VERSION ""

NS_ :

BS_:

BU_: R_STR IAVAS ADAS ADAS_GW ENM THM CHR BAT BEV BEV_GW LCT STA ABG EPS IPMS BST VDC C_ECU C_ECU_GW

BO_ 2564481198 DMS18DAE0AE: 64 IPMS
 SG_ DMS18DAE0AE_DIAG_DATA_EXT7 : 455|64@0+ (1,0) [0|1.844674407371E+19] ""  C_ECU_GW
 SG_ DMS18DAE0AE_DIAG_DATA_EXT6 : 391|64@0+ (1,0) [0|1.844674407371E+19] ""  C_ECU_GW
 SG_ DMS18DAE0AE_DIAG_DATA_EXT5 : 327|64@0+ (1,0) [0|1.844674407371E+19] ""  C_ECU_GW
 SG_ DMS18DAE0AE_DIAG_DATA_EXT4 : 263|64@0+ (1,0) [0|1.844674407371E+19] ""  C_ECU_GW
 SG_ DMS18DAE0AE_DIAG_DATA_EXT3 : 199|64@0+ (1,0) [0|1.844674407371E+19] ""  C_ECU_GW
 SG_ DMS18DAE0AE_DIAG_DATA_EXT2 : 135|64@0+ (1,0) [0|1.844674407371E+19] ""  C_ECU_GW
 SG_ DMS18DAE0AE_DIAG_DATA_EXT1 : 71|64@0+ (1,0) [0|1.844674407371E+19] ""  C_ECU_GW
 SG_ DMS18DAE0AE_DIAG_DATA : 7|64@0+ (1,0) [0|1.844674407371E+19] ""  C_ECU_GW

BO_ 2564468448 DNT18DAAEE0: 64 C_ECU_GW
 SG_ DNT18DAAEE0_DIAG_DATA_EXT7 : 455|64@0+ (1,0) [0|1.844674407371E+19] ""  IPMS
 SG_ DNT18DAAEE0_DIAG_DATA_EXT6 : 391|64@0+ (1,0) [0|1.844674407371E+19] ""  IPMS
 SG_ DNT18DAAEE0_DIAG_DATA_EXT5 : 327|64@0+ (1,0) [0|1.844674407371E+19] ""  IPMS
 SG_ DNT18DAAEE0_DIAG_DATA_EXT4 : 263|64@0+ (1,0) [0|1.844674407371E+19] ""  IPMS
 SG_ DNT18DAAEE0_DIAG_DATA_EXT3 : 199|64@0+ (1,0) [0|1.844674407371E+19] ""  IPMS
 SG_ DNT18DAAEE0_DIAG_DATA_EXT2 : 135|64@0+ (1,0) [0|1.844674407371E+19] ""  IPMS
 SG_ DNT18DAAEE0_DIAG_DATA_EXT1 : 71|64@0+ (1,0) [0|1.844674407371E+19] ""  IPMS
 SG_ DNT18DAAEE0_DIAG_DATA : 7|64@0+ (1,0) [0|1.844674407371E+19] ""  IPMS

BO_ 2564481036 BST18DAE00C: 64 BST
 SG_ BST18DAE00C_DIAG_DATA_EXT7 : 455|64@0+ (1,0) [0|1.844674407371E+19] ""  C_ECU_GW
 SG_ BST18DAE00C_DIAG_DATA_EXT6 : 391|64@0+ (1,0) [0|1.844674407371E+19] ""  C_ECU_GW
 SG_ BST18DAE00C_DIAG_DATA_EXT5 : 327|64@0+ (1,0) [0|1.844674407371E+19] ""  C_ECU_GW
 SG_ BST18DAE00C_DIAG_DATA_EXT4 : 263|64@0+ (1,0) [0|1.844674407371E+19] ""  C_ECU_GW
 SG_ BST18DAE00C_DIAG_DATA_EXT3 : 199|64@0+ (1,0) [0|1.844674407371E+19] ""  C_ECU_GW
 SG_ BST18DAE00C_DIAG_DATA_EXT2 : 135|64@0+ (1,0) [0|1.844674407371E+19] ""  C_ECU_GW
 SG_ BST18DAE00C_DIAG_DATA_EXT1 : 71|64@0+ (1,0) [0|1.844674407371E+19] ""  C_ECU_GW
 SG_ BST18DAE00C_DIAG_DATA : 7|64@0+ (1,0) [0|1.844674407371E+19] ""  C_ECU_GW

BO_ 2564426976 DNT18DA0CE0: 64 C_ECU_GW
 SG_ DNT18DA0CE0_DIAG_DATA_EXT7 : 455|64@0+ (1,0) [0|1.844674407371E+19] ""  BST
 SG_ DNT18DA0CE0_DIAG_DATA_EXT6 : 391|64@0+ (1,0) [0|1.844674407371E+19] ""  BST
 SG_ DNT18DA0CE0_DIAG_DATA_EXT5 : 327|64@0+ (1,0) [0|1.844674407371E+19] ""  BST
 SG_ DNT18DA0CE0_DIAG_DATA_EXT4 : 263|64@0+ (1,0) [0|1.844674407371E+19] ""  BST
 SG_ DNT18DA0CE0_DIAG_DATA_EXT3 : 199|64@0+ (1,0) [0|1.844674407371E+19] ""  BST
 SG_ DNT18DA0CE0_DIAG_DATA_EXT2 : 135|64@0+ (1,0) [0|1.844674407371E+19] ""  BST
 SG_ DNT18DA0CE0_DIAG_DATA_EXT1 : 71|64@0+ (1,0) [0|1.844674407371E+19] ""  BST
 SG_ DNT18DA0CE0_DIAG_DATA : 7|64@0+ (1,0) [0|1.844674407371E+19] ""  BST

BO_ 2564481153 MCA18DAE081: 64 ADAS_GW
 SG_ MCA18DAE081_DIAG_DATA_EXT7 : 455|64@0+ (1,0) [0|1.844674407371E+19] ""  C_ECU_GW
 SG_ MCA18DAE081_DIAG_DATA_EXT6 : 391|64@0+ (1,0) [0|1.844674407371E+19] ""  C_ECU_GW
 SG_ MCA18DAE081_DIAG_DATA_EXT5 : 327|64@0+ (1,0) [0|1.844674407371E+19] ""  C_ECU_GW
 SG_ MCA18DAE081_DIAG_DATA_EXT4 : 263|64@0+ (1,0) [0|1.844674407371E+19] ""  C_ECU_GW
 SG_ MCA18DAE081_DIAG_DATA_EXT3 : 199|64@0+ (1,0) [0|1.844674407371E+19] ""  C_ECU_GW
 SG_ MCA18DAE081_DIAG_DATA_EXT2 : 135|64@0+ (1,0) [0|1.844674407371E+19] ""  C_ECU_GW
 SG_ MCA18DAE081_DIAG_DATA_EXT1 : 71|64@0+ (1,0) [0|1.844674407371E+19] ""  C_ECU_GW
 SG_ MCA18DAE081_DIAG_DATA : 7|64@0+ (1,0) [0|1.844674407371E+19] ""  C_ECU_GW

BO_ 2564456928 DNT18DA81E0: 64 C_ECU_GW
 SG_ DNT18DA81E0_DIAG_DATA_EXT7 : 455|64@0+ (1,0) [0|1.844674407371E+19] ""  ADAS_GW
 SG_ DNT18DA81E0_DIAG_DATA_EXT6 : 391|64@0+ (1,0) [0|1.844674407371E+19] ""  ADAS_GW
 SG_ DNT18DA81E0_DIAG_DATA_EXT5 : 327|64@0+ (1,0) [0|1.844674407371E+19] ""  ADAS_GW
 SG_ DNT18DA81E0_DIAG_DATA_EXT4 : 263|64@0+ (1,0) [0|1.844674407371E+19] ""  ADAS_GW
 SG_ DNT18DA81E0_DIAG_DATA_EXT3 : 199|64@0+ (1,0) [0|1.844674407371E+19] ""  ADAS_GW
 SG_ DNT18DA81E0_DIAG_DATA_EXT2 : 135|64@0+ (1,0) [0|1.844674407371E+19] ""  ADAS_GW
 SG_ DNT18DA81E0_DIAG_DATA_EXT1 : 71|64@0+ (1,0) [0|1.844674407371E+19] ""  ADAS_GW
 SG_ DNT18DA81E0_DIAG_DATA : 7|64@0+ (1,0) [0|1.844674407371E+19] ""  ADAS_GW

BO_ 2564481154 FCRL18DAE082: 64 ADAS_GW
 SG_ FCRL18DAE082_DIAG_DATA_EXT7 : 455|64@0+ (1,0) [0|1.844674407371E+19] ""  C_ECU_GW
 SG_ FCRL18DAE082_DIAG_DATA_EXT6 : 391|64@0+ (1,0) [0|1.844674407371E+19] ""  C_ECU_GW
 SG_ FCRL18DAE082_DIAG_DATA_EXT5 : 327|64@0+ (1,0) [0|1.844674407371E+19] ""  C_ECU_GW
 SG_ FCRL18DAE082_DIAG_DATA_EXT4 : 263|64@0+ (1,0) [0|1.844674407371E+19] ""  C_ECU_GW
 SG_ FCRL18DAE082_DIAG_DATA_EXT3 : 199|64@0+ (1,0) [0|1.844674407371E+19] ""  C_ECU_GW
 SG_ FCRL18DAE082_DIAG_DATA_EXT2 : 135|64@0+ (1,0) [0|1.844674407371E+19] ""  C_ECU_GW
 SG_ FCRL18DAE082_DIAG_DATA_EXT1 : 71|64@0+ (1,0) [0|1.844674407371E+19] ""  C_ECU_GW
 SG_ FCRL18DAE082_DIAG_DATA : 7|64@0+ (1,0) [0|1.844674407371E+19] ""  C_ECU_GW

BO_ 2564457184 DNT18DA82E0: 64 C_ECU_GW
 SG_ DNT18DA82E0_DIAG_DATA_EXT7 : 455|64@0+ (1,0) [0|1.844674407371E+19] ""  ADAS_GW
 SG_ DNT18DA82E0_DIAG_DATA_EXT6 : 391|64@0+ (1,0) [0|1.844674407371E+19] ""  ADAS_GW
 SG_ DNT18DA82E0_DIAG_DATA_EXT5 : 327|64@0+ (1,0) [0|1.844674407371E+19] ""  ADAS_GW
 SG_ DNT18DA82E0_DIAG_DATA_EXT4 : 263|64@0+ (1,0) [0|1.844674407371E+19] ""  ADAS_GW
 SG_ DNT18DA82E0_DIAG_DATA_EXT3 : 199|64@0+ (1,0) [0|1.844674407371E+19] ""  ADAS_GW
 SG_ DNT18DA82E0_DIAG_DATA_EXT2 : 135|64@0+ (1,0) [0|1.844674407371E+19] ""  ADAS_GW
 SG_ DNT18DA82E0_DIAG_DATA_EXT1 : 71|64@0+ (1,0) [0|1.844674407371E+19] ""  ADAS_GW
 SG_ DNT18DA82E0_DIAG_DATA : 7|64@0+ (1,0) [0|1.844674407371E+19] ""  ADAS_GW

BO_ 2564481155 FCRR18DAE083: 64 ADAS_GW
 SG_ FCRR18DAE083_DIAG_DATA_EXT7 : 455|64@0+ (1,0) [0|1.844674407371E+19] ""  C_ECU_GW
 SG_ FCRR18DAE083_DIAG_DATA_EXT6 : 391|64@0+ (1,0) [0|1.844674407371E+19] ""  C_ECU_GW
 SG_ FCRR18DAE083_DIAG_DATA_EXT5 : 327|64@0+ (1,0) [0|1.844674407371E+19] ""  C_ECU_GW
 SG_ FCRR18DAE083_DIAG_DATA_EXT4 : 263|64@0+ (1,0) [0|1.844674407371E+19] ""  C_ECU_GW
 SG_ FCRR18DAE083_DIAG_DATA_EXT3 : 199|64@0+ (1,0) [0|1.844674407371E+19] ""  C_ECU_GW
 SG_ FCRR18DAE083_DIAG_DATA_EXT2 : 135|64@0+ (1,0) [0|1.844674407371E+19] ""  C_ECU_GW
 SG_ FCRR18DAE083_DIAG_DATA_EXT1 : 71|64@0+ (1,0) [0|1.844674407371E+19] ""  C_ECU_GW
 SG_ FCRR18DAE083_DIAG_DATA : 7|64@0+ (1,0) [0|1.844674407371E+19] ""  C_ECU_GW

BO_ 2564457440 DNT18DA83E0: 64 C_ECU_GW
 SG_ DNT18DA83E0_DIAG_DATA_EXT7 : 455|64@0+ (1,0) [0|1.844674407371E+19] ""  ADAS_GW
 SG_ DNT18DA83E0_DIAG_DATA_EXT6 : 391|64@0+ (1,0) [0|1.844674407371E+19] ""  ADAS_GW
 SG_ DNT18DA83E0_DIAG_DATA_EXT5 : 327|64@0+ (1,0) [0|1.844674407371E+19] ""  ADAS_GW
 SG_ DNT18DA83E0_DIAG_DATA_EXT4 : 263|64@0+ (1,0) [0|1.844674407371E+19] ""  ADAS_GW
 SG_ DNT18DA83E0_DIAG_DATA_EXT3 : 199|64@0+ (1,0) [0|1.844674407371E+19] ""  ADAS_GW
 SG_ DNT18DA83E0_DIAG_DATA_EXT2 : 135|64@0+ (1,0) [0|1.844674407371E+19] ""  ADAS_GW
 SG_ DNT18DA83E0_DIAG_DATA_EXT1 : 71|64@0+ (1,0) [0|1.844674407371E+19] ""  ADAS_GW
 SG_ DNT18DA83E0_DIAG_DATA : 7|64@0+ (1,0) [0|1.844674407371E+19] ""  ADAS_GW

BO_ 2564481107 ABG18DAE053: 8 ABG
 SG_ ABG18DAE053_DIAG_DATA : 7|64@0+ (1,0) [0|1.844674407371E+19] ""  C_ECU_GW

BO_ 2564445152 DNT18DA53E0: 8 C_ECU_GW
 SG_ DNT18DA53E0_DIAG_DATA : 7|64@0+ (1,0) [0|1.844674407371E+19] ""  ABG

BO_ 2564481101 STA18DAE04D: 64 STA
 SG_ STA18DAE04D_DIAG_DATA_EXT7 : 455|64@0+ (1,0) [0|1.844674407371E+19] ""  C_ECU_GW
 SG_ STA18DAE04D_DIAG_DATA_EXT6 : 391|64@0+ (1,0) [0|1.844674407371E+19] ""  C_ECU_GW
 SG_ STA18DAE04D_DIAG_DATA_EXT5 : 327|64@0+ (1,0) [0|1.844674407371E+19] ""  C_ECU_GW
 SG_ STA18DAE04D_DIAG_DATA_EXT4 : 263|64@0+ (1,0) [0|1.844674407371E+19] ""  C_ECU_GW
 SG_ STA18DAE04D_DIAG_DATA_EXT3 : 199|64@0+ (1,0) [0|1.844674407371E+19] ""  C_ECU_GW
 SG_ STA18DAE04D_DIAG_DATA_EXT2 : 135|64@0+ (1,0) [0|1.844674407371E+19] ""  C_ECU_GW
 SG_ STA18DAE04D_DIAG_DATA_EXT1 : 71|64@0+ (1,0) [0|1.844674407371E+19] ""  C_ECU_GW
 SG_ STA18DAE04D_DIAG_DATA : 7|64@0+ (1,0) [0|1.844674407371E+19] ""  C_ECU_GW

BO_ 2564443616 DNT18DA4DE0: 64 C_ECU_GW
 SG_ DNT18DA4DE0_DIAG_DATA_EXT7 : 455|64@0+ (1,0) [0|1.844674407371E+19] ""  STA
 SG_ DNT18DA4DE0_DIAG_DATA_EXT6 : 391|64@0+ (1,0) [0|1.844674407371E+19] ""  STA
 SG_ DNT18DA4DE0_DIAG_DATA_EXT5 : 327|64@0+ (1,0) [0|1.844674407371E+19] ""  STA
 SG_ DNT18DA4DE0_DIAG_DATA_EXT4 : 263|64@0+ (1,0) [0|1.844674407371E+19] ""  STA
 SG_ DNT18DA4DE0_DIAG_DATA_EXT3 : 199|64@0+ (1,0) [0|1.844674407371E+19] ""  STA
 SG_ DNT18DA4DE0_DIAG_DATA_EXT2 : 135|64@0+ (1,0) [0|1.844674407371E+19] ""  STA
 SG_ DNT18DA4DE0_DIAG_DATA_EXT1 : 71|64@0+ (1,0) [0|1.844674407371E+19] ""  STA
 SG_ DNT18DA4DE0_DIAG_DATA : 7|64@0+ (1,0) [0|1.844674407371E+19] ""  STA

BO_ 2564481043 EPS18DAE013: 8 EPS
 SG_ EPS18DAE013_DIAG_DATA_EXT7 : 455|64@0+ (1,0) [0|1.844674407371E+19] ""  C_ECU_GW
 SG_ EPS18DAE013_DIAG_DATA_EXT6 : 391|64@0+ (1,0) [0|1.844674407371E+19] ""  C_ECU_GW
 SG_ EPS18DAE013_DIAG_DATA_EXT5 : 327|64@0+ (1,0) [0|1.844674407371E+19] ""  C_ECU_GW
 SG_ EPS18DAE013_DIAG_DATA_EXT4 : 263|64@0+ (1,0) [0|1.844674407371E+19] ""  C_ECU_GW
 SG_ EPS18DAE013_DIAG_DATA_EXT3 : 199|64@0+ (1,0) [0|1.844674407371E+19] ""  C_ECU_GW
 SG_ EPS18DAE013_DIAG_DATA_EXT2 : 135|64@0+ (1,0) [0|1.844674407371E+19] ""  C_ECU_GW
 SG_ EPS18DAE013_DIAG_DATA_EXT1 : 71|64@0+ (1,0) [0|1.844674407371E+19] ""  C_ECU_GW
 SG_ EPS18DAE013_DIAG_DATA : 7|64@0+ (1,0) [0|1.844674407371E+19] ""  C_ECU_GW

BO_ 2564428768 DNT18DA13E0: 8 C_ECU_GW
 SG_ DNT18DA13E0_DIAG_DATA_EXT7 : 455|64@0+ (1,0) [0|1.844674407371E+19] "" Vector__XXX
 SG_ DNT18DA13E0_DIAG_DATA_EXT6 : 391|64@0+ (1,0) [0|1.844674407371E+19] "" Vector__XXX
 SG_ DNT18DA13E0_DIAG_DATA_EXT5 : 327|64@0+ (1,0) [0|1.844674407371E+19] "" Vector__XXX
 SG_ DNT18DA13E0_DIAG_DATA_EXT4 : 263|64@0+ (1,0) [0|1.844674407371E+19] "" Vector__XXX
 SG_ DNT18DA13E0_DIAG_DATA_EXT3 : 199|64@0+ (1,0) [0|1.844674407371E+19] "" Vector__XXX
 SG_ DNT18DA13E0_DIAG_DATA_EXT2 : 135|64@0+ (1,0) [0|1.844674407371E+19] "" Vector__XXX
 SG_ DNT18DA13E0_DIAG_DATA_EXT1 : 71|64@0+ (1,0) [0|1.844674407371E+19] "" Vector__XXX
 SG_ DNT18DA13E0_DIAG_DATA : 7|64@0+ (1,0) [0|1.844674407371E+19] ""  EPS

BO_ 2564481035 VDC18DAE00B: 64 VDC
 SG_ VDC18DAE00B_DIAG_DATA_EXT7 : 455|64@0+ (1,0) [0|1.844674407371E+19] ""  C_ECU_GW
 SG_ VDC18DAE00B_DIAG_DATA_EXT6 : 391|64@0+ (1,0) [0|1.844674407371E+19] ""  C_ECU_GW
 SG_ VDC18DAE00B_DIAG_DATA_EXT5 : 327|64@0+ (1,0) [0|1.844674407371E+19] ""  C_ECU_GW
 SG_ VDC18DAE00B_DIAG_DATA_EXT4 : 263|64@0+ (1,0) [0|1.844674407371E+19] ""  C_ECU_GW
 SG_ VDC18DAE00B_DIAG_DATA_EXT3 : 199|64@0+ (1,0) [0|1.844674407371E+19] ""  C_ECU_GW
 SG_ VDC18DAE00B_DIAG_DATA_EXT2 : 135|64@0+ (1,0) [0|1.844674407371E+19] ""  C_ECU_GW
 SG_ VDC18DAE00B_DIAG_DATA_EXT1 : 71|64@0+ (1,0) [0|1.844674407371E+19] ""  C_ECU_GW
 SG_ VDC18DAE00B_DIAG_DATA : 7|64@0+ (1,0) [0|1.844674407371E+19] ""  C_ECU_GW

BO_ 2564426720 DNT18DA0BE0: 64 C_ECU_GW
 SG_ DNT18DA0BE0_DIAG_DATA_EXT7 : 455|64@0+ (1,0) [0|1.844674407371E+19] ""  VDC
 SG_ DNT18DA0BE0_DIAG_DATA_EXT6 : 391|64@0+ (1,0) [0|1.844674407371E+19] ""  VDC
 SG_ DNT18DA0BE0_DIAG_DATA_EXT5 : 327|64@0+ (1,0) [0|1.844674407371E+19] ""  VDC
 SG_ DNT18DA0BE0_DIAG_DATA_EXT4 : 263|64@0+ (1,0) [0|1.844674407371E+19] ""  VDC
 SG_ DNT18DA0BE0_DIAG_DATA_EXT3 : 199|64@0+ (1,0) [0|1.844674407371E+19] ""  VDC
 SG_ DNT18DA0BE0_DIAG_DATA_EXT2 : 135|64@0+ (1,0) [0|1.844674407371E+19] ""  VDC
 SG_ DNT18DA0BE0_DIAG_DATA_EXT1 : 71|64@0+ (1,0) [0|1.844674407371E+19] ""  VDC
 SG_ DNT18DA0BE0_DIAG_DATA : 7|64@0+ (1,0) [0|1.844674407371E+19] ""  VDC

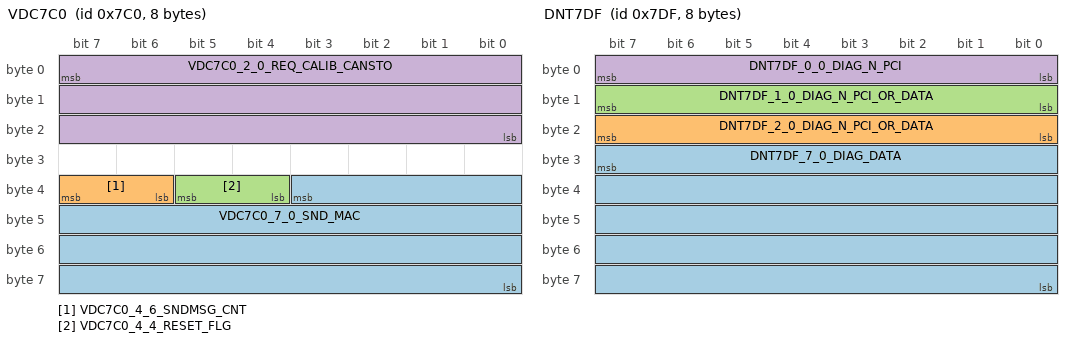
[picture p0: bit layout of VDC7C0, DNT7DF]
BO_ 1984 VDC7C0: 8 VDC
 SG_ VDC7C0_7_0_SND_MAC : 35|28@0+ (1,0) [0|268435455] ""  STA
 SG_ VDC7C0_4_6_SNDMSG_CNT : 39|2@0+ (1,0) [0|3] ""  STA
 SG_ VDC7C0_4_4_RESET_FLG : 37|2@0+ (1,0) [0|3] ""  STA
 SG_ VDC7C0_2_0_REQ_CALIB_CANSTO : 7|24@0+ (1,0) [0|16777215] ""  STA

BO_ 1955 DNT7A3: 8 C_ECU_GW
 SG_ DNT7A3_DIAG_DATA_EXT7 : 455|64@0+ (1,0) [0|1.844674407371E+19] "" Vector__XXX
 SG_ DNT7A3_DIAG_DATA_EXT6 : 391|64@0+ (1,0) [0|1.844674407371E+19] "" Vector__XXX
 SG_ DNT7A3_DIAG_DATA_EXT5 : 327|64@0+ (1,0) [0|1.844674407371E+19] "" Vector__XXX
 SG_ DNT7A3_DIAG_DATA_EXT4 : 263|64@0+ (1,0) [0|1.844674407371E+19] "" Vector__XXX
 SG_ DNT7A3_DIAG_DATA_EXT3 : 199|64@0+ (1,0) [0|1.844674407371E+19] "" Vector__XXX
 SG_ DNT7A3_DIAG_DATA_EXT2 : 135|64@0+ (1,0) [0|1.844674407371E+19] "" Vector__XXX
 SG_ DNT7A3_DIAG_DATA_EXT1 : 71|64@0+ (1,0) [0|1.844674407371E+19] "" Vector__XXX
 SG_ DNT7A3_DIAG_DATA : 7|64@0+ (1,0) [0|1.844674407371E+19] "" Vector__XXX

BO_ 2017 DNT7E1: 8 C_ECU_GW
 SG_ DNT7E1_DIAG_DATA_EXT7 : 455|64@0+ (1,0) [0|1.844674407371E+19] "" Vector__XXX
 SG_ DNT7E1_DIAG_DATA_EXT6 : 391|64@0+ (1,0) [0|1.844674407371E+19] "" Vector__XXX
 SG_ DNT7E1_DIAG_DATA_EXT5 : 327|64@0+ (1,0) [0|1.844674407371E+19] "" Vector__XXX
 SG_ DNT7E1_DIAG_DATA_EXT4 : 263|64@0+ (1,0) [0|1.844674407371E+19] "" Vector__XXX
 SG_ DNT7E1_DIAG_DATA_EXT3 : 199|64@0+ (1,0) [0|1.844674407371E+19] "" Vector__XXX
 SG_ DNT7E1_DIAG_DATA_EXT2 : 135|64@0+ (1,0) [0|1.844674407371E+19] "" Vector__XXX
 SG_ DNT7E1_DIAG_DATA_EXT1 : 71|64@0+ (1,0) [0|1.844674407371E+19] "" Vector__XXX
 SG_ DNT7E1_DIAG_DATA : 7|64@0+ (1,0) [0|1.844674407371E+19] "" Vector__XXX

BO_ 1954 DNT7A2: 8 C_ECU_GW
 SG_ DNT7A2_DIAG_DATA_EXT7 : 455|64@0+ (1,0) [0|1.844674407371E+19] "" Vector__XXX
 SG_ DNT7A2_DIAG_DATA_EXT6 : 391|64@0+ (1,0) [0|1.844674407371E+19] "" Vector__XXX
 SG_ DNT7A2_DIAG_DATA_EXT5 : 327|64@0+ (1,0) [0|1.844674407371E+19] "" Vector__XXX
 SG_ DNT7A2_DIAG_DATA_EXT4 : 263|64@0+ (1,0) [0|1.844674407371E+19] "" Vector__XXX
 SG_ DNT7A2_DIAG_DATA_EXT3 : 199|64@0+ (1,0) [0|1.844674407371E+19] "" Vector__XXX
 SG_ DNT7A2_DIAG_DATA_EXT2 : 135|64@0+ (1,0) [0|1.844674407371E+19] "" Vector__XXX
 SG_ DNT7A2_DIAG_DATA_EXT1 : 71|64@0+ (1,0) [0|1.844674407371E+19] "" Vector__XXX
 SG_ DNT7A2_DIAG_DATA : 7|64@0+ (1,0) [0|1.844674407371E+19] "" Vector__XXX

BO_ 2016 DNT7E0: 8 C_ECU_GW
 SG_ DNT7E0_DIAG_DATA_EXT7 : 455|64@0+ (1,0) [0|1.844674407371E+19] "" Vector__XXX
 SG_ DNT7E0_DIAG_DATA_EXT6 : 391|64@0+ (1,0) [0|1.844674407371E+19] "" Vector__XXX
 SG_ DNT7E0_DIAG_DATA_EXT5 : 327|64@0+ (1,0) [0|1.844674407371E+19] "" Vector__XXX
 SG_ DNT7E0_DIAG_DATA_EXT4 : 263|64@0+ (1,0) [0|1.844674407371E+19] "" Vector__XXX
 SG_ DNT7E0_DIAG_DATA_EXT3 : 199|64@0+ (1,0) [0|1.844674407371E+19] "" Vector__XXX
 SG_ DNT7E0_DIAG_DATA_EXT2 : 135|64@0+ (1,0) [0|1.844674407371E+19] "" Vector__XXX
 SG_ DNT7E0_DIAG_DATA_EXT1 : 71|64@0+ (1,0) [0|1.844674407371E+19] "" Vector__XXX
 SG_ DNT7E0_DIAG_DATA : 7|64@0+ (1,0) [0|1.844674407371E+19] "" Vector__XXX

BO_ 2564550625 CECU18DBEFE1: 8 C_ECU
 SG_ CECU18DBEFE1_DIAG_DATA : 7|64@0+ (1,0) [0|1.844674407371E+19] ""  IAVAS,ADAS,ADAS_GW,BEV,BEV_GW,LCT,STA,IPMS,BST,VDC

BO_ 2564550624 DNT18DBEFE0: 8 C_ECU_GW
 SG_ DNT18DBEFE0_DIAG_DATA : 7|64@0+ (1,0) [0|1.844674407371E+19] ""  ADAS,ADAS_GW,LCT,STA,ABG,EPS,IPMS,BST,VDC

BO_ 2015 DNT7DF: 8 C_ECU_GW
 SG_ DNT7DF_7_0_DIAG_DATA : 31|40@0+ (1,0) [0|1099511627775] "" Vector__XXX
 SG_ DNT7DF_2_0_DIAG_N_PCI_OR_DATA : 23|8@0+ (1,0) [0|255] "" Vector__XXX
 SG_ DNT7DF_1_0_DIAG_N_PCI_OR_DATA : 15|8@0+ (1,0) [0|255] "" Vector__XXX
 SG_ DNT7DF_0_0_DIAG_N_PCI : 7|8@0+ (1,0) [0|255] "" Vector__XXX

BO_ 2564481454 DMS18DAE1AE: 64 IPMS
 SG_ DMS18DAE1AE_DIAG_DATA_EXT7 : 455|64@0+ (1,0) [0|1.844674407371E+19] ""  C_ECU
 SG_ DMS18DAE1AE_DIAG_DATA_EXT6 : 391|64@0+ (1,0) [0|1.844674407371E+19] ""  C_ECU
 SG_ DMS18DAE1AE_DIAG_DATA_EXT5 : 327|64@0+ (1,0) [0|1.844674407371E+19] ""  C_ECU
 SG_ DMS18DAE1AE_DIAG_DATA_EXT4 : 263|64@0+ (1,0) [0|1.844674407371E+19] ""  C_ECU
 SG_ DMS18DAE1AE_DIAG_DATA_EXT3 : 199|64@0+ (1,0) [0|1.844674407371E+19] ""  C_ECU
 SG_ DMS18DAE1AE_DIAG_DATA_EXT2 : 135|64@0+ (1,0) [0|1.844674407371E+19] ""  C_ECU
 SG_ DMS18DAE1AE_DIAG_DATA_EXT1 : 71|64@0+ (1,0) [0|1.844674407371E+19] ""  C_ECU
 SG_ DMS18DAE1AE_DIAG_DATA : 7|64@0+ (1,0) [0|1.844674407371E+19] ""  C_ECU

BO_ 2564468449 CECU18DAAEE1: 64 C_ECU
 SG_ CECU18DAAEE1_DIAG_DATA_EXT7 : 455|64@0+ (1,0) [0|1.844674407371E+19] ""  IPMS
 SG_ CECU18DAAEE1_DIAG_DATA_EXT6 : 391|64@0+ (1,0) [0|1.844674407371E+19] ""  IPMS
 SG_ CECU18DAAEE1_DIAG_DATA_EXT5 : 327|64@0+ (1,0) [0|1.844674407371E+19] ""  IPMS
 SG_ CECU18DAAEE1_DIAG_DATA_EXT4 : 263|64@0+ (1,0) [0|1.844674407371E+19] ""  IPMS
 SG_ CECU18DAAEE1_DIAG_DATA_EXT3 : 199|64@0+ (1,0) [0|1.844674407371E+19] ""  IPMS
 SG_ CECU18DAAEE1_DIAG_DATA_EXT2 : 135|64@0+ (1,0) [0|1.844674407371E+19] ""  IPMS
 SG_ CECU18DAAEE1_DIAG_DATA_EXT1 : 71|64@0+ (1,0) [0|1.844674407371E+19] ""  IPMS
 SG_ CECU18DAAEE1_DIAG_DATA : 7|64@0+ (1,0) [0|1.844674407371E+19] ""  IPMS

BO_ 2564481409 MCA18DAE181: 64 ADAS_GW
 SG_ MCA18DAE181_DIAG_DATA_EXT7 : 455|64@0+ (1,0) [0|1.844674407371E+19] ""  C_ECU
 SG_ MCA18DAE181_DIAG_DATA_EXT6 : 391|64@0+ (1,0) [0|1.844674407371E+19] ""  C_ECU
 SG_ MCA18DAE181_DIAG_DATA_EXT5 : 327|64@0+ (1,0) [0|1.844674407371E+19] ""  C_ECU
 SG_ MCA18DAE181_DIAG_DATA_EXT4 : 263|64@0+ (1,0) [0|1.844674407371E+19] ""  C_ECU
 SG_ MCA18DAE181_DIAG_DATA_EXT3 : 199|64@0+ (1,0) [0|1.844674407371E+19] ""  C_ECU
 SG_ MCA18DAE181_DIAG_DATA_EXT2 : 135|64@0+ (1,0) [0|1.844674407371E+19] ""  C_ECU
 SG_ MCA18DAE181_DIAG_DATA_EXT1 : 71|64@0+ (1,0) [0|1.844674407371E+19] ""  C_ECU
 SG_ MCA18DAE181_DIAG_DATA : 7|64@0+ (1,0) [0|1.844674407371E+19] ""  C_ECU

BO_ 2564456929 CECU18DA81E1: 64 C_ECU
 SG_ CECU18DA81E1_DIAG_DATA_EXT7 : 455|64@0+ (1,0) [0|1.844674407371E+19] ""  ADAS_GW
 SG_ CECU18DA81E1_DIAG_DATA_EXT6 : 391|64@0+ (1,0) [0|1.844674407371E+19] ""  ADAS_GW
 SG_ CECU18DA81E1_DIAG_DATA_EXT5 : 327|64@0+ (1,0) [0|1.844674407371E+19] ""  ADAS_GW
 SG_ CECU18DA81E1_DIAG_DATA_EXT4 : 263|64@0+ (1,0) [0|1.844674407371E+19] ""  ADAS_GW
 SG_ CECU18DA81E1_DIAG_DATA_EXT3 : 199|64@0+ (1,0) [0|1.844674407371E+19] ""  ADAS_GW
 SG_ CECU18DA81E1_DIAG_DATA_EXT2 : 135|64@0+ (1,0) [0|1.844674407371E+19] ""  ADAS_GW
 SG_ CECU18DA81E1_DIAG_DATA_EXT1 : 71|64@0+ (1,0) [0|1.844674407371E+19] ""  ADAS_GW
 SG_ CECU18DA81E1_DIAG_DATA : 7|64@0+ (1,0) [0|1.844674407371E+19] ""  ADAS_GW

BO_ 2564481477 BEV18DAE1C5: 64 BEV
 SG_ BEV18DAE1C5_DIAG_DATA_EXT7 : 455|64@0+ (1,0) [0|1.844674407371E+19] ""  C_ECU
 SG_ BEV18DAE1C5_DIAG_DATA_EXT6 : 391|64@0+ (1,0) [0|1.844674407371E+19] ""  C_ECU
 SG_ BEV18DAE1C5_DIAG_DATA_EXT5 : 327|64@0+ (1,0) [0|1.844674407371E+19] ""  C_ECU
 SG_ BEV18DAE1C5_DIAG_DATA_EXT4 : 263|64@0+ (1,0) [0|1.844674407371E+19] ""  C_ECU
 SG_ BEV18DAE1C5_DIAG_DATA_EXT3 : 199|64@0+ (1,0) [0|1.844674407371E+19] ""  C_ECU
 SG_ BEV18DAE1C5_DIAG_DATA_EXT2 : 135|64@0+ (1,0) [0|1.844674407371E+19] ""  C_ECU
 SG_ BEV18DAE1C5_DIAG_DATA_EXT1 : 71|64@0+ (1,0) [0|1.844674407371E+19] ""  C_ECU
 SG_ BEV18DAE1C5_DIAG_DATA : 7|64@0+ (1,0) [0|1.844674407371E+19] ""  C_ECU

BO_ 2564474337 CECU18DAC5E1: 64 C_ECU
 SG_ CECU18DAC5E1_DIAG_DATA_EXT7 : 455|64@0+ (1,0) [0|1.844674407371E+19] ""  BEV
 SG_ CECU18DAC5E1_DIAG_DATA_EXT6 : 391|64@0+ (1,0) [0|1.844674407371E+19] ""  BEV
 SG_ CECU18DAC5E1_DIAG_DATA_EXT5 : 327|64@0+ (1,0) [0|1.844674407371E+19] ""  BEV
 SG_ CECU18DAC5E1_DIAG_DATA_EXT4 : 263|64@0+ (1,0) [0|1.844674407371E+19] ""  BEV
 SG_ CECU18DAC5E1_DIAG_DATA_EXT3 : 199|64@0+ (1,0) [0|1.844674407371E+19] ""  BEV
 SG_ CECU18DAC5E1_DIAG_DATA_EXT2 : 135|64@0+ (1,0) [0|1.844674407371E+19] ""  BEV
 SG_ CECU18DAC5E1_DIAG_DATA_EXT1 : 71|64@0+ (1,0) [0|1.844674407371E+19] ""  BEV
 SG_ CECU18DAC5E1_DIAG_DATA : 7|64@0+ (1,0) [0|1.844674407371E+19] ""  BEV

BO_ 2564481299 EPS18DAE113: 8 EPS
 SG_ EPS18DAE113_DIAG_DATA : 7|64@0+ (1,0) [0|1.844674407371E+19] ""  C_ECU

BO_ 2564428769 CECU18DA13E1: 8 C_ECU
 SG_ CECU18DA13E1_DIAG_DATA : 7|64@0+ (1,0) [0|1.844674407371E+19] ""  EPS

BO_ 2564481292 BST18DAE10C: 64 BST
 SG_ BST18DAE10C_DIAG_DATA_EXT7 : 455|64@0+ (1,0) [0|1.844674407371E+19] ""  C_ECU
 SG_ BST18DAE10C_DIAG_DATA_EXT6 : 391|64@0+ (1,0) [0|1.844674407371E+19] ""  C_ECU
 SG_ BST18DAE10C_DIAG_DATA_EXT5 : 327|64@0+ (1,0) [0|1.844674407371E+19] ""  C_ECU
 SG_ BST18DAE10C_DIAG_DATA_EXT4 : 263|64@0+ (1,0) [0|1.844674407371E+19] ""  C_ECU
 SG_ BST18DAE10C_DIAG_DATA_EXT3 : 199|64@0+ (1,0) [0|1.844674407371E+19] ""  C_ECU
 SG_ BST18DAE10C_DIAG_DATA_EXT2 : 135|64@0+ (1,0) [0|1.844674407371E+19] ""  C_ECU
 SG_ BST18DAE10C_DIAG_DATA_EXT1 : 71|64@0+ (1,0) [0|1.844674407371E+19] ""  C_ECU
 SG_ BST18DAE10C_DIAG_DATA : 7|64@0+ (1,0) [0|1.844674407371E+19] ""  C_ECU

BO_ 2564426977 CECU18DA0CE1: 64 C_ECU
 SG_ CECU18DA0CE1_DIAG_DATA : 7|64@0+ (1,0) [0|1.844674407371E+19] ""  BST

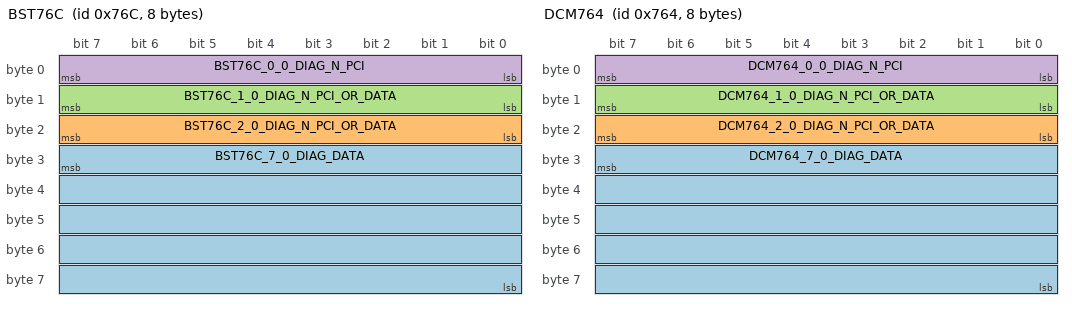
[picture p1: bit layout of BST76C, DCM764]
BO_ 1900 BST76C: 8 BST
 SG_ BST76C_7_0_DIAG_DATA : 31|40@0+ (1,0) [0|1099511627775] "" Vector__XXX
 SG_ BST76C_2_0_DIAG_N_PCI_OR_DATA : 23|8@0+ (1,0) [0|255] "" Vector__XXX
 SG_ BST76C_1_0_DIAG_N_PCI_OR_DATA : 15|8@0+ (1,0) [0|255] "" Vector__XXX
 SG_ BST76C_0_0_DIAG_N_PCI : 7|8@0+ (1,0) [0|255] "" Vector__XXX

BO_ 1892 DCM764: 8 C_ECU_GW
 SG_ DCM764_7_0_DIAG_DATA : 31|40@0+ (1,0) [0|1099511627775] ""  BST
 SG_ DCM764_2_0_DIAG_N_PCI_OR_DATA : 23|8@0+ (1,0) [0|255] ""  BST
 SG_ DCM764_1_0_DIAG_N_PCI_OR_DATA : 15|8@0+ (1,0) [0|255] ""  BST
 SG_ DCM764_0_0_DIAG_N_PCI : 7|8@0+ (1,0) [0|255] ""  BST

BO_ 2564481291 VDC18DAE10B: 64 VDC
 SG_ VDC18DAE10B_DIAG_DATA_EXT7 : 455|64@0+ (1,0) [0|1.844674407371E+19] ""  C_ECU
 SG_ VDC18DAE10B_DIAG_DATA_EXT6 : 391|64@0+ (1,0) [0|1.844674407371E+19] ""  C_ECU
 SG_ VDC18DAE10B_DIAG_DATA_EXT5 : 327|64@0+ (1,0) [0|1.844674407371E+19] ""  C_ECU
 SG_ VDC18DAE10B_DIAG_DATA_EXT4 : 263|64@0+ (1,0) [0|1.844674407371E+19] ""  C_ECU
 SG_ VDC18DAE10B_DIAG_DATA_EXT3 : 199|64@0+ (1,0) [0|1.844674407371E+19] ""  C_ECU
 SG_ VDC18DAE10B_DIAG_DATA_EXT2 : 135|64@0+ (1,0) [0|1.844674407371E+19] ""  C_ECU
 SG_ VDC18DAE10B_DIAG_DATA_EXT1 : 71|64@0+ (1,0) [0|1.844674407371E+19] ""  C_ECU
 SG_ VDC18DAE10B_DIAG_DATA : 7|64@0+ (1,0) [0|1.844674407371E+19] ""  C_ECU

BO_ 2564426721 CECU18DA0BE1: 64 C_ECU
 SG_ CECU18DA0BE1_DIAG_DATA : 7|64@0+ (1,0) [0|1.844674407371E+19] ""  VDC

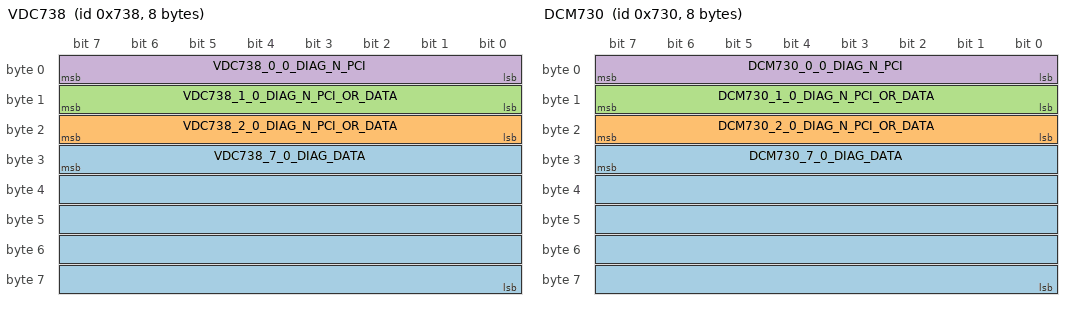
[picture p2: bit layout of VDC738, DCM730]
BO_ 1848 VDC738: 8 VDC
 SG_ VDC738_7_0_DIAG_DATA : 31|40@0+ (1,0) [0|1099511627775] ""  C_ECU_GW
 SG_ VDC738_2_0_DIAG_N_PCI_OR_DATA : 23|8@0+ (1,0) [0|255] ""  C_ECU_GW
 SG_ VDC738_1_0_DIAG_N_PCI_OR_DATA : 15|8@0+ (1,0) [0|255] ""  C_ECU_GW
 SG_ VDC738_0_0_DIAG_N_PCI : 7|8@0+ (1,0) [0|255] ""  C_ECU_GW

BO_ 1840 DCM730: 8 C_ECU_GW
 SG_ DCM730_7_0_DIAG_DATA : 31|40@0+ (1,0) [0|1099511627775] ""  VDC
 SG_ DCM730_2_0_DIAG_N_PCI_OR_DATA : 23|8@0+ (1,0) [0|255] ""  VDC
 SG_ DCM730_1_0_DIAG_N_PCI_OR_DATA : 15|8@0+ (1,0) [0|255] ""  VDC
 SG_ DCM730_0_0_DIAG_N_PCI : 7|8@0+ (1,0) [0|255] ""  VDC

BO_ 2564481363 ABG18DAE153: 8 ABG
 SG_ ABG18DAE153_DIAG_DATA : 7|64@0+ (1,0) [0|1.844674407371E+19] ""  C_ECU

BO_ 2564445153 CECU18DA53E1: 8 C_ECU
 SG_ CECU18DA53E1_DIAG_DATA : 7|64@0+ (1,0) [0|1.844674407371E+19] ""  ABG

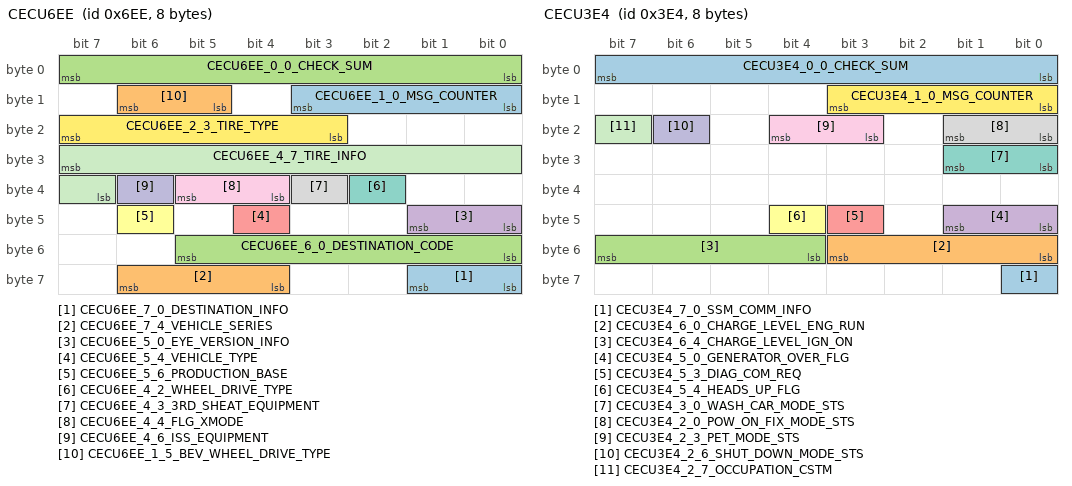
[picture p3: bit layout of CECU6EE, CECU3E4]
BO_ 1774 CECU6EE: 8 C_ECU
 SG_ CECU6EE_7_0_DESTINATION_INFO : 57|2@0+ (1,0) [0|3] "" Vector__XXX
 SG_ CECU6EE_7_4_VEHICLE_SERIES : 62|3@0+ (1,0) [0|7] "" Vector__XXX
 SG_ CECU6EE_6_0_DESTINATION_CODE : 53|6@0+ (1,0) [0|37] ""  IAVAS
 SG_ CECU6EE_5_0_EYE_VERSION_INFO : 41|2@0+ (1,0) [0|3] "" Vector__XXX
 SG_ CECU6EE_5_4_VEHICLE_TYPE : 44|1@0+ (1,0) [0|1] "" Vector__XXX
 SG_ CECU6EE_5_6_PRODUCTION_BASE : 46|1@0+ (1,0) [0|1] "" Vector__XXX
 SG_ CECU6EE_4_2_WHEEL_DRIVE_TYPE : 34|1@0+ (1,0) [0|1] "" Vector__XXX
 SG_ CECU6EE_4_3_3RD_SHEAT_EQUIPMENT : 35|1@0+ (1,0) [0|1] "" Vector__XXX
 SG_ CECU6EE_4_4_FLG_XMODE : 37|2@0+ (1,0) [0|3] "" Vector__XXX
 SG_ CECU6EE_4_6_ISS_EQUIPMENT : 38|1@0+ (1,0) [0|1] "" Vector__XXX
 SG_ CECU6EE_4_7_TIRE_INFO : 31|9@0+ (1,0) [0|381] "" Vector__XXX
 SG_ CECU6EE_2_3_TIRE_TYPE : 23|5@0+ (1,0) [0|511] "" Vector__XXX
 SG_ CECU6EE_1_0_MSG_COUNTER : 11|4@0+ (1,0) [0|15] ""  IAVAS
 SG_ CECU6EE_1_5_BEV_WHEEL_DRIVE_TYPE : 14|2@0+ (1,0) [0|3] "" Vector__XXX
 SG_ CECU6EE_0_0_CHECK_SUM : 7|8@0+ (1,0) [0|255] ""  IAVAS

BO_ 1773 CECU6ED: 8 C_ECU
 SG_ CECU6ED_7_0_VEHICLE_TYPE_DETAIL : 59|4@0+ (1,0) [0|15] ""  IAVAS
 SG_ CECU6ED_7_7_STEERHEAT_EQUIPMENT : 63|1@0+ (1,0) [0|1] "" Vector__XXX
 SG_ CECU6ED_6_0_SRH_EQUIPMENT : 48|1@0+ (1,0) [0|1] "" Vector__XXX
 SG_ CECU6ED_6_1_EMBENAVI_EQUIPMENT : 49|1@0+ (1,0) [0|1] "" Vector__XXX
 SG_ CECU6ED_6_2_RAB_EQUIPMENT_INFO : 50|1@0+ (1,0) [0|1] "" Vector__XXX
 SG_ CECU6ED_6_3_RRHEACON_EQUIPMENT : 51|1@0+ (1,0) [0|1] "" Vector__XXX
 SG_ CECU6ED_6_4_AUTOMIRROR_EQUIPMENT : 52|1@0+ (1,0) [0|1] "" Vector__XXX
 SG_ CECU6ED_6_5_SXMANTENNA_EQUIPMENT : 53|1@0+ (1,0) [0|1] "" Vector__XXX
 SG_ CECU6ED_6_7_SPORTSCONT_EQUIPMENT : 55|1@0+ (1,0) [0|1] "" Vector__XXX
 SG_ CECU6ED_5_0_TRANSMISSION_TYPE : 40|1@0+ (1,0) [0|1] "" Vector__XXX
 SG_ CECU6ED_5_2_KICKSENSOR_EQUIPMENT : 42|1@0+ (1,0) [0|1] "" Vector__XXX
 SG_ CECU6ED_5_3_RRSEAT_OCCUPANT : 43|1@0+ (1,0) [0|1] "" Vector__XXX
 SG_ CECU6ED_5_4_HANDLE : 44|1@0+ (1,0) [0|1] "" Vector__XXX
 SG_ CECU6ED_5_5_RRWIPER_EQUIPMENT : 45|1@0+ (1,0) [0|1] "" Vector__XXX
 SG_ CECU6ED_5_7_SRM_EQUIPMENT : 47|1@0+ (1,0) [0|1] "" Vector__XXX
 SG_ CECU6ED_4_0_VEHICLE_HEIGHT : 34|3@0+ (1,0) [0|7] "" Vector__XXX
 SG_ CECU6ED_4_4_SEATHEATER_EQUIPMENT : 37|2@0+ (1,0) [0|3] "" Vector__XXX
 SG_ CECU6ED_3_0_YEAR_CHANGE : 27|4@0+ (1,0) [0|15] "" Vector__XXX
 SG_ CECU6ED_3_4_HEV_INFO : 30|3@0+ (1,0) [0|7] "" Vector__XXX
 SG_ CECU6ED_2_0_RRDIFF_TEMPLAMP_INFO : 17|2@0+ (1,0) [0|3] "" Vector__XXX
 SG_ CECU6ED_2_2_AHL_EQUIPMENT : 19|2@0+ (1,0) [0|3] "" Vector__XXX
 SG_ CECU6ED_2_4_LSD_TYPE : 23|4@0+ (1,0) [0|15] "" Vector__XXX
 SG_ CECU6ED_1_0_MSG_COUNTER : 11|4@0+ (1,0) [0|15] ""  IAVAS
 SG_ CECU6ED_1_5_WARNINGBOX_EQUIPMENT : 13|1@0+ (1,0) [0|1] "" Vector__XXX
 SG_ CECU6ED_0_0_CHECK_SUM : 7|8@0+ (1,0) [0|255] ""  IAVAS

BO_ 996 CECU3E4: 8 C_ECU
 SG_ CECU3E4_7_0_SSM_COMM_INFO : 56|1@0+ (1,0) [0|1] "" Vector__XXX
 SG_ CECU3E4_6_0_CHARGE_LEVEL_ENG_RUN : 51|4@0+ (1,0) [0|9] "" Vector__XXX
 SG_ CECU3E4_6_4_CHARGE_LEVEL_IGN_ON : 55|4@0+ (1,0) [0|9] "" Vector__XXX
 SG_ CECU3E4_5_0_GENERATOR_OVER_FLG : 41|2@0+ (1,0) [0|3] "" Vector__XXX
 SG_ CECU3E4_5_3_DIAG_COM_REQ : 43|1@0+ (1,0) [0|1] "" Vector__XXX
 SG_ CECU3E4_5_4_HEADS_UP_FLG : 44|1@0+ (1,0) [0|1] "" Vector__XXX
 SG_ CECU3E4_3_0_WASH_CAR_MODE_STS : 25|2@0+ (1,0) [0|3] ""  CHR
 SG_ CECU3E4_2_0_POW_ON_FIX_MODE_STS : 17|2@0+ (1,0) [0|3] "" Vector__XXX
 SG_ CECU3E4_2_3_PET_MODE_STS : 20|2@0+ (1,0) [0|3] "" Vector__XXX
 SG_ CECU3E4_2_6_SHUT_DOWN_MODE_STS : 22|1@0+ (1,0) [0|1] "" Vector__XXX
 SG_ CECU3E4_2_7_OCCUPATION_CSTM : 23|1@0+ (1,0) [0|1] "" Vector__XXX
 SG_ CECU3E4_1_0_MSG_COUNTER : 11|4@0+ (1,0) [0|15] "" Vector__XXX
 SG_ CECU3E4_0_0_CHECK_SUM : 7|8@0+ (1,0) [0|255] "" Vector__XXX

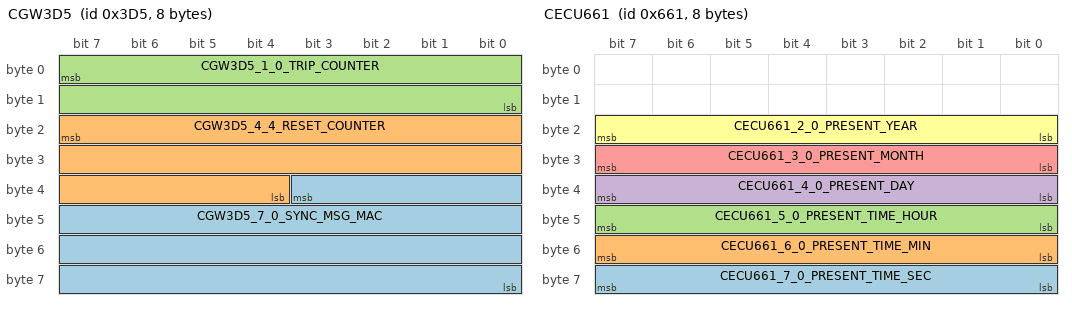
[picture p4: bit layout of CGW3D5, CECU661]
BO_ 981 CGW3D5: 8 C_ECU
 SG_ CGW3D5_7_0_SYNC_MSG_MAC : 35|28@0+ (1,0) [0|268435455] ""  ADAS,ADAS_GW,STA,EPS,VDC
 SG_ CGW3D5_4_4_RESET_COUNTER : 23|20@0+ (1,0) [0|1048575] ""  ADAS,ADAS_GW,STA,EPS,VDC
 SG_ CGW3D5_1_0_TRIP_COUNTER : 7|16@0+ (1,0) [0|65535] ""  ADAS,ADAS_GW,STA,EPS,VDC

BO_ 1280 CGW500: 8 C_ECU
 SG_ CGW500_1_4_ActiveWakeUpBit : 12|1@1+ (1,0) [0|1] ""  IAVAS,IPMS,BST
 SG_ CGW500_0_0_SourceNodeID : 0|8@1+ (1,0) [0|255] ""  IAVAS,IPMS,BST

BO_ 1633 CECU661: 8 C_ECU
 SG_ CECU661_7_0_PRESENT_TIME_SEC : 63|8@0+ (1,0) [0|89] "s"  ADAS,ADAS_GW,STA,ABG,EPS,IPMS,BST,VDC
 SG_ CECU661_6_0_PRESENT_TIME_MIN : 55|8@0+ (1,0) [0|89] "m"  ADAS,ADAS_GW,STA,ABG,EPS,IPMS,BST,VDC
 SG_ CECU661_5_0_PRESENT_TIME_HOUR : 47|8@0+ (1,0) [0|35] "h"  ADAS,ADAS_GW,STA,ABG,EPS,IPMS,BST,VDC
 SG_ CECU661_4_0_PRESENT_DAY : 39|8@0+ (1,0) [1|49] "Day"  ADAS,ADAS_GW,STA,ABG,EPS,IPMS,BST,VDC
 SG_ CECU661_3_0_PRESENT_MONTH : 31|8@0+ (1,0) [1|18] "Month"  ADAS,ADAS_GW,STA,ABG,EPS,IPMS,BST,VDC
 SG_ CECU661_2_0_PRESENT_YEAR : 23|8@0+ (1,0) [0|153] "Year"  ADAS,ADAS_GW,STA,ABG,EPS,IPMS,BST,VDC

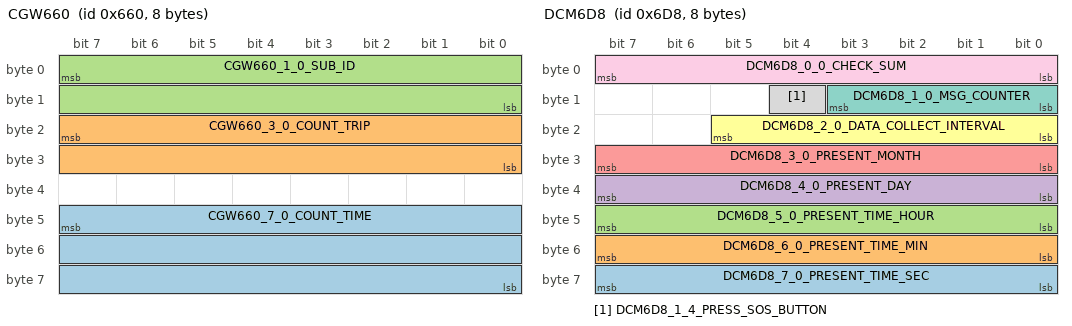
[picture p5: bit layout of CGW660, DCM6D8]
BO_ 1632 CGW660: 8 C_ECU
 SG_ CGW660_7_0_COUNT_TIME : 47|24@0+ (100,0) [0|1677721400] "ms"  IAVAS,ADAS,ADAS_GW,BEV,BEV_GW,LCT,STA,ABG,EPS,IPMS,BST,VDC
 SG_ CGW660_3_0_COUNT_TRIP : 23|16@0+ (1,0) [0|65534] "trip"  IAVAS,ADAS,ADAS_GW,BEV,BEV_GW,LCT,STA,ABG,EPS,IPMS,BST,VDC
 SG_ CGW660_1_0_SUB_ID : 7|16@0+ (1,0) [0|65535] ""  ADAS_GW,BEV,BEV_GW,LCT

BO_ 1752 DCM6D8: 8 C_ECU_GW
 SG_ DCM6D8_7_0_PRESENT_TIME_SEC : 56|8@1+ (1,0) [0|255] "s" Vector__XXX
 SG_ DCM6D8_6_0_PRESENT_TIME_MIN : 48|8@1+ (1,0) [0|255] "m" Vector__XXX
 SG_ DCM6D8_5_0_PRESENT_TIME_HOUR : 40|8@1+ (1,0) [0|255] "h" Vector__XXX
 SG_ DCM6D8_4_0_PRESENT_DAY : 32|8@1+ (1,0) [0|255] "Day" Vector__XXX
 SG_ DCM6D8_3_0_PRESENT_MONTH : 24|8@1+ (1,0) [0|255] "Month" Vector__XXX
 SG_ DCM6D8_2_0_DATA_COLLECT_INTERVAL : 16|6@1+ (1,0) [0|63] "min" Vector__XXX
 SG_ DCM6D8_1_0_MSG_COUNTER : 8|4@1+ (1,0) [0|15] ""  ADAS,BEV
 SG_ DCM6D8_1_4_PRESS_SOS_BUTTON : 12|1@1+ (1,0) [0|1] ""  ADAS
 SG_ DCM6D8_0_0_CHECK_SUM : 0|8@1+ (1,0) [0|255] ""  ADAS,BEV

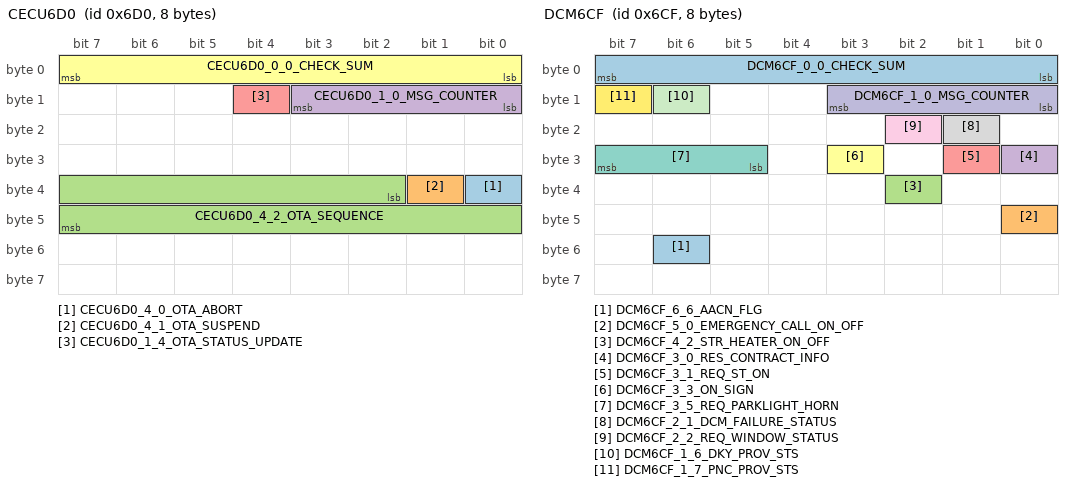
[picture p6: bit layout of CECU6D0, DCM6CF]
BO_ 1744 CECU6D0: 8 C_ECU
 SG_ CECU6D0_4_0_OTA_ABORT : 32|1@1+ (1,0) [0|1] "" Vector__XXX
 SG_ CECU6D0_4_1_OTA_SUSPEND : 33|1@1+ (1,0) [0|1] "" Vector__XXX
 SG_ CECU6D0_4_2_OTA_SEQUENCE : 34|14@1+ (1,0) [0|33170] "" Vector__XXX
 SG_ CECU6D0_1_0_MSG_COUNTER : 8|4@1+ (1,0) [0|15] ""  LCT
 SG_ CECU6D0_1_4_OTA_STATUS_UPDATE : 12|1@1+ (1,0) [0|0] ""  LCT
 SG_ CECU6D0_0_0_CHECK_SUM : 0|8@1+ (1,0) [0|255] ""  LCT

BO_ 1743 DCM6CF: 8 C_ECU_GW
 SG_ DCM6CF_6_6_AACN_FLG : 54|1@1+ (1,0) [0|1] ""  ABG
 SG_ DCM6CF_5_0_EMERGENCY_CALL_ON_OFF : 40|1@1+ (1,0) [0|1] ""  ADAS
 SG_ DCM6CF_4_2_STR_HEATER_ON_OFF : 34|1@1+ (1,0) [0|1] "" Vector__XXX
 SG_ DCM6CF_3_0_RES_CONTRACT_INFO : 24|1@1+ (1,0) [0|1] "" Vector__XXX
 SG_ DCM6CF_3_1_REQ_ST_ON : 25|1@1+ (1,0) [0|1] "" Vector__XXX
 SG_ DCM6CF_3_3_ON_SIGN : 27|1@1+ (1,0) [0|1] "" Vector__XXX
 SG_ DCM6CF_3_5_REQ_PARKLIGHT_HORN : 29|3@1+ (1,0) [0|7] "" Vector__XXX
 SG_ DCM6CF_2_1_DCM_FAILURE_STATUS : 17|1@1+ (1,0) [0|1] ""  ADAS
 SG_ DCM6CF_2_2_REQ_WINDOW_STATUS : 18|1@1+ (1,0) [0|1] "" Vector__XXX
 SG_ DCM6CF_1_0_MSG_COUNTER : 8|4@1+ (1,0) [0|15] ""  ADAS,ABG
 SG_ DCM6CF_1_6_DKY_PROV_STS : 14|1@1+ (1,0) [0|1] "" Vector__XXX
 SG_ DCM6CF_1_7_PNC_PROV_STS : 15|1@1+ (1,0) [0|1] "" Vector__XXX
 SG_ DCM6CF_0_0_CHECK_SUM : 0|8@1+ (1,0) [0|255] ""  ADAS,ABG

BO_ 1749 CECU6D5: 8 C_ECU
 SG_ CECU6D5_6_0_CSTM_FMHD : 48|3@1+ (1,0) [0|7] "" Vector__XXX
 SG_ CECU6D5_5_0_CSTM_WRH : 40|1@1+ (1,0) [0|1] "" Vector__XXX
 SG_ CECU6D5_5_1_CSTM_LMHD : 41|2@1+ (1,0) [0|3] "" Vector__XXX
 SG_ CECU6D5_5_3 : 43|2@1+ (1,0) [0|3] "" Vector__XXX
 SG_ CECU6D5_5_5_CSTM_HBA : 45|2@1+ (1,0) [0|3] "" Vector__XXX
 SG_ CECU6D5_5_7_ADB_ACTIVE : 47|1@1+ (1,0) [0|1] "" Vector__XXX
 SG_ CECU6D5_4_0_JUDGE_ILL : 32|1@1+ (1,0) [0|1] "" Vector__XXX
 SG_ CECU6D5_4_1_HEADLAMP_AUTO_SW : 33|1@1+ (1,0) [0|1] "" Vector__XXX
 SG_ CECU6D5_4_2_IND_ACTIVE_HBA : 34|2@1+ (1,0) [0|3] "" Vector__XXX
 SG_ CECU6D5_4_4_FGT_LGTOFF_WARNING : 36|1@1+ (1,0) [0|1] "" Vector__XXX
 SG_ CECU6D5_3_0_CRN_R_REQ : 24|2@1+ (1,0) [0|3] "" Vector__XXX
 SG_ CECU6D5_3_2_CRN_L_REQ : 26|2@1+ (1,0) [0|3] "" Vector__XXX
 SG_ CECU6D5_3_4_FMH : 28|1@1+ (1,0) [0|1] "" Vector__XXX
 SG_ CECU6D5_3_5_LMH : 29|1@1+ (1,0) [0|1] "" Vector__XXX
 SG_ CECU6D5_2_0_LGT_1 : 16|1@1+ (1,0) [0|1] "" Vector__XXX
 SG_ CECU6D5_2_1_LGT_LO : 17|1@1+ (1,0) [0|1] "" Vector__XXX
 SG_ CECU6D5_2_2_LGT_HI : 18|2@1+ (1,0) [0|1] "" Vector__XXX
 SG_ CECU6D5_2_4_FFOG_RELAY_REQ : 20|1@1+ (1,0) [0|1] "" Vector__XXX
 SG_ CECU6D5_2_5_RFOG_RELAY_REQ : 21|1@1+ (1,0) [0|1] "" Vector__XXX
 SG_ CECU6D5_2_6_LGT_DRL : 22|1@1+ (1,0) [0|1] "" Vector__XXX
 SG_ CECU6D5_1_0_MSG_COUNTER : 8|4@1+ (1,0) [0|15] "" Vector__XXX
 SG_ CECU6D5_0_0_CHECK_SUM : 0|8@1+ (1,0) [0|255] "" Vector__XXX

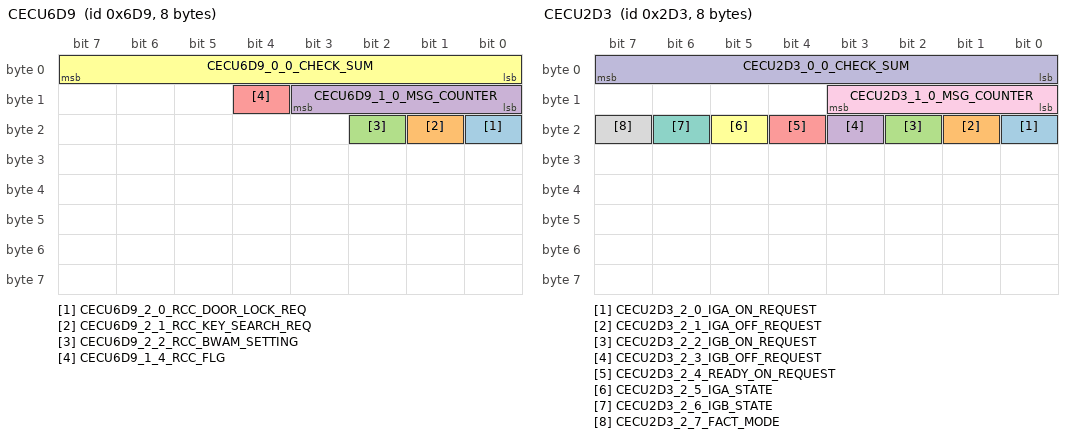
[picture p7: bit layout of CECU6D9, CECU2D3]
BO_ 1753 CECU6D9: 8 C_ECU
 SG_ CECU6D9_2_0_RCC_DOOR_LOCK_REQ : 16|1@1+ (1,0) [0|1] "" Vector__XXX
 SG_ CECU6D9_2_1_RCC_KEY_SEARCH_REQ : 17|1@1+ (1,0) [0|1] "" Vector__XXX
 SG_ CECU6D9_2_2_RCC_BWAM_SETTING : 18|1@1+ (1,0) [0|1] ""  ENM
 SG_ CECU6D9_1_0_MSG_COUNTER : 8|4@1+ (1,0) [0|15] ""  BEV
 SG_ CECU6D9_1_4_RCC_FLG : 12|1@1+ (1,0) [0|1] ""  ENM,BEV
 SG_ CECU6D9_0_0_CHECK_SUM : 0|8@1+ (1,0) [0|255] ""  BEV

BO_ 723 CECU2D3: 8 C_ECU
 SG_ CECU2D3_2_0_IGA_ON_REQUEST : 16|1@1+ (1,0) [0|1] "" Vector__XXX
 SG_ CECU2D3_2_1_IGA_OFF_REQUEST : 17|1@1+ (1,0) [0|1] "" Vector__XXX
 SG_ CECU2D3_2_2_IGB_ON_REQUEST : 18|1@1+ (1,0) [0|1] "" Vector__XXX
 SG_ CECU2D3_2_3_IGB_OFF_REQUEST : 19|1@1+ (1,0) [0|1] "" Vector__XXX
 SG_ CECU2D3_2_4_READY_ON_REQUEST : 20|1@1+ (1,0) [0|1] "" Vector__XXX
 SG_ CECU2D3_2_5_IGA_STATE : 21|1@1+ (1,0) [0|1] ""  IAVAS,ENM
 SG_ CECU2D3_2_6_IGB_STATE : 22|1@1+ (1,0) [0|1] ""  IAVAS,ENM
 SG_ CECU2D3_2_7_FACT_MODE : 23|1@1+ (1,0) [0|1] ""  ADAS
 SG_ CECU2D3_1_0_MSG_COUNTER : 8|4@1+ (1,0) [0|15] ""  IAVAS,ENM
 SG_ CECU2D3_0_0_CHECK_SUM : 0|8@1+ (1,0) [0|255] ""  IAVAS,ENM

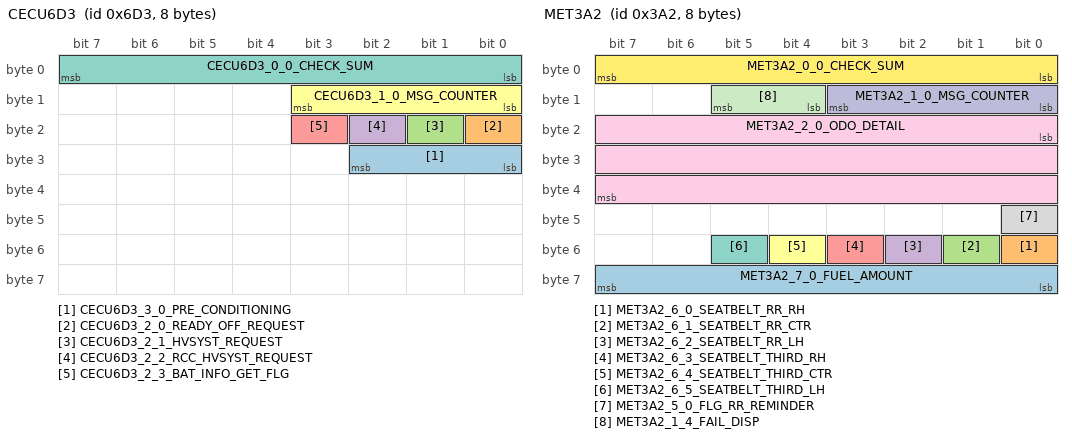
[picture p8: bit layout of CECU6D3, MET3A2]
BO_ 1747 CECU6D3: 8 C_ECU
 SG_ CECU6D3_3_0_PRE_CONDITIONING : 24|3@1+ (1,0) [0|7] ""  ENM,BEV
 SG_ CECU6D3_2_0_READY_OFF_REQUEST : 16|1@1+ (1,0) [0|1] ""  BEV
 SG_ CECU6D3_2_1_HVSYST_REQUEST : 17|1@1+ (1,0) [0|1] ""  BEV
 SG_ CECU6D3_2_2_RCC_HVSYST_REQUEST : 18|1@1+ (1,0) [0|1] ""  BEV
 SG_ CECU6D3_2_3_BAT_INFO_GET_FLG : 19|1@1+ (1,0) [0|1] ""  BEV
 SG_ CECU6D3_1_0_MSG_COUNTER : 8|4@1+ (1,0) [0|15] ""  BEV
 SG_ CECU6D3_0_0_CHECK_SUM : 0|8@1+ (1,0) [0|255] ""  BEV

BO_ 930 MET3A2: 8 C_ECU_GW
 SG_ MET3A2_7_0_FUEL_AMOUNT : 56|8@1+ (1,0) [0|100] "%" Vector__XXX
 SG_ MET3A2_6_0_SEATBELT_RR_RH : 48|1@1+ (1,0) [0|1] ""  ABG
 SG_ MET3A2_6_1_SEATBELT_RR_CTR : 49|1@1+ (1,0) [0|1] ""  ABG
 SG_ MET3A2_6_2_SEATBELT_RR_LH : 50|1@1+ (1,0) [0|1] ""  ABG
 SG_ MET3A2_6_3_SEATBELT_THIRD_RH : 51|1@1+ (1,0) [0|1] "" Vector__XXX
 SG_ MET3A2_6_4_SEATBELT_THIRD_CTR : 52|1@1+ (1,0) [0|1] "" Vector__XXX
 SG_ MET3A2_6_5_SEATBELT_THIRD_LH : 53|1@1+ (1,0) [0|1] "" Vector__XXX
 SG_ MET3A2_5_0_FLG_RR_REMINDER : 40|1@1+ (1,0) [0|1] "" Vector__XXX
 SG_ MET3A2_2_0_ODO_DETAIL : 16|24@1+ (0.1,0) [0|1609103.5] "km" Vector__XXX
 SG_ MET3A2_1_0_MSG_COUNTER : 8|4@1+ (1,0) [0|15] ""  ADAS,ABG
 SG_ MET3A2_1_4_FAIL_DISP : 12|2@1+ (1,0) [0|3] ""  ADAS
 SG_ MET3A2_0_0_CHECK_SUM : 0|8@1+ (1,0) [0|255] ""  ADAS,ABG

BO_ 1677 MET68D: 8 C_ECU_GW
 SG_ MET68D_7_0_STATUS_WASHER_LAMP : 56|1@1+ (1,0) [0|1] "" Vector__XXX
 SG_ MET68D_7_1_OILPRESSURE_SW : 57|1@1+ (1,0) [0|1] "" Vector__XXX
 SG_ MET68D_7_2_FLG_EAM : 58|1@1+ (1,0) [0|1] "" Vector__XXX
 SG_ MET68D_7_3_CSTM_IND_RED : 59|1@1+ (1,0) [0|1] ""  ADAS
 SG_ MET68D_7_4_CSTM_IND_YELLOW : 60|1@1+ (1,0) [0|1] ""  ADAS
 SG_ MET68D_7_5_CSTM_IND_GREEN : 61|1@1+ (1,0) [0|1] ""  ADAS
 SG_ MET68D_7_6_REQ_CSTM_SRH : 62|1@1+ (1,0) [0|1] "" Vector__XXX
 SG_ MET68D_7_7_CSTM_SRH : 63|1@1+ (1,0) [0|1] "" Vector__XXX
 SG_ MET68D_6_5_REQ_CHG_CSTM_RAB : 53|1@1+ (1,0) [0|1] "" Vector__XXX
 SG_ MET68D_6_6_CSTM_RAB : 54|1@1+ (1,0) [0|1] "" Vector__XXX
 SG_ MET68D_6_7_CSTM_SONNER : 55|1@1+ (1,0) [0|1] "" Vector__XXX
 SG_ MET68D_5_0_TEMP_FOR_PPA : 40|13@1- (0.1,-400) [-400|419.1] "℃" Vector__XXX
 SG_ MET68D_2_0_ODO : 16|24@1+ (0.1,0) [0|999999.9] "km"  ADAS,VDC
 SG_ MET68D_1_0_MSG_COUNTER : 8|4@1+ (1,0) [0|15] ""  VDC
 SG_ MET68D_1_4_RESET_CSTM_TPMS_RAEB : 12|1@1+ (1,0) [0|1] "" Vector__XXX
 SG_ MET68D_1_5_REQ_CHG_CSTM_TPMS : 13|1@1+ (1,0) [0|1] "" Vector__XXX
 SG_ MET68D_1_6_CSTM_TIRE_UNIT : 14|2@1+ (1,0) [0|3] "" Vector__XXX
 SG_ MET68D_0_0_CHECK_SUM : 0|8@1+ (1,0) [0|255] ""  VDC

BO_ 915 MET393: 8 C_ECU_GW
 SG_ MET393_7_0_REQ_CHG_CSTM_EYE : 56|1@1+ (1,0) [0|1] "" Vector__XXX
 SG_ MET393_7_1_REQ_RESET_CSTM_EYE : 57|1@1+ (1,0) [0|1] "" Vector__XXX
 SG_ MET393_7_2_CSTM_ALK : 58|1@1+ (1,0) [0|1] "" Vector__XXX
 SG_ MET393_7_3_CSTM_HBA : 59|1@1+ (1,0) [0|1] "" Vector__XXX
 SG_ MET393_7_4_CSTM_MIS_AT_BACK : 60|2@1+ (1,0) [0|3] "" Vector__XXX
 SG_ MET393_7_6_CSTM_ACC_CONT : 62|2@1+ (1,0) [0|3] "" Vector__XXX
 SG_ MET393_6_0_R_DIFF_TEMP : 48|8@1+ (1,-50) [-50|200] "℃" Vector__XXX
 SG_ MET393_5_2_WARN_R_DIFF_TEMP : 42|2@1+ (1,0) [0|3] "" Vector__XXX
 SG_ MET393_5_4_ADAPTIVECC_NOALIVE : 44|1@1+ (1,0) [0|1] ""  ADAS
 SG_ MET393_5_5_DUAL_RANGE_LO : 45|1@1+ (1,0) [0|1] "" Vector__XXX
 SG_ MET393_5_6_CSTM_SPD_LIMITER : 46|1@1+ (1,0) [0|1] "" Vector__XXX
 SG_ MET393_5_7_CSTM_LANE_CONT : 47|1@1+ (1,0) [0|1] "" Vector__XXX
 SG_ MET393_4_0_FUEL_LEVEL_RESIST : 32|10@1+ (0.5,0) [0|480] "ohm" Vector__XXX
 SG_ MET393_3_5_SI_DRIVE_SW : 29|3@1+ (1,0) [0|7] "" Vector__XXX
 SG_ MET393_2_0_OUTTEMP_FOR_DIAG : 16|13@1+ (0.1,-400) [-400|419.1] "℃"  ADAS,VDC
 SG_ MET393_1_0_MSG_COUNTER : 8|4@1+ (1,0) [0|15] ""  ADAS,VDC
 SG_ MET393_1_4_CSTM_IND_BLUE : 12|1@1+ (1,0) [0|1] ""  ADAS
 SG_ MET393_1_5_CSTM_AES_CONT : 13|1@1+ (1,0) [0|1] "" Vector__XXX
 SG_ MET393_1_6_FLG_PEDESTRIAN_AIRBAG : 14|1@1+ (1,0) [0|1] "" Vector__XXX
 SG_ MET393_0_0_CHECK_SUM : 0|8@1+ (1,0) [0|255] ""  ADAS,VDC

BO_ 912 MET390: 8 C_ECU_GW
 SG_ MET390_7_0_VDC_ON_OFF : 56|2@1+ (1,0) [0|3] ""  ADAS_GW,VDC
 SG_ MET390_7_2_RR_DOOR_RECORD_L : 58|1@1+ (1,0) [0|1] ""  ADAS_GW
 SG_ MET390_7_3_RR_DOOR_RECORD_R : 59|1@1+ (1,0) [0|1] ""  ADAS_GW
 SG_ MET390_7_4_REQ_CHG_CSTM_PSM : 60|1@1+ (1,0) [0|1] ""  ADAS_GW
 SG_ MET390_7_5_REQ_RESET_CSTM_PSM : 61|1@1+ (1,0) [0|1] ""  ADAS_GW
 SG_ MET390_7_6_CSTM_MIR_AFOLD_CONT : 62|1@1+ (1,0) [0|1] ""  ADAS_GW
 SG_ MET390_7_7_CSTM_MIR_RTILT_CONT : 63|1@1+ (1,0) [0|1] ""  ADAS_GW
 SG_ MET390_6_0_SEATBELT_DRVR : 48|1@1+ (1,0) [0|1] ""  ADAS,ADAS_GW,ABG,VDC
 SG_ MET390_6_1_SEATBELT_PASS : 49|1@1+ (1,0) [0|1] ""  ADAS_GW,ABG
 SG_ MET390_6_2_TURN_SIG_LEFT : 50|1@1+ (1,0) [0|1] ""  ADAS,ADAS_GW,LCT,IPMS
 SG_ MET390_6_3_TURN_SIG_RIGHT : 51|1@1+ (1,0) [0|1] ""  ADAS,ADAS_GW,LCT,IPMS
 SG_ MET390_6_4_BRIGHT_SW : 52|1@1+ (1,0) [0|1] ""  ADAS_GW
 SG_ MET390_6_5_FAIL_UART_WA_BOX : 53|1@1+ (1,0) [0|1] ""  ADAS_GW,ABG
 SG_ MET390_6_6_ISS_OFF_SW : 54|1@1+ (1,0) [0|1] ""  ADAS_GW
 SG_ MET390_6_7_FLG_DMS : 55|1@1+ (1,0) [0|1] ""  ADAS,ADAS_GW
 SG_ MET390_5_0_ILL_BRIGHTNESS : 40|8@1+ (0.4,0) [0|100] "%"  ADAS_GW
 SG_ MET390_4_0_OUTTEMP_FOR_IND : 32|8@1+ (0.5,-40) [-40|80] "℃"  ADAS,ADAS_GW,ABG,VDC
 SG_ MET390_3_0_UNIT_SPEED_TRIP : 24|1@1+ (1,0) [0|1] ""  ADAS,ADAS_GW,VDC
 SG_ MET390_3_1_FLG_EYESIGHT : 25|1@1+ (1,0) [0|1] ""  ADAS,ADAS_GW,ABG,EPS,IPMS
 SG_ MET390_3_2_FLG_ISS : 26|1@1+ (1,0) [0|1] ""  ADAS,ADAS_GW
 SG_ MET390_3_3_FLG_HEV : 27|1@1+ (1,0) [0|1] ""  ADAS,ADAS_GW,EPS
 SG_ MET390_3_4_FLG_IMB : 28|1@1+ (1,0) [0|1] ""  ADAS_GW
 SG_ MET390_3_5_TIRE_SIZE : 29|1@1+ (1,0) [0|1] ""  ADAS,ADAS_GW
 SG_ MET390_3_6_FLG_XMODE : 30|2@1+ (1,0) [0|3] ""  ADAS_GW,VDC
 SG_ MET390_2_0_VEHICLE_SERIES : 16|3@1+ (1,0) [0|7] ""  ADAS,ADAS_GW,EPS
 SG_ MET390_2_3_DESTINATION : 19|4@1+ (1,0) [0|12] ""  ADAS,ADAS_GW,EPS
 SG_ MET390_2_7_PASS_DOOR_RECORD : 23|1@1+ (1,0) [0|1] ""  ADAS_GW
 SG_ MET390_1_0_MSG_COUNTER : 8|4@1+ (1,0) [0|15] ""  ADAS,ADAS_GW,LCT,ABG,EPS,IPMS,VDC
 SG_ MET390_1_4_WAKE_UP_FRAME : 12|1@1+ (1,0) [0|1] ""  ADAS_GW
 SG_ MET390_1_5_REQ_COMM_CONT : 13|1@1+ (1,0) [0|1] ""  ADAS_GW
 SG_ MET390_1_6_DMS_ID_SET : 14|1@1+ (1,0) [0|1] ""  ADAS_GW
 SG_ MET390_1_7_FAIL_EEPROM : 15|1@1+ (1,0) [0|1] ""  ADAS,ADAS_GW,EPS
 SG_ MET390_0_0_CHECK_SUM : 0|8@1+ (1,0) [0|255] ""  ADAS,ADAS_GW,LCT,ABG,EPS,IPMS,VDC

BO_ 1291 MET50B: 8 C_ECU_GW
 SG_ MET50B_1_4_ActiveWakeUpBit : 12|1@0+ (1,0) [0|1] ""  IPMS
 SG_ MET50B_0_0_SourceNodeID : 7|8@0+ (1,0) [0|255] ""  IPMS

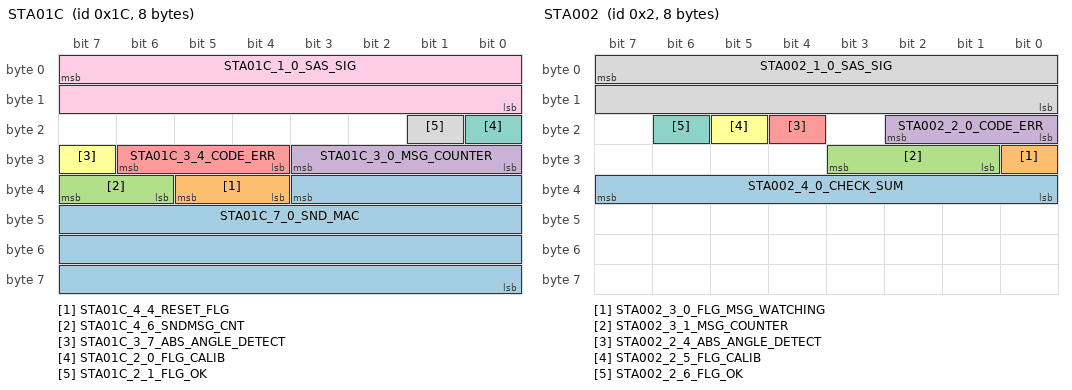
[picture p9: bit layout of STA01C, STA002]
BO_ 28 STA01C: 8 STA
 SG_ STA01C_7_0_SND_MAC : 35|28@0+ (1,0) [0|268435455] ""  VDC
 SG_ STA01C_4_4_RESET_FLG : 37|2@0+ (1,0) [0|3] ""  VDC
 SG_ STA01C_4_6_SNDMSG_CNT : 39|2@0+ (1,0) [0|3] ""  VDC
 SG_ STA01C_3_0_MSG_COUNTER : 27|4@0+ (1,0) [0|15] ""  VDC
 SG_ STA01C_3_4_CODE_ERR : 30|3@0+ (1,0) [0|7] ""  VDC
 SG_ STA01C_3_7_ABS_ANGLE_DETECT : 31|1@0+ (1,0) [0|1] ""  VDC
 SG_ STA01C_2_0_FLG_CALIB : 16|1@0+ (1,0) [0|1] ""  VDC
 SG_ STA01C_2_1_FLG_OK : 17|1@0+ (1,0) [0|1] ""  VDC
 SG_ STA01C_1_0_SAS_SIG : 7|16@0- (0.1,0) [-1039.9|1039.9] "°"  VDC

BO_ 2 STA002: 8 STA
 SG_ STA002_4_0_CHECK_SUM : 39|8@0+ (1,0) [0|255] ""  ADAS,BEV,EPS,VDC
 SG_ STA002_3_0_FLG_MSG_WATCHING : 24|1@0+ (1,0) [0|1] "" Vector__XXX
 SG_ STA002_3_1_MSG_COUNTER : 27|3@0+ (1,0) [0|7] ""  ADAS,BEV,VDC
 SG_ STA002_2_0_CODE_ERR : 18|3@0+ (1,0) [0|7] ""  ADAS,VDC
 SG_ STA002_2_4_ABS_ANGLE_DETECT : 20|1@0+ (1,0) [0|1] ""  VDC
 SG_ STA002_2_5_FLG_CALIB : 21|1@0+ (1,0) [0|1] ""  VDC
 SG_ STA002_2_6_FLG_OK : 22|1@0+ (1,0) [0|1] ""  VDC
 SG_ STA002_1_0_SAS_SIG : 7|16@0- (0.1,0) [-719.9|719.9] "deg"  ADAS,BEV,EPS,VDC,C_ECU

BO_ 1349 STA545: 8 STA
 SG_ STA545_7_0_NETWORK_STATUS : 7|64@0+ (1,0) [0|0] ""  C_ECU

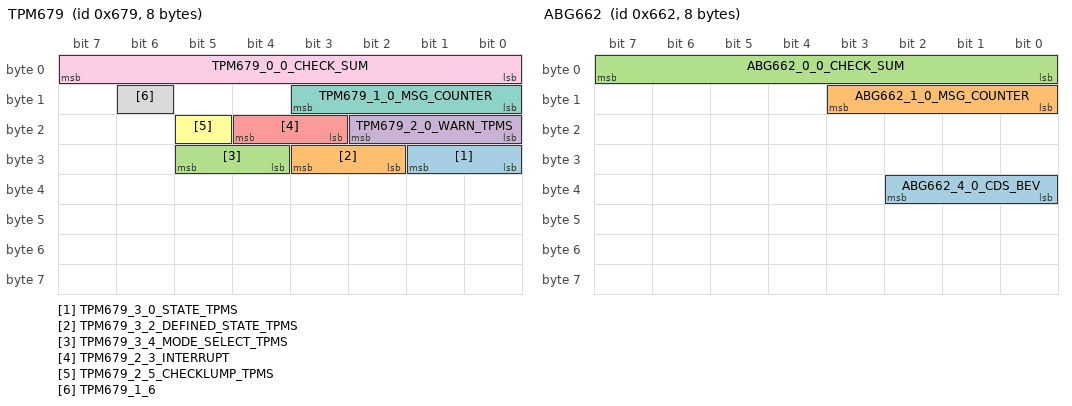
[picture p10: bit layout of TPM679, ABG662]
BO_ 1657 TPM679: 8 C_ECU_GW
 SG_ TPM679_3_0_STATE_TPMS : 24|2@1+ (1,0) [0|3] "" Vector__XXX
 SG_ TPM679_3_2_DEFINED_STATE_TPMS : 26|2@1+ (1,0) [0|3] "" Vector__XXX
 SG_ TPM679_3_4_MODE_SELECT_TPMS : 28|2@1+ (1,0) [0|3] "" Vector__XXX
 SG_ TPM679_2_0_WARN_TPMS : 16|3@1+ (1,0) [0|7] ""  ABG
 SG_ TPM679_2_3_INTERRUPT : 19|2@1+ (1,0) [0|2] "" Vector__XXX
 SG_ TPM679_2_5_CHECKLUMP_TPMS : 21|1@1+ (1,0) [0|1] "" Vector__XXX
 SG_ TPM679_1_0_MSG_COUNTER : 8|4@1+ (1,0) [0|15] ""  ABG
 SG_ TPM679_1_6 : 14|1@1+ (1,0) [0|1] "" Vector__XXX
 SG_ TPM679_0_0_CHECK_SUM : 0|8@1+ (1,0) [0|255] ""  ABG

BO_ 1634 ABG662: 8 ABG
 SG_ ABG662_4_0_CDS_BEV : 32|3@1+ (1,0) [0|7] ""  BEV
 SG_ ABG662_1_0_MSG_COUNTER : 8|4@1+ (1,0) [0|15] ""  BEV
 SG_ ABG662_0_0_CHECK_SUM : 0|8@1+ (1,0) [0|255] ""  BEV

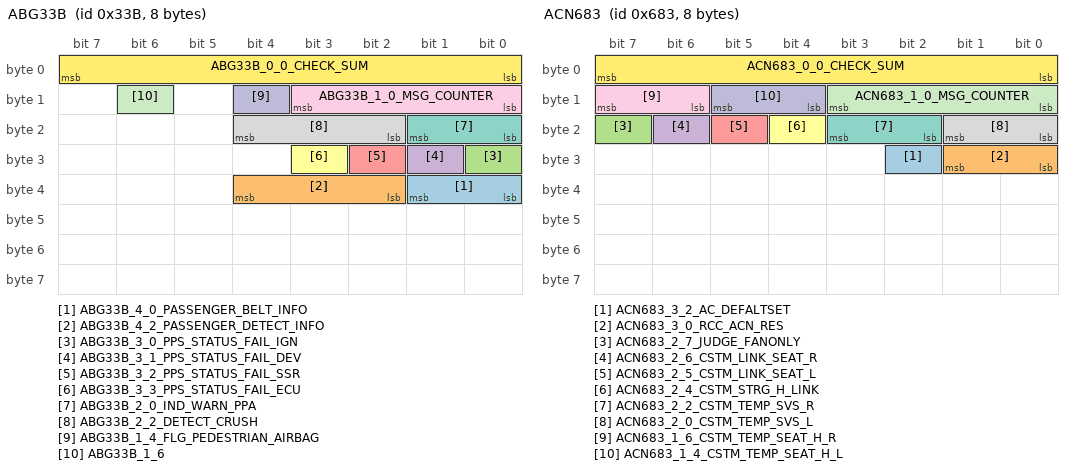
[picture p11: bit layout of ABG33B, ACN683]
BO_ 827 ABG33B: 8 ABG
 SG_ ABG33B_4_0_PASSENGER_BELT_INFO : 32|2@1+ (1,0) [0|3] ""  ADAS_GW,C_ECU_GW
 SG_ ABG33B_4_2_PASSENGER_DETECT_INFO : 34|3@1+ (1,0) [0|7] ""  ADAS_GW,C_ECU,C_ECU_GW
 SG_ ABG33B_3_0_PPS_STATUS_FAIL_IGN : 24|1@1+ (1,0) [0|1] ""  ADAS_GW,C_ECU_GW
 SG_ ABG33B_3_1_PPS_STATUS_FAIL_DEV : 25|1@1+ (1,0) [0|1] ""  ADAS_GW,C_ECU_GW
 SG_ ABG33B_3_2_PPS_STATUS_FAIL_SSR : 26|1@1+ (1,0) [0|1] ""  ADAS_GW,C_ECU_GW
 SG_ ABG33B_3_3_PPS_STATUS_FAIL_ECU : 27|1@1+ (1,0) [0|1] ""  ADAS_GW,C_ECU_GW
 SG_ ABG33B_2_0_IND_WARN_PPA : 16|2@1+ (1,0) [0|3] ""  ADAS_GW,VDC,C_ECU_GW
 SG_ ABG33B_2_2_DETECT_CRUSH : 18|3@1+ (1,0) [0|7] ""  ADAS,ADAS_GW,VDC,C_ECU_GW
 SG_ ABG33B_1_0_MSG_COUNTER : 8|4@1+ (1,0) [0|15] ""  ADAS,ADAS_GW,VDC,C_ECU,C_ECU_GW
 SG_ ABG33B_1_4_FLG_PEDESTRIAN_AIRBAG : 12|1@1+ (1,0) [0|1] ""  ADAS_GW,C_ECU_GW
 SG_ ABG33B_1_6 : 14|1@1+ (1,0) [0|1] ""  ADAS_GW,C_ECU_GW
 SG_ ABG33B_0_0_CHECK_SUM : 0|8@1+ (1,0) [0|255] ""  ADAS,ADAS_GW,VDC,C_ECU,C_ECU_GW

BO_ 826 ABG33A: 8 ABG
 SG_ ABG33A_7_0_VELOCITYCHANGE_VX_MAX : 56|8@1+ (1,0) [-101|101] "km/h"  ADAS_GW,C_ECU_GW
 SG_ ABG33A_6_0_VELOCITYCHANGE_VX_MAX : 48|8@1+ (1,0) [-101|101] "km/h"  ADAS_GW,C_ECU_GW
 SG_ ABG33A_5_0_P_SIDE_ABG_DEPLOY : 40|1@1+ (1,0) [0|1] ""  ADAS_GW,C_ECU_GW
 SG_ ABG33A_5_1_D_SIDE_ABG_DEPLOY : 41|1@1+ (1,0) [0|1] ""  ADAS_GW,C_ECU_GW
 SG_ ABG33A_5_2_FRONT_FAR_ABG_DEPLOY : 42|1@1+ (1,0) [0|1] ""  ADAS_GW,C_ECU_GW
 SG_ ABG33A_5_3_REAR_FAR_ABG_DEPLOY : 43|1@1+ (1,0) [0|1] ""  ADAS_GW,C_ECU_GW
 SG_ ABG33A_5_4_REAR_RH_ABG_DEPLOY : 44|1@1+ (1,0) [0|1] ""  ADAS_GW,C_ECU_GW
 SG_ ABG33A_5_5_REAR_LH_ABG_DEPLOY : 45|1@1+ (1,0) [0|1] ""  ADAS_GW,C_ECU_GW
 SG_ ABG33A_5_6_P_CURTAIN_ABG_DEPLOY : 46|1@1+ (1,0) [0|1] ""  ADAS_GW,C_ECU_GW
 SG_ ABG33A_5_7_D_CURTAIN_ABG_DEPLOY : 47|1@1+ (1,0) [0|1] ""  ADAS_GW,C_ECU_GW
 SG_ ABG33A_4_0_D_FRONT_ABG_DEPLOY : 32|1@1+ (1,0) [0|1] ""  ADAS_GW,C_ECU_GW
 SG_ ABG33A_4_1_P_FRONT_ABG_DEPLOY : 33|1@1+ (1,0) [0|1] ""  ADAS_GW,C_ECU_GW
 SG_ ABG33A_4_2_P_ABG_DEPLOY : 34|1@1+ (1,0) [0|1] ""  ADAS_GW,C_ECU_GW
 SG_ ABG33A_4_3_D_ABG_DEPLOY : 35|1@1+ (1,0) [0|1] ""  ADAS_GW,C_ECU_GW
 SG_ ABG33A_4_4_P_BELT_PRETENTION : 36|1@1+ (1,0) [0|1] ""  ADAS_GW,C_ECU_GW
 SG_ ABG33A_4_5_D_BELT_PRETENTION : 37|1@1+ (1,0) [0|1] ""  ADAS_GW,C_ECU_GW
 SG_ ABG33A_4_6_D_KNEE_ABG_DEPLOY : 38|1@1+ (1,0) [0|1] ""  ADAS_GW,C_ECU_GW
 SG_ ABG33A_4_7_P_KNEE_ABG_DEPLOY : 39|1@1+ (1,0) [0|1] ""  ADAS_GW,C_ECU_GW
 SG_ ABG33A_3_0_BELT_WRNING_PASS : 24|2@1+ (1,0) [0|3] ""  ADAS_GW,C_ECU_GW
 SG_ ABG33A_3_2_BUCKLESW_DRVR : 26|2@1+ (1,0) [0|3] ""  ADAS_GW,C_ECU_GW
 SG_ ABG33A_3_4_OCCUPATION_PASS : 28|2@1+ (1,0) [0|3] ""  ADAS_GW,C_ECU_GW
 SG_ ABG33A_3_6_IND_ACT_ABG_PASS : 30|2@1+ (1,0) [0|3] ""  ADAS_GW,C_ECU_GW
 SG_ ABG33A_2_0_IND_WARN_ABG : 16|2@1+ (1,0) [0|3] ""  ADAS_GW,VDC,C_ECU_GW
 SG_ ABG33A_2_2_DETECT_CRUSH : 18|3@1+ (1,0) [0|7] ""  ADAS,ADAS_GW,BEV,VDC,C_ECU,C_ECU_GW
 SG_ ABG33A_2_5_STATUS_CRUSH_ECALL : 21|3@1+ (1,0) [0|7] ""  ADAS_GW,VDC,C_ECU_GW
 SG_ ABG33A_1_0_MSG_COUNTER : 8|4@1+ (1,0) [0|15] ""  ADAS,ADAS_GW,BEV,VDC,C_ECU_GW
 SG_ ABG33A_1_4_FLG_ABGIND_CTRL : 12|1@1+ (1,0) [0|1] ""  ADAS_GW,C_ECU_GW
 SG_ ABG33A_1_5_REQ_COMM_CONT : 13|1@1+ (1,0) [0|1] ""  ADAS_GW,C_ECU_GW
 SG_ ABG33A_1_6_COLLISION_COUNTER : 14|2@1+ (1,0) [0|3] ""  ADAS_GW,C_ECU_GW
 SG_ ABG33A_0_0_CHECK_SUM : 0|8@1+ (1,0) [0|255] ""  ADAS,ADAS_GW,BEV,VDC,C_ECU_GW

BO_ 1351 ABG547: 8 ABG
 SG_ ABG547_7_0_NETWORK_STATUS : 7|64@0+ (1,0) [0|0] ""  C_ECU

BO_ 1315 ABG523: 8 ABG
 SG_ ABG523_1_4_ActiveWakeUpBit : 12|1@1+ (1,0) [0|1] ""  BST,VDC,C_ECU
 SG_ ABG523_0_0_SourceNodeID : 0|8@1+ (1,0) [0|255] ""  BST,VDC,C_ECU

BO_ 962 DMS3C2: 32 IPMS
 SG_ DMS3C2_27_2_EYE_CLOSE_TIME : 218|6@1+ (0.1,0) [0|6] "s" Vector__XXX
 SG_ DMS3C2_26_0_FACIAL_EXPRESSION : 208|2@1+ (1,0) [0|3] "" Vector__XXX
 SG_ DMS3C2_26_3_DIST_TIME : 211|7@1+ (0.1,0) [0|12] "s" Vector__XXX
 SG_ DMS3C2_24_4_GAZE_CONF_RIGHT : 196|7@1+ (1,0) [0|100] "" Vector__XXX
 SG_ DMS3C2_23_3_GAZE_PITCH_RIGHT : 187|9@1- (1,0) [-180|180] "deg" Vector__XXX
 SG_ DMS3C2_22_2_GAZE_YAW_RIGHT : 178|9@1- (1,0) [-180|180] "deg" Vector__XXX
 SG_ DMS3C2_21_3_GAZE_CONF_LEFT : 171|7@1+ (1,0) [0|100] "" Vector__XXX
 SG_ DMS3C2_20_2_GAZE_PITCH_LEFT : 162|9@1- (1,0) [-180|180] "deg" Vector__XXX
 SG_ DMS3C2_19_1_GAZE_YAW_LEFT : 153|9@1- (1,0) [-180|180] "deg" Vector__XXX
 SG_ DMS3C2_17_6_DRIVER_HEAD_POS_Z : 142|11@1- (1,0) [-1023|1022] "mm" Vector__XXX
 SG_ DMS3C2_16_3_DRIVER_HEAD_POS_Y : 131|11@1- (1,0) [-1023|1022] "mm" Vector__XXX
 SG_ DMS3C2_15_0_DRIVER_HEAD_POS_X : 120|11@1+ (1,0) [0|2046] "mm" Vector__XXX
 SG_ DMS3C2_13_4_VTX_RIGHT_BTM_Y : 108|12@1+ (1,0) [0|4094] "pix" Vector__XXX
 SG_ DMS3C2_12_0_VTX_RIGHT_BTM_X : 96|12@1+ (1,0) [0|4094] "pix" Vector__XXX
 SG_ DMS3C2_10_4_VTX_LEFT_UP_Y : 84|12@1+ (1,0) [0|4094] "pix" Vector__XXX
 SG_ DMS3C2_9_0_VTX_LEFT_UP_X : 72|12@1+ (1,0) [0|4094] "pix" Vector__XXX
 SG_ DMS3C2_8_3_FACE_CONF_FLAG : 67|1@1+ (1,0) [0|1] "" Vector__XXX
 SG_ DMS3C2_8_4_FRAME_NUM : 68|4@1+ (1,0) [0|15] "" Vector__XXX
 SG_ DMS3C2_7_3_EYE_CLS_CONF_FLAG : 59|1@1+ (1,0) [0|1] "" Vector__XXX
 SG_ DMS3C2_7_4_SLEEPNESS_LEVEL : 60|7@1+ (1,0) [0|100] "" Vector__XXX
 SG_ DMS3C2_6_3_FACE_AGL_CONF_FLAG : 51|1@1+ (1,0) [0|1] "" Vector__XXX
 SG_ DMS3C2_6_4_EYE_CLOSE_LEVEL : 52|7@1+ (1,0) [0|100] "%" Vector__XXX
 SG_ DMS3C2_5_2_FACE_ANGLE_ROLL : 42|9@1- (1,0) [-180|180] "deg" Vector__XXX
 SG_ DMS3C2_4_1_FACE_ANGLE_PITCH : 33|9@1- (1,0) [-180|180] "deg" Vector__XXX
 SG_ DMS3C2_3_0_FACE_ANGLE_YAW : 24|9@1- (1,0) [-180|180] "deg" Vector__XXX
 SG_ DMS3C2_2_0_E2E_COUNTER : 16|8@1+ (1,0) [0|255] "" Vector__XXX
 SG_ DMS3C2_0_0_E2E_CRC : 0|16@1+ (1,0) [0|65535] "" Vector__XXX

BO_ 961 DMS3C1: 8 IPMS
 SG_ DMS3C1_7_4_SHORT_DIST_DETECT : 60|1@1+ (1,0) [0|1] ""  ADAS,C_ECU_GW
 SG_ DMS3C1_7_5_PRESENCE_DETECT : 61|1@1+ (1,0) [0|1] ""  C_ECU_GW
 SG_ DMS3C1_7_6_RADER_EQUIP : 62|1@1+ (1,0) [0|1] ""  C_ECU_GW
 SG_ DMS3C1_7_7_LOSING_POSTURE_DETECT : 63|1@1+ (1,0) [0|1] ""  C_ECU_GW
 SG_ DMS3C1_6_0_ID_RECOG_CANCEL : 48|1@1+ (1,0) [0|1] ""  C_ECU_GW
 SG_ DMS3C1_6_1_ID_ENABLE_FLAG : 49|1@1+ (1,0) [0|1] ""  C_ECU_GW
 SG_ DMS3C1_6_2_PERMIT_AVN_FLAG : 50|1@1+ (1,0) [0|1] ""  C_ECU_GW
 SG_ DMS3C1_6_4_DISTRACTION_STATUS : 52|1@1+ (1,0) [0|1] ""  ADAS,C_ECU_GW
 SG_ DMS3C1_6_5_DROWSINESS_STATUS : 53|1@1+ (1,0) [0|1] ""  ADAS,C_ECU_GW
 SG_ DMS3C1_6_6_DROWSINESS_LV2_STATUS : 54|1@1+ (1,0) [0|1] ""  ADAS,C_ECU_GW
 SG_ DMS3C1_6_7_NOT_DETECTED_STATUS : 55|1@1+ (1,0) [0|1] ""  ADAS,C_ECU_GW
 SG_ DMS3C1_5_0_ID_LIST : 40|5@1+ (1,0) [0|31] ""  C_ECU_GW
 SG_ DMS3C1_5_5_ID_EDIT_FLAG : 45|3@1+ (1,0) [0|6] ""  C_ECU_GW
 SG_ DMS3C1_4_0_DMS_IND_REQ_FLAG : 32|3@1+ (1,0) [0|7] ""  ADAS,C_ECU_GW
 SG_ DMS3C1_4_3_DMS_RECOG_STATUS : 35|1@1+ (1,0) [0|1] ""  C_ECU_GW
 SG_ DMS3C1_4_4_DRIVER_STATUS : 36|4@1+ (1,0) [0|3] ""  C_ECU_GW
 SG_ DMS3C1_3_0_DRIVER_REGIST_ID : 24|4@1+ (1,0) [0|15] ""  C_ECU_GW
 SG_ DMS3C1_3_4_CUST_EDIT_FLAG : 28|2@1+ (1,0) [0|3] ""  C_ECU_GW
 SG_ DMS3C1_3_6_ID_RECOG_FLAG : 30|1@1+ (1,0) [0|1] ""  C_ECU_GW
 SG_ DMS3C1_2_0_LEVEL_DROWS : 16|3@1+ (1,0) [0|2] ""  ADAS,C_ECU_GW
 SG_ DMS3C1_2_3_DROWS_DETECT_FLAG : 19|1@1+ (1,0) [0|1] ""  ADAS,C_ECU_GW
 SG_ DMS3C1_2_7_DIST_DETECT_FLAG : 23|1@1+ (1,0) [0|1] ""  ADAS,C_ECU_GW
 SG_ DMS3C1_1_0_MSG_COUNTER : 8|4@1+ (1,0) [0|15] ""  ADAS,C_ECU_GW
 SG_ DMS3C1_1_4_WAKE_UP_FRAME : 12|1@1+ (1,0) [0|1] ""  C_ECU_GW
 SG_ DMS3C1_1_5_REQ_COMM_CONT : 13|1@1+ (1,0) [0|1] ""  C_ECU_GW
 SG_ DMS3C1_1_7_EYE_DIST_FLAG : 15|1@1+ (1,0) [0|1] ""  C_ECU_GW
 SG_ DMS3C1_0_0_CHKSUM : 0|8@1+ (1,0) [0|255] ""  ADAS,C_ECU_GW

BO_ 1290 DMS50A: 8 IPMS
 SG_ DMS50A_1_4_ActiveWakeUpBit : 12|1@1+ (1,0) [0|1] ""  IAVAS,BST,VDC,C_ECU,C_ECU_GW
 SG_ DMS50A_0_0_SourceNodeID : 0|8@1+ (1,0) [0|255] ""  IAVAS,BST,VDC,C_ECU,C_ECU_GW

BO_ 1651 ACN673: 8 C_ECU_GW
 SG_ ACN673_7_2_REQ_STRG_H : 58|2@1+ (1,0) [0|3] ""  ADAS
 SG_ ACN673_7_1_SEAT_H_L_AUTOIND : 57|1@1+ (1,0) [0|1] "" Vector__XXX
 SG_ ACN673_7_0_SEAT_H_R_AUTOIND : 56|1@1+ (1,0) [0|1] "" Vector__XXX
 SG_ ACN673_6_0_RR_FAN_SYMBOL : 48|1@1+ (1,0) [0|1] "" Vector__XXX
 SG_ ACN673_6_2_SEAT_H_R : 50|3@1+ (1,0) [0|7] ""  ENM
 SG_ ACN673_6_5_SEAT_H_L : 53|3@1+ (1,0) [0|7] ""  ENM
 SG_ ACN673_5_0_DR_ONLY : 40|2@1+ (1,0) [0|3] "" Vector__XXX
 SG_ ACN673_5_2_STRG_H : 42|2@1+ (1,0) [0|3] ""  ENM
 SG_ ACN673_5_4_AC_SI_DS_SET : 44|2@1+ (1,0) [0|3] "" Vector__XXX
 SG_ ACN673_5_6_STRG_H_AUTOIND : 46|1@1+ (1,0) [0|1] "" Vector__XXX
 SG_ ACN673_5_7_AC_SI_DS_FLG : 47|1@1+ (1,0) [0|1] "" Vector__XXX
 SG_ ACN673_4_0_SEAT_HEATER_DR : 32|2@1+ (1,0) [0|3] "" Vector__XXX
 SG_ ACN673_4_2_SEAT_HEATER_PA : 34|2@1+ (1,0) [0|3] "" Vector__XXX
 SG_ ACN673_4_4_SEAT_HEATER : 36|1@1+ (1,0) [0|1] "" Vector__XXX
 SG_ ACN673_4_5_TEMP_SET_TYPE : 37|2@1+ (1,0) [0|3] "" Vector__XXX
 SG_ ACN673_4_7_VENTI_SEAT_EX_HI : 39|1@1+ (1,0) [0|1] "" Vector__XXX
 SG_ ACN673_1_0_MSG_COUNTER : 8|4@1+ (1,0) [0|15] ""  ADAS,ENM
 SG_ ACN673_1_6_SYNC_RR : 14|1@1+ (1,0) [0|1] "" Vector__XXX
 SG_ ACN673_1_7_RR_LOCK : 15|1@1+ (1,0) [0|1] "" Vector__XXX
 SG_ ACN673_0_0_CHECK_SUM : 0|8@1+ (1,0) [0|255] ""  ADAS,ENM

BO_ 1650 ACN672: 8 C_ECU_GW
 SG_ ACN672_7_0_INFO_AUTO3MODE : 56|2@1+ (1,0) [0|3] ""  ENM
 SG_ ACN672_7_2_INFO_REAR_TEMP : 58|6@1+ (1,0) [0|44] "" Vector__XXX
 SG_ ACN672_6_0_DEF : 48|1@1+ (1,0) [0|1] "" Vector__XXX
 SG_ ACN672_6_1_FAN_SYMBOL : 49|1@1+ (1,0) [0|1] "" Vector__XXX
 SG_ ACN672_6_2_REAR_MODE : 50|2@1+ (1,0) [0|3] "" Vector__XXX
 SG_ ACN672_6_4_UNIT_TEMP : 52|1@1+ (1,0) [0|1] ""  ENM
 SG_ ACN672_6_5_SPEC_AC_UNIT : 53|2@1+ (1,0) [0|3] "" Vector__XXX
 SG_ ACN672_6_7_REAR_AC : 55|1@1+ (1,0) [0|1] "" Vector__XXX
 SG_ ACN672_5_0_AC_VR_MODE : 40|2@1+ (1,0) [0|3] "" Vector__XXX
 SG_ ACN672_5_2_INFO_TEMP_PASS : 42|6@1+ (1,0) [0|63] "" Vector__XXX
 SG_ ACN672_4_0_AC_INTERRUPT_DISPLAY : 32|1@1+ (1,0) [0|1] "" Vector__XXX
 SG_ ACN672_4_1_AC_VR_ACTION : 33|1@1+ (1,0) [0|1] "" Vector__XXX
 SG_ ACN672_4_2_INFO_TEMP_DRVR : 34|6@1+ (1,0) [0|63] ""  ENM
 SG_ ACN672_3_0_MAX_AC : 24|1@1+ (1,0) [0|1] "" Vector__XXX
 SG_ ACN672_3_1_INFO_SYNC_OR_SING : 25|1@1+ (1,0) [0|1] "" Vector__XXX
 SG_ ACN672_3_2_INFO_FULL_OR_AUTO : 26|2@1+ (1,0) [0|3] "" Vector__XXX
 SG_ ACN672_3_4_INFO_AC_ON : 28|1@1+ (1,0) [0|1] "" Vector__XXX
 SG_ ACN672_3_5_INFO_RDEF : 29|1@1+ (1,0) [0|1] "" Vector__XXX
 SG_ ACN672_3_6_INFO_CIRCULATION : 30|2@1+ (1,0) [0|3] ""  ADAS
 SG_ ACN672_2_0_INFO_MODE_VENT : 16|4@1+ (1,0) [0|15] "" Vector__XXX
 SG_ ACN672_2_4_INFO_FANONLY : 20|1@1+ (1,0) [0|1] ""  ENM
 SG_ ACN672_2_5_INFO_LEV_BLOWERFAN : 21|3@1+ (1,0) [0|7] ""  ENM,THM
 SG_ ACN672_1_0_MSG_COUNTER : 8|4@1+ (1,0) [0|15] ""  ADAS,ENM,THM
 SG_ ACN672_1_4_LVL_BLOWERFAN_RR : 12|3@1+ (1,0) [0|7] "" Vector__XXX
 SG_ ACN672_1_7_REAR_AUTO : 15|1@1+ (1,0) [0|1] "" Vector__XXX
 SG_ ACN672_0_0_CHECK_SUM : 0|8@1+ (1,0) [0|255] ""  ADAS,ENM,THM

BO_ 722 ACN2D2: 8 C_ECU_GW
 SG_ ACN2D2_7_0_PD_PRESSURE : 56|8@1+ (0.0146866,0) [0|3.74509] "Mpa"  THM
 SG_ ACN2D2_6_0_TRQ_COMP_ESTM : 48|8@1+ (0.3921568627451,0) [0|100] "Nm" Vector__XXX
 SG_ ACN2D2_5_0_REQ_ENG_RPM : 40|3@1+ (1,0) [0|6] "" Vector__XXX
 SG_ ACN2D2_5_3_REQ_IDLE_COMP_RPM : 43|5@1+ (25,650) [650|1425] "rpm" Vector__XXX
 SG_ ACN2D2_4_0_LVL_PTC : 32|2@1+ (1,0) [0|3] "" Vector__XXX
 SG_ ACN2D2_4_2_MARGIN_OF_AC : 34|3@1+ (1,0) [0|7] "" Vector__XXX
 SG_ ACN2D2_4_5_LVL_BLOWER_FAN : 37|3@1+ (1,0) [0|7] "" Vector__XXX
 SG_ ACN2D2_3_0_PERMIT_ISS : 24|2@1+ (1,0) [0|3] "" Vector__XXX
 SG_ ACN2D2_3_2_TRQ_PAT_COMP_ESTM : 26|3@1+ (1,0) [0|6] "" Vector__XXX
 SG_ ACN2D2_3_5_IND_ROOM_TEMP : 29|3@1+ (1,0) [0|4] ""  ENM
 SG_ ACN2D2_2_0_FAIL_TRQ_COMP_ESTM : 16|1@1+ (1,0) [0|1] "" Vector__XXX
 SG_ ACN2D2_2_1_FAIL_AC : 17|1@1+ (1,0) [0|1] "" Vector__XXX
 SG_ ACN2D2_2_2_REQ_INHIBIT_LOCKUP : 18|1@1+ (1,0) [0|1] "" Vector__XXX
 SG_ ACN2D2_2_3_AC_ON : 19|1@1+ (1,0) [0|1] "" Vector__XXX
 SG_ ACN2D2_2_4_RDEFOGSW : 20|1@1+ (1,0) [0|1] "" Vector__XXX
 SG_ ACN2D2_2_5_WARM_UP : 21|1@1+ (1,0) [0|1] "" Vector__XXX
 SG_ ACN2D2_2_6_AC_AUTO_MANUAL : 22|1@1+ (1,0) [0|1] "" Vector__XXX
 SG_ ACN2D2_2_7_COMP_TYPE : 23|1@1+ (1,0) [0|1] "" Vector__XXX
 SG_ ACN2D2_1_0_MSG_COUNTER : 8|4@1+ (1,0) [0|15] ""  ENM,THM
 SG_ ACN2D2_1_4 : 12|1@1+ (1,0) [0|1] "" Vector__XXX
 SG_ ACN2D2_1_5 : 13|1@1+ (1,0) [0|1] "" Vector__XXX
 SG_ ACN2D2_1_6 : 14|1@1+ (1,0) [0|1] "" Vector__XXX
 SG_ ACN2D2_1_7_WARM_POWER_CONT : 15|1@1+ (1,0) [0|1] "" Vector__XXX
 SG_ ACN2D2_0_0_CHECK_SUM : 0|8@1+ (1,0) [0|255] ""  ENM,THM

BO_ 1667 ACN683: 8 C_ECU_GW
 SG_ ACN683_3_2_AC_DEFALTSET : 26|1@1+ (1,0) [0|1] ""  ENM
 SG_ ACN683_3_0_RCC_ACN_RES : 24|2@1+ (1,0) [0|3] "" Vector__XXX
 SG_ ACN683_2_7_JUDGE_FANONLY : 23|1@1+ (1,0) [0|1] "" Vector__XXX
 SG_ ACN683_2_6_CSTM_LINK_SEAT_R : 22|1@1+ (1,0) [0|1] "" Vector__XXX
 SG_ ACN683_2_5_CSTM_LINK_SEAT_L : 21|1@1+ (1,0) [0|1] "" Vector__XXX
 SG_ ACN683_2_4_CSTM_STRG_H_LINK : 20|1@1+ (1,0) [0|1] "" Vector__XXX
 SG_ ACN683_2_2_CSTM_TEMP_SVS_R : 18|2@1+ (1,0) [0|3] "" Vector__XXX
 SG_ ACN683_2_0_CSTM_TEMP_SVS_L : 16|2@1+ (1,0) [0|3] "" Vector__XXX
 SG_ ACN683_1_6_CSTM_TEMP_SEAT_H_R : 14|2@1+ (1,0) [0|3] "" Vector__XXX
 SG_ ACN683_1_4_CSTM_TEMP_SEAT_H_L : 12|2@1+ (1,0) [0|3] "" Vector__XXX
 SG_ ACN683_1_0_MSG_COUNTER : 8|4@1+ (1,0) [0|15] ""  ENM
 SG_ ACN683_0_0_CHECK_SUM : 0|8@1+ (1,0) [0|255] ""  ENM

BO_ 957 ACN3BD: 8 C_ECU_GW
 SG_ ACN3BD_4_0_STATE_HT_ACT : 32|2@1+ (1,0) [0|3] ""  THM
 SG_ ACN3BD_3_3_STATE_HT_CIR : 27|4@1+ (1,0) [0|4] ""  THM
 SG_ ACN3BD_3_0_STATE_HT_CIR_SW : 24|3@1+ (1,0) [0|4] ""  THM
 SG_ ACN3BD_2_0_POS_4WV : 16|9@1+ (1,0) [0|360] "deg"  ENM,THM
 SG_ ACN3BD_1_4_ERR_HTDEV : 12|3@1+ (1,0) [0|7] ""  THM
 SG_ ACN3BD_1_0_MSG_COUNTER : 8|4@1+ (1,0) [0|15] ""  THM
 SG_ ACN3BD_0_0_CHECK_SUM : 0|8@1+ (1,0) [0|255] ""  THM

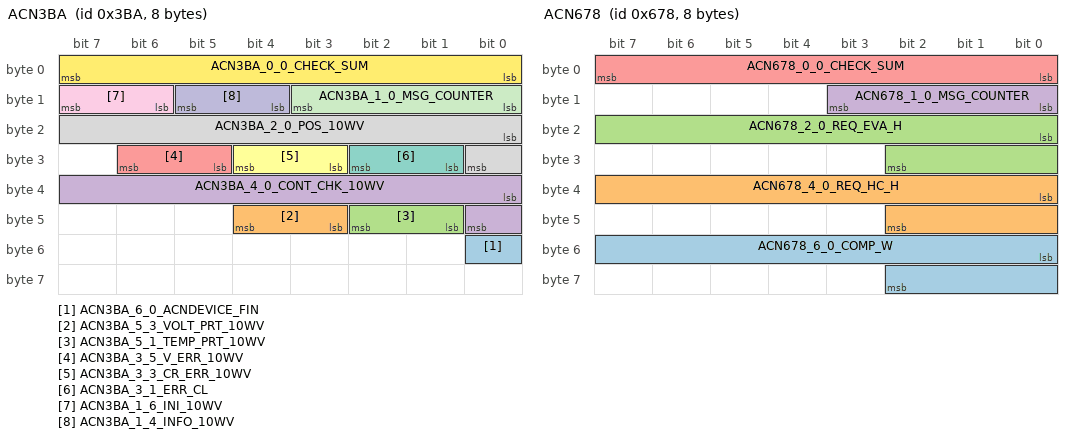
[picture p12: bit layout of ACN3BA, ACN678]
BO_ 954 ACN3BA: 8 C_ECU_GW
 SG_ ACN3BA_6_0_ACNDEVICE_FIN : 48|1@1+ (1,0) [0|1] ""  THM
 SG_ ACN3BA_5_3_VOLT_PRT_10WV : 43|2@1+ (1,0) [0|3] ""  THM
 SG_ ACN3BA_5_1_TEMP_PRT_10WV : 41|2@1+ (1,0) [0|3] ""  THM
 SG_ ACN3BA_4_0_CONT_CHK_10WV : 32|9@1+ (1,0) [0|360] "deg"  THM
 SG_ ACN3BA_3_5_V_ERR_10WV : 29|2@1+ (1,0) [0|3] ""  THM
 SG_ ACN3BA_3_3_CR_ERR_10WV : 27|2@1+ (1,0) [0|3] ""  THM
 SG_ ACN3BA_3_1_ERR_CL : 25|2@1+ (1,0) [0|3] ""  THM
 SG_ ACN3BA_2_0_POS_10WV : 16|9@1+ (1,0) [0|360] "deg"  THM
 SG_ ACN3BA_1_6_INI_10WV : 14|2@1+ (1,0) [0|3] ""  THM
 SG_ ACN3BA_1_4_INFO_10WV : 12|2@1+ (1,0) [0|3] ""  THM
 SG_ ACN3BA_1_0_MSG_COUNTER : 8|4@1+ (1,0) [0|15] ""  THM
 SG_ ACN3BA_0_0_CHECK_SUM : 0|8@1+ (1,0) [0|255] ""  THM

BO_ 1659 ACN67B: 8 C_ECU_GW
 SG_ ACN67B_6_0_STATE_INW : 48|1@1+ (1,0) [0|1] ""  THM
 SG_ ACN67B_5_2_JUDGE_OIL_SALVAGE : 42|2@1+ (1,0) [0|3] ""  THM
 SG_ ACN67B_5_0_OIL_SALVAGE_READY : 40|1@1+ (1,0) [0|1] ""  THM
 SG_ ACN67B_4_3_STATE_ACLOAD : 35|3@1+ (1,0) [0|7] ""  THM
 SG_ ACN67B_4_2_REQ_LT_DEF : 34|1@1+ (1,0) [0|1] ""  THM
 SG_ ACN67B_4_1_REQ_HT_RAD : 33|1@1+ (1,0) [0|1] ""  THM
 SG_ ACN67B_4_0_STATE_BATHP : 32|1@1+ (1,0) [0|1] ""  THM
 SG_ ACN67B_3_4_REQ_ACCYC : 28|3@1+ (1,0) [0|4] ""  THM
 SG_ ACN67B_3_3_JUDGE_AMBHP : 27|1@1+ (1,0) [0|1] ""  THM
 SG_ ACN67B_3_1_RL_LTO : 25|2@1+ (1,0) [0|3] ""  THM
 SG_ ACN67B_2_0_TW_LTO : 16|9@1+ (0.5,-40) [-40|215.5] "℃"  THM
 SG_ ACN67B_1_7_JUDGE_LTHP : 15|1@1+ (1,0) [0|1] ""  THM
 SG_ ACN67B_1_6_HTS_BAT_COMB : 14|1@1+ (1,0) [0|1] ""  THM
 SG_ ACN67B_1_5_HTS_AC_ALONE : 13|1@1+ (1,0) [0|1] ""  THM
 SG_ ACN67B_1_4_PERMIT_TL : 12|1@1+ (1,0) [0|1] ""  THM
 SG_ ACN67B_1_0_MSG_COUNTER : 8|4@1+ (1,0) [0|15] ""  THM
 SG_ ACN67B_0_0_CHECK_SUM : 0|8@1+ (1,0) [0|255] ""  THM

BO_ 1656 ACN678: 8 C_ECU_GW
 SG_ ACN678_6_0_COMP_W : 48|11@1+ (10,0) [0|20470] "W"  THM
 SG_ ACN678_4_0_REQ_HC_H : 32|11@1+ (10,0) [0|20470] "W"  THM
 SG_ ACN678_2_0_REQ_EVA_H : 16|11@1+ (10,0) [0|20470] "W"  THM
 SG_ ACN678_1_0_MSG_COUNTER : 8|4@1+ (1,0) [0|15] ""  THM
 SG_ ACN678_0_0_CHECK_SUM : 0|8@1+ (1,0) [0|255] ""  THM

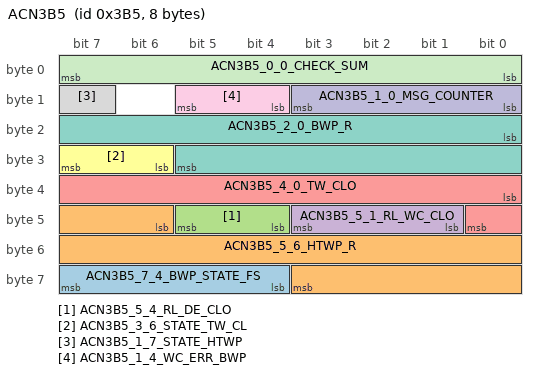
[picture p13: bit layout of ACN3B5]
BO_ 949 ACN3B5: 8 C_ECU_GW
 SG_ ACN3B5_7_4_BWP_STATE_FS : 60|4@1+ (1,0) [0|12] ""  THM
 SG_ ACN3B5_5_6_HTWP_R : 46|14@1+ (1,0) [0|16383] "RPM"  THM
 SG_ ACN3B5_5_4_RL_DE_CLO : 44|2@1+ (1,0) [0|3] ""  THM
 SG_ ACN3B5_5_1_RL_WC_CLO : 41|3@1+ (1,0) [0|7] ""  THM
 SG_ ACN3B5_4_0_TW_CLO : 32|9@1+ (0.5,-40) [-40|215.5] "℃"  THM
 SG_ ACN3B5_3_6_STATE_TW_CL : 30|2@1+ (1,0) [0|3] ""  THM
 SG_ ACN3B5_2_0_BWP_R : 16|14@1+ (1,0) [0|65535] "rpm"  THM
 SG_ ACN3B5_1_7_STATE_HTWP : 15|1@1+ (1,0) [0|1] ""  THM
 SG_ ACN3B5_1_4_WC_ERR_BWP : 12|2@1+ (1,0) [0|3] ""  THM
 SG_ ACN3B5_1_0_MSG_COUNTER : 8|4@1+ (1,0) [0|15] ""  THM
 SG_ ACN3B5_0_0_CHECK_SUM : 0|8@1+ (1,0) [0|255] ""  THM

CM_ SG_ 2564481198 DMS18DAE0AE_DIAG_DATA_EXT7 "ﾃﾞｰﾀ
";
CM_ SG_ 2564481198 DMS18DAE0AE_DIAG_DATA_EXT6 "ﾃﾞｰﾀ
";
CM_ SG_ 2564481198 DMS18DAE0AE_DIAG_DATA_EXT5 "ﾃﾞｰﾀ
";
CM_ SG_ 2564481198 DMS18DAE0AE_DIAG_DATA_EXT4 "ﾃﾞｰﾀ
";
CM_ SG_ 2564481198 DMS18DAE0AE_DIAG_DATA_EXT3 "ﾃﾞｰﾀ
";
CM_ SG_ 2564481198 DMS18DAE0AE_DIAG_DATA_EXT2 "ﾃﾞｰﾀ
";
CM_ SG_ 2564481198 DMS18DAE0AE_DIAG_DATA_EXT1 "ﾃﾞｰﾀ
";
CM_ SG_ 2564481198 DMS18DAE0AE_DIAG_DATA "ﾃﾞｰﾀ
";
CM_ SG_ 2564468448 DNT18DAAEE0_DIAG_DATA_EXT7 "ﾃﾞｰﾀ
";
CM_ SG_ 2564468448 DNT18DAAEE0_DIAG_DATA_EXT6 "ﾃﾞｰﾀ
";
CM_ SG_ 2564468448 DNT18DAAEE0_DIAG_DATA_EXT5 "ﾃﾞｰﾀ
";
CM_ SG_ 2564468448 DNT18DAAEE0_DIAG_DATA_EXT4 "ﾃﾞｰﾀ
";
CM_ SG_ 2564468448 DNT18DAAEE0_DIAG_DATA_EXT3 "ﾃﾞｰﾀ
";
CM_ SG_ 2564468448 DNT18DAAEE0_DIAG_DATA_EXT2 "ﾃﾞｰﾀ
";
CM_ SG_ 2564468448 DNT18DAAEE0_DIAG_DATA_EXT1 "ﾃﾞｰﾀ
";
CM_ SG_ 2564468448 DNT18DAAEE0_DIAG_DATA "ﾃﾞｰﾀ
";
CM_ SG_ 2564481036 BST18DAE00C_DIAG_DATA_EXT7 "ﾃﾞｰﾀ
";
CM_ SG_ 2564481036 BST18DAE00C_DIAG_DATA_EXT6 "ﾃﾞｰﾀ
";
CM_ SG_ 2564481036 BST18DAE00C_DIAG_DATA_EXT5 "ﾃﾞｰﾀ
";
CM_ SG_ 2564481036 BST18DAE00C_DIAG_DATA_EXT4 "ﾃﾞｰﾀ
";
CM_ SG_ 2564481036 BST18DAE00C_DIAG_DATA_EXT3 "ﾃﾞｰﾀ
";
CM_ SG_ 2564481036 BST18DAE00C_DIAG_DATA_EXT2 "ﾃﾞｰﾀ
";
CM_ SG_ 2564481036 BST18DAE00C_DIAG_DATA_EXT1 "ﾃﾞｰﾀ
";
CM_ SG_ 2564481036 BST18DAE00C_DIAG_DATA "ﾃﾞｰﾀ
";
CM_ SG_ 2564426976 DNT18DA0CE0_DIAG_DATA_EXT7 "ﾃﾞｰﾀ
";
CM_ SG_ 2564426976 DNT18DA0CE0_DIAG_DATA_EXT6 "ﾃﾞｰﾀ
";
CM_ SG_ 2564426976 DNT18DA0CE0_DIAG_DATA_EXT5 "ﾃﾞｰﾀ
";
CM_ SG_ 2564426976 DNT18DA0CE0_DIAG_DATA_EXT4 "ﾃﾞｰﾀ
";
CM_ SG_ 2564426976 DNT18DA0CE0_DIAG_DATA_EXT3 "ﾃﾞｰﾀ
";
CM_ SG_ 2564426976 DNT18DA0CE0_DIAG_DATA_EXT2 "ﾃﾞｰﾀ
";
CM_ SG_ 2564426976 DNT18DA0CE0_DIAG_DATA_EXT1 "ﾃﾞｰﾀ
";
CM_ SG_ 2564426976 DNT18DA0CE0_DIAG_DATA "ﾃﾞｰﾀ
";
CM_ SG_ 2564481153 MCA18DAE081_DIAG_DATA_EXT7 "ﾃﾞｰﾀ
";
CM_ SG_ 2564481153 MCA18DAE081_DIAG_DATA_EXT6 "ﾃﾞｰﾀ
";
CM_ SG_ 2564481153 MCA18DAE081_DIAG_DATA_EXT5 "ﾃﾞｰﾀ
";
CM_ SG_ 2564481153 MCA18DAE081_DIAG_DATA_EXT4 "ﾃﾞｰﾀ
";
CM_ SG_ 2564481153 MCA18DAE081_DIAG_DATA_EXT3 "ﾃﾞｰﾀ
";
CM_ SG_ 2564481153 MCA18DAE081_DIAG_DATA_EXT2 "ﾃﾞｰﾀ
";
CM_ SG_ 2564481153 MCA18DAE081_DIAG_DATA_EXT1 "ﾃﾞｰﾀ
";
CM_ SG_ 2564481153 MCA18DAE081_DIAG_DATA "ﾃﾞｰﾀ
";
CM_ SG_ 2564456928 DNT18DA81E0_DIAG_DATA_EXT7 "ﾃﾞｰﾀ
";
CM_ SG_ 2564456928 DNT18DA81E0_DIAG_DATA_EXT6 "ﾃﾞｰﾀ
";
CM_ SG_ 2564456928 DNT18DA81E0_DIAG_DATA_EXT5 "ﾃﾞｰﾀ
";
CM_ SG_ 2564456928 DNT18DA81E0_DIAG_DATA_EXT4 "ﾃﾞｰﾀ
";
CM_ SG_ 2564456928 DNT18DA81E0_DIAG_DATA_EXT3 "ﾃﾞｰﾀ
";
CM_ SG_ 2564456928 DNT18DA81E0_DIAG_DATA_EXT2 "ﾃﾞｰﾀ
";
CM_ SG_ 2564456928 DNT18DA81E0_DIAG_DATA_EXT1 "ﾃﾞｰﾀ
";
CM_ SG_ 2564456928 DNT18DA81E0_DIAG_DATA "ﾃﾞｰﾀ
";
CM_ SG_ 2564481154 FCRL18DAE082_DIAG_DATA_EXT7 "ﾃﾞｰﾀ
";
CM_ SG_ 2564481154 FCRL18DAE082_DIAG_DATA_EXT6 "ﾃﾞｰﾀ
";
CM_ SG_ 2564481154 FCRL18DAE082_DIAG_DATA_EXT5 "ﾃﾞｰﾀ
";
CM_ SG_ 2564481154 FCRL18DAE082_DIAG_DATA_EXT4 "ﾃﾞｰﾀ
";
CM_ SG_ 2564481154 FCRL18DAE082_DIAG_DATA_EXT3 "ﾃﾞｰﾀ
";
CM_ SG_ 2564481154 FCRL18DAE082_DIAG_DATA_EXT2 "ﾃﾞｰﾀ
";
CM_ SG_ 2564481154 FCRL18DAE082_DIAG_DATA_EXT1 "ﾃﾞｰﾀ
";
CM_ SG_ 2564481154 FCRL18DAE082_DIAG_DATA "ﾃﾞｰﾀ
";
CM_ SG_ 2564457184 DNT18DA82E0_DIAG_DATA_EXT7 "ﾃﾞｰﾀ
";
CM_ SG_ 2564457184 DNT18DA82E0_DIAG_DATA_EXT6 "ﾃﾞｰﾀ
";
CM_ SG_ 2564457184 DNT18DA82E0_DIAG_DATA_EXT5 "ﾃﾞｰﾀ
";
CM_ SG_ 2564457184 DNT18DA82E0_DIAG_DATA_EXT4 "ﾃﾞｰﾀ
";
CM_ SG_ 2564457184 DNT18DA82E0_DIAG_DATA_EXT3 "ﾃﾞｰﾀ
";
CM_ SG_ 2564457184 DNT18DA82E0_DIAG_DATA_EXT2 "ﾃﾞｰﾀ
";
CM_ SG_ 2564457184 DNT18DA82E0_DIAG_DATA_EXT1 "ﾃﾞｰﾀ
";
CM_ SG_ 2564457184 DNT18DA82E0_DIAG_DATA "ﾃﾞｰﾀ
";
CM_ SG_ 2564481155 FCRR18DAE083_DIAG_DATA_EXT7 "ﾃﾞｰﾀ
";
CM_ SG_ 2564481155 FCRR18DAE083_DIAG_DATA_EXT6 "ﾃﾞｰﾀ
";
CM_ SG_ 2564481155 FCRR18DAE083_DIAG_DATA_EXT5 "ﾃﾞｰﾀ
";
CM_ SG_ 2564481155 FCRR18DAE083_DIAG_DATA_EXT4 "ﾃﾞｰﾀ
";
CM_ SG_ 2564481155 FCRR18DAE083_DIAG_DATA_EXT3 "ﾃﾞｰﾀ
";
CM_ SG_ 2564481155 FCRR18DAE083_DIAG_DATA_EXT2 "ﾃﾞｰﾀ
";
CM_ SG_ 2564481155 FCRR18DAE083_DIAG_DATA_EXT1 "ﾃﾞｰﾀ
";
CM_ SG_ 2564481155 FCRR18DAE083_DIAG_DATA "ﾃﾞｰﾀ
";
CM_ SG_ 2564457440 DNT18DA83E0_DIAG_DATA_EXT7 "ﾃﾞｰﾀ
";
CM_ SG_ 2564457440 DNT18DA83E0_DIAG_DATA_EXT6 "ﾃﾞｰﾀ
";
CM_ SG_ 2564457440 DNT18DA83E0_DIAG_DATA_EXT5 "ﾃﾞｰﾀ
";
CM_ SG_ 2564457440 DNT18DA83E0_DIAG_DATA_EXT4 "ﾃﾞｰﾀ
";
CM_ SG_ 2564457440 DNT18DA83E0_DIAG_DATA_EXT3 "ﾃﾞｰﾀ
";
CM_ SG_ 2564457440 DNT18DA83E0_DIAG_DATA_EXT2 "ﾃﾞｰﾀ
";
CM_ SG_ 2564457440 DNT18DA83E0_DIAG_DATA_EXT1 "ﾃﾞｰﾀ
";
CM_ SG_ 2564457440 DNT18DA83E0_DIAG_DATA "ﾃﾞｰﾀ
";
CM_ SG_ 2564481107 ABG18DAE053_DIAG_DATA "ﾃﾞｰﾀ
";
CM_ SG_ 2564445152 DNT18DA53E0_DIAG_DATA "ﾃﾞｰﾀ
";
CM_ SG_ 2564481101 STA18DAE04D_DIAG_DATA_EXT7 "ﾃﾞｰﾀ
";
CM_ SG_ 2564481101 STA18DAE04D_DIAG_DATA_EXT6 "ﾃﾞｰﾀ
";
CM_ SG_ 2564481101 STA18DAE04D_DIAG_DATA_EXT5 "ﾃﾞｰﾀ
";
CM_ SG_ 2564481101 STA18DAE04D_DIAG_DATA_EXT4 "ﾃﾞｰﾀ
";
CM_ SG_ 2564481101 STA18DAE04D_DIAG_DATA_EXT3 "ﾃﾞｰﾀ
";
CM_ SG_ 2564481101 STA18DAE04D_DIAG_DATA_EXT2 "ﾃﾞｰﾀ
";
CM_ SG_ 2564481101 STA18DAE04D_DIAG_DATA_EXT1 "ﾃﾞｰﾀ
";
CM_ SG_ 2564481101 STA18DAE04D_DIAG_DATA "ﾃﾞｰﾀ
";
CM_ SG_ 2564443616 DNT18DA4DE0_DIAG_DATA_EXT7 "ﾃﾞｰﾀ
";
CM_ SG_ 2564443616 DNT18DA4DE0_DIAG_DATA_EXT6 "ﾃﾞｰﾀ
";
CM_ SG_ 2564443616 DNT18DA4DE0_DIAG_DATA_EXT5 "ﾃﾞｰﾀ
";
CM_ SG_ 2564443616 DNT18DA4DE0_DIAG_DATA_EXT4 "ﾃﾞｰﾀ
";
CM_ SG_ 2564443616 DNT18DA4DE0_DIAG_DATA_EXT3 "ﾃﾞｰﾀ
";
CM_ SG_ 2564443616 DNT18DA4DE0_DIAG_DATA_EXT2 "ﾃﾞｰﾀ
";
CM_ SG_ 2564443616 DNT18DA4DE0_DIAG_DATA_EXT1 "ﾃﾞｰﾀ
";
CM_ SG_ 2564443616 DNT18DA4DE0_DIAG_DATA "ﾃﾞｰﾀ
";
CM_ SG_ 2564481043 EPS18DAE013_DIAG_DATA_EXT7 "ﾃﾞｰﾀ
";
CM_ SG_ 2564481043 EPS18DAE013_DIAG_DATA_EXT6 "ﾃﾞｰﾀ
";
CM_ SG_ 2564481043 EPS18DAE013_DIAG_DATA_EXT5 "ﾃﾞｰﾀ
";
CM_ SG_ 2564481043 EPS18DAE013_DIAG_DATA_EXT4 "ﾃﾞｰﾀ
";
CM_ SG_ 2564481043 EPS18DAE013_DIAG_DATA_EXT3 "ﾃﾞｰﾀ
";
CM_ SG_ 2564481043 EPS18DAE013_DIAG_DATA_EXT2 "ﾃﾞｰﾀ
";
CM_ SG_ 2564481043 EPS18DAE013_DIAG_DATA_EXT1 "ﾃﾞｰﾀ
";
CM_ SG_ 2564481043 EPS18DAE013_DIAG_DATA "ﾃﾞｰﾀ
";
CM_ SG_ 2564428768 DNT18DA13E0_DIAG_DATA_EXT7 "ﾃﾞｰﾀ
";
CM_ SG_ 2564428768 DNT18DA13E0_DIAG_DATA_EXT6 "ﾃﾞｰﾀ
";
CM_ SG_ 2564428768 DNT18DA13E0_DIAG_DATA_EXT5 "ﾃﾞｰﾀ
";
CM_ SG_ 2564428768 DNT18DA13E0_DIAG_DATA_EXT4 "ﾃﾞｰﾀ
";
CM_ SG_ 2564428768 DNT18DA13E0_DIAG_DATA_EXT3 "ﾃﾞｰﾀ
";
CM_ SG_ 2564428768 DNT18DA13E0_DIAG_DATA_EXT2 "ﾃﾞｰﾀ
";
CM_ SG_ 2564428768 DNT18DA13E0_DIAG_DATA_EXT1 "ﾃﾞｰﾀ
";
CM_ SG_ 2564428768 DNT18DA13E0_DIAG_DATA "ﾃﾞｰﾀ
";
CM_ SG_ 2564481035 VDC18DAE00B_DIAG_DATA_EXT7 "ﾃﾞｰﾀ
";
CM_ SG_ 2564481035 VDC18DAE00B_DIAG_DATA_EXT6 "ﾃﾞｰﾀ
";
CM_ SG_ 2564481035 VDC18DAE00B_DIAG_DATA_EXT5 "ﾃﾞｰﾀ
";
CM_ SG_ 2564481035 VDC18DAE00B_DIAG_DATA_EXT4 "ﾃﾞｰﾀ
";
CM_ SG_ 2564481035 VDC18DAE00B_DIAG_DATA_EXT3 "ﾃﾞｰﾀ
";
CM_ SG_ 2564481035 VDC18DAE00B_DIAG_DATA_EXT2 "ﾃﾞｰﾀ
";
CM_ SG_ 2564481035 VDC18DAE00B_DIAG_DATA_EXT1 "ﾃﾞｰﾀ
";
CM_ SG_ 2564481035 VDC18DAE00B_DIAG_DATA "ﾃﾞｰﾀ
";
CM_ SG_ 2564426720 DNT18DA0BE0_DIAG_DATA_EXT7 "ﾃﾞｰﾀ
";
CM_ SG_ 2564426720 DNT18DA0BE0_DIAG_DATA_EXT6 "ﾃﾞｰﾀ
";
CM_ SG_ 2564426720 DNT18DA0BE0_DIAG_DATA_EXT5 "ﾃﾞｰﾀ
";
CM_ SG_ 2564426720 DNT18DA0BE0_DIAG_DATA_EXT4 "ﾃﾞｰﾀ
";
CM_ SG_ 2564426720 DNT18DA0BE0_DIAG_DATA_EXT3 "ﾃﾞｰﾀ
";
CM_ SG_ 2564426720 DNT18DA0BE0_DIAG_DATA_EXT2 "ﾃﾞｰﾀ
";
CM_ SG_ 2564426720 DNT18DA0BE0_DIAG_DATA_EXT1 "ﾃﾞｰﾀ
";
CM_ SG_ 2564426720 DNT18DA0BE0_DIAG_DATA "ﾃﾞｰﾀ
";
CM_ SG_ 1984 VDC7C0_7_0_SND_MAC "送信用MAC
";
CM_ SG_ 1984 VDC7C0_4_6_SNDMSG_CNT "送信用メッセージカウンタ
";
CM_ SG_ 1984 VDC7C0_4_4_RESET_FLG "リセットフラグ
";
CM_ SG_ 1984 VDC7C0_2_0_REQ_CALIB_CANSTO "ｷｬﾘﾌﾞﾚｰｼｮﾝ指示・CAN 停止要求信号
";
CM_ SG_ 1955 DNT7A3_DIAG_DATA_EXT7 "ﾃﾞｰﾀ
";
CM_ SG_ 1955 DNT7A3_DIAG_DATA_EXT6 "ﾃﾞｰﾀ
";
CM_ SG_ 1955 DNT7A3_DIAG_DATA_EXT5 "ﾃﾞｰﾀ
";
CM_ SG_ 1955 DNT7A3_DIAG_DATA_EXT4 "ﾃﾞｰﾀ
";
CM_ SG_ 1955 DNT7A3_DIAG_DATA_EXT3 "ﾃﾞｰﾀ
";
CM_ SG_ 1955 DNT7A3_DIAG_DATA_EXT2 "ﾃﾞｰﾀ
";
CM_ SG_ 1955 DNT7A3_DIAG_DATA_EXT1 "ﾃﾞｰﾀ
";
CM_ SG_ 1955 DNT7A3_DIAG_DATA "ﾃﾞｰﾀ
";
CM_ SG_ 2017 DNT7E1_DIAG_DATA_EXT7 "ﾃﾞｰﾀ
";
CM_ SG_ 2017 DNT7E1_DIAG_DATA_EXT6 "ﾃﾞｰﾀ
";
CM_ SG_ 2017 DNT7E1_DIAG_DATA_EXT5 "ﾃﾞｰﾀ
";
CM_ SG_ 2017 DNT7E1_DIAG_DATA_EXT4 "ﾃﾞｰﾀ
";
CM_ SG_ 2017 DNT7E1_DIAG_DATA_EXT3 "ﾃﾞｰﾀ
";
CM_ SG_ 2017 DNT7E1_DIAG_DATA_EXT2 "ﾃﾞｰﾀ
";
CM_ SG_ 2017 DNT7E1_DIAG_DATA_EXT1 "ﾃﾞｰﾀ
";
CM_ SG_ 2017 DNT7E1_DIAG_DATA "ﾃﾞｰﾀ
";
CM_ SG_ 1954 DNT7A2_DIAG_DATA_EXT7 "ﾃﾞｰﾀ
";
CM_ SG_ 1954 DNT7A2_DIAG_DATA_EXT6 "ﾃﾞｰﾀ
";
CM_ SG_ 1954 DNT7A2_DIAG_DATA_EXT5 "ﾃﾞｰﾀ
";
CM_ SG_ 1954 DNT7A2_DIAG_DATA_EXT4 "ﾃﾞｰﾀ
";
CM_ SG_ 1954 DNT7A2_DIAG_DATA_EXT3 "ﾃﾞｰﾀ
";
CM_ SG_ 1954 DNT7A2_DIAG_DATA_EXT2 "ﾃﾞｰﾀ
";
CM_ SG_ 1954 DNT7A2_DIAG_DATA_EXT1 "ﾃﾞｰﾀ
";
CM_ SG_ 1954 DNT7A2_DIAG_DATA "ﾃﾞｰﾀ
";
CM_ SG_ 2016 DNT7E0_DIAG_DATA_EXT7 "ﾃﾞｰﾀ
";
CM_ SG_ 2016 DNT7E0_DIAG_DATA_EXT6 "ﾃﾞｰﾀ
";
CM_ SG_ 2016 DNT7E0_DIAG_DATA_EXT5 "ﾃﾞｰﾀ
";
CM_ SG_ 2016 DNT7E0_DIAG_DATA_EXT4 "ﾃﾞｰﾀ
";
CM_ SG_ 2016 DNT7E0_DIAG_DATA_EXT3 "ﾃﾞｰﾀ
";
CM_ SG_ 2016 DNT7E0_DIAG_DATA_EXT2 "ﾃﾞｰﾀ
";
CM_ SG_ 2016 DNT7E0_DIAG_DATA_EXT1 "ﾃﾞｰﾀ
";
CM_ SG_ 2016 DNT7E0_DIAG_DATA "ﾃﾞｰﾀ
";
CM_ SG_ 2564550625 CECU18DBEFE1_DIAG_DATA "ﾃﾞｰﾀ
";
CM_ SG_ 2564550624 DNT18DBEFE0_DIAG_DATA "ﾃﾞｰﾀ
";
CM_ SG_ 2015 DNT7DF_7_0_DIAG_DATA "ﾃﾞｰﾀ
";
CM_ SG_ 2015 DNT7DF_2_0_DIAG_N_PCI_OR_DATA "N_PCI　 or 　ﾃﾞｰﾀ
";
CM_ SG_ 2015 DNT7DF_1_0_DIAG_N_PCI_OR_DATA "N_PCI　 or 　ﾃﾞｰﾀ
";
CM_ SG_ 2015 DNT7DF_0_0_DIAG_N_PCI "N_PCI
";
CM_ SG_ 2564481454 DMS18DAE1AE_DIAG_DATA_EXT7 "ﾃﾞｰﾀ
";
CM_ SG_ 2564481454 DMS18DAE1AE_DIAG_DATA_EXT6 "ﾃﾞｰﾀ
";
CM_ SG_ 2564481454 DMS18DAE1AE_DIAG_DATA_EXT5 "ﾃﾞｰﾀ
";
CM_ SG_ 2564481454 DMS18DAE1AE_DIAG_DATA_EXT4 "ﾃﾞｰﾀ
";
CM_ SG_ 2564481454 DMS18DAE1AE_DIAG_DATA_EXT3 "ﾃﾞｰﾀ
";
CM_ SG_ 2564481454 DMS18DAE1AE_DIAG_DATA_EXT2 "ﾃﾞｰﾀ
";
CM_ SG_ 2564481454 DMS18DAE1AE_DIAG_DATA_EXT1 "ﾃﾞｰﾀ
";
CM_ SG_ 2564481454 DMS18DAE1AE_DIAG_DATA "ﾃﾞｰﾀ
";
CM_ SG_ 2564468449 CECU18DAAEE1_DIAG_DATA_EXT7 "ﾃﾞｰﾀ
";
CM_ SG_ 2564468449 CECU18DAAEE1_DIAG_DATA_EXT6 "ﾃﾞｰﾀ
";
CM_ SG_ 2564468449 CECU18DAAEE1_DIAG_DATA_EXT5 "ﾃﾞｰﾀ
";
CM_ SG_ 2564468449 CECU18DAAEE1_DIAG_DATA_EXT4 "ﾃﾞｰﾀ
";
CM_ SG_ 2564468449 CECU18DAAEE1_DIAG_DATA_EXT3 "ﾃﾞｰﾀ
";
CM_ SG_ 2564468449 CECU18DAAEE1_DIAG_DATA_EXT2 "ﾃﾞｰﾀ
";
CM_ SG_ 2564468449 CECU18DAAEE1_DIAG_DATA_EXT1 "ﾃﾞｰﾀ
";
CM_ SG_ 2564468449 CECU18DAAEE1_DIAG_DATA "ﾃﾞｰﾀ
";
CM_ SG_ 2564481409 MCA18DAE181_DIAG_DATA_EXT7 "ﾃﾞｰﾀ
";
CM_ SG_ 2564481409 MCA18DAE181_DIAG_DATA_EXT6 "ﾃﾞｰﾀ
";
CM_ SG_ 2564481409 MCA18DAE181_DIAG_DATA_EXT5 "ﾃﾞｰﾀ
";
CM_ SG_ 2564481409 MCA18DAE181_DIAG_DATA_EXT4 "ﾃﾞｰﾀ
";
CM_ SG_ 2564481409 MCA18DAE181_DIAG_DATA_EXT3 "ﾃﾞｰﾀ
";
CM_ SG_ 2564481409 MCA18DAE181_DIAG_DATA_EXT2 "ﾃﾞｰﾀ
";
CM_ SG_ 2564481409 MCA18DAE181_DIAG_DATA_EXT1 "ﾃﾞｰﾀ
";
CM_ SG_ 2564481409 MCA18DAE181_DIAG_DATA "ﾃﾞｰﾀ
";
CM_ SG_ 2564456929 CECU18DA81E1_DIAG_DATA_EXT7 "ﾃﾞｰﾀ
";
CM_ SG_ 2564456929 CECU18DA81E1_DIAG_DATA_EXT6 "ﾃﾞｰﾀ
";
CM_ SG_ 2564456929 CECU18DA81E1_DIAG_DATA_EXT5 "ﾃﾞｰﾀ
";
CM_ SG_ 2564456929 CECU18DA81E1_DIAG_DATA_EXT4 "ﾃﾞｰﾀ
";
CM_ SG_ 2564456929 CECU18DA81E1_DIAG_DATA_EXT3 "ﾃﾞｰﾀ
";
CM_ SG_ 2564456929 CECU18DA81E1_DIAG_DATA_EXT2 "ﾃﾞｰﾀ
";
CM_ SG_ 2564456929 CECU18DA81E1_DIAG_DATA_EXT1 "ﾃﾞｰﾀ
";
CM_ SG_ 2564456929 CECU18DA81E1_DIAG_DATA "ﾃﾞｰﾀ
";
CM_ SG_ 2564481477 BEV18DAE1C5_DIAG_DATA_EXT7 "ﾃﾞｰﾀ
";
CM_ SG_ 2564481477 BEV18DAE1C5_DIAG_DATA_EXT6 "ﾃﾞｰﾀ
";
CM_ SG_ 2564481477 BEV18DAE1C5_DIAG_DATA_EXT5 "ﾃﾞｰﾀ
";
CM_ SG_ 2564481477 BEV18DAE1C5_DIAG_DATA_EXT4 "ﾃﾞｰﾀ
";
CM_ SG_ 2564481477 BEV18DAE1C5_DIAG_DATA_EXT3 "ﾃﾞｰﾀ
";
CM_ SG_ 2564481477 BEV18DAE1C5_DIAG_DATA_EXT2 "ﾃﾞｰﾀ
";
CM_ SG_ 2564481477 BEV18DAE1C5_DIAG_DATA_EXT1 "ﾃﾞｰﾀ
";
CM_ SG_ 2564481477 BEV18DAE1C5_DIAG_DATA "ﾃﾞｰﾀ
";
CM_ SG_ 2564474337 CECU18DAC5E1_DIAG_DATA_EXT7 "ﾃﾞｰﾀ
";
CM_ SG_ 2564474337 CECU18DAC5E1_DIAG_DATA_EXT6 "ﾃﾞｰﾀ
";
CM_ SG_ 2564474337 CECU18DAC5E1_DIAG_DATA_EXT5 "ﾃﾞｰﾀ
";
CM_ SG_ 2564474337 CECU18DAC5E1_DIAG_DATA_EXT4 "ﾃﾞｰﾀ
";
CM_ SG_ 2564474337 CECU18DAC5E1_DIAG_DATA_EXT3 "ﾃﾞｰﾀ
";
CM_ SG_ 2564474337 CECU18DAC5E1_DIAG_DATA_EXT2 "ﾃﾞｰﾀ
";
CM_ SG_ 2564474337 CECU18DAC5E1_DIAG_DATA_EXT1 "ﾃﾞｰﾀ
";
CM_ SG_ 2564474337 CECU18DAC5E1_DIAG_DATA "ﾃﾞｰﾀ
";
CM_ SG_ 2564481299 EPS18DAE113_DIAG_DATA "ﾃﾞｰﾀ
";
CM_ SG_ 2564428769 CECU18DA13E1_DIAG_DATA "ﾃﾞｰﾀ
";
CM_ SG_ 2564481292 BST18DAE10C_DIAG_DATA_EXT7 "ﾃﾞｰﾀ
";
CM_ SG_ 2564481292 BST18DAE10C_DIAG_DATA_EXT6 "ﾃﾞｰﾀ
";
CM_ SG_ 2564481292 BST18DAE10C_DIAG_DATA_EXT5 "ﾃﾞｰﾀ
";
CM_ SG_ 2564481292 BST18DAE10C_DIAG_DATA_EXT4 "ﾃﾞｰﾀ
";
CM_ SG_ 2564481292 BST18DAE10C_DIAG_DATA_EXT3 "ﾃﾞｰﾀ
";
CM_ SG_ 2564481292 BST18DAE10C_DIAG_DATA_EXT2 "ﾃﾞｰﾀ
";
CM_ SG_ 2564481292 BST18DAE10C_DIAG_DATA_EXT1 "ﾃﾞｰﾀ
";
CM_ SG_ 2564481292 BST18DAE10C_DIAG_DATA "ﾃﾞｰﾀ
";
CM_ SG_ 2564426977 CECU18DA0CE1_DIAG_DATA "ﾃﾞｰﾀ
";
CM_ SG_ 1900 BST76C_7_0_DIAG_DATA "ﾃﾞｰﾀ
";
CM_ SG_ 1900 BST76C_2_0_DIAG_N_PCI_OR_DATA "N_PCI　 or 　ﾃﾞｰﾀ
";
CM_ SG_ 1900 BST76C_1_0_DIAG_N_PCI_OR_DATA "N_PCI　 or 　ﾃﾞｰﾀ
";
CM_ SG_ 1900 BST76C_0_0_DIAG_N_PCI "N_PCI
";
CM_ SG_ 1892 DCM764_7_0_DIAG_DATA "ﾃﾞｰﾀ
";
CM_ SG_ 1892 DCM764_2_0_DIAG_N_PCI_OR_DATA "N_PCI　 or 　ﾃﾞｰﾀ
";
CM_ SG_ 1892 DCM764_1_0_DIAG_N_PCI_OR_DATA "N_PCI　 or 　ﾃﾞｰﾀ
";
CM_ SG_ 1892 DCM764_0_0_DIAG_N_PCI "N_PCI
";
CM_ SG_ 2564481291 VDC18DAE10B_DIAG_DATA_EXT7 "ﾃﾞｰﾀ
";
CM_ SG_ 2564481291 VDC18DAE10B_DIAG_DATA_EXT6 "ﾃﾞｰﾀ
";
CM_ SG_ 2564481291 VDC18DAE10B_DIAG_DATA_EXT5 "ﾃﾞｰﾀ
";
CM_ SG_ 2564481291 VDC18DAE10B_DIAG_DATA_EXT4 "ﾃﾞｰﾀ
";
CM_ SG_ 2564481291 VDC18DAE10B_DIAG_DATA_EXT3 "ﾃﾞｰﾀ
";
CM_ SG_ 2564481291 VDC18DAE10B_DIAG_DATA_EXT2 "ﾃﾞｰﾀ
";
CM_ SG_ 2564481291 VDC18DAE10B_DIAG_DATA_EXT1 "ﾃﾞｰﾀ
";
CM_ SG_ 2564481291 VDC18DAE10B_DIAG_DATA "ﾃﾞｰﾀ
";
CM_ SG_ 2564426721 CECU18DA0BE1_DIAG_DATA "ﾃﾞｰﾀ
";
CM_ SG_ 1848 VDC738_7_0_DIAG_DATA "ﾃﾞｰﾀ
";
CM_ SG_ 1848 VDC738_2_0_DIAG_N_PCI_OR_DATA "N_PCI　 or 　ﾃﾞｰﾀ
";
CM_ SG_ 1848 VDC738_1_0_DIAG_N_PCI_OR_DATA "N_PCI　 or 　ﾃﾞｰﾀ
";
CM_ SG_ 1848 VDC738_0_0_DIAG_N_PCI "N_PCI
";
CM_ SG_ 1840 DCM730_7_0_DIAG_DATA "ﾃﾞｰﾀ
";
CM_ SG_ 1840 DCM730_2_0_DIAG_N_PCI_OR_DATA "N_PCI　 or 　ﾃﾞｰﾀ
";
CM_ SG_ 1840 DCM730_1_0_DIAG_N_PCI_OR_DATA "N_PCI　 or 　ﾃﾞｰﾀ
";
CM_ SG_ 1840 DCM730_0_0_DIAG_N_PCI "N_PCI
";
CM_ SG_ 2564481363 ABG18DAE153_DIAG_DATA "ﾃﾞｰﾀ
";
CM_ SG_ 2564445153 CECU18DA53E1_DIAG_DATA "ﾃﾞｰﾀ
";
CM_ SG_ 1774 CECU6EE_7_0_DESTINATION_INFO "仕向地情報
";
CM_ SG_ 1774 CECU6EE_7_4_VEHICLE_SERIES "車系情報
";
CM_ SG_ 1774 CECU6EE_6_0_DESTINATION_CODE "仕向地ｺｰﾄﾞ
";
CM_ SG_ 1774 CECU6EE_5_0_EYE_VERSION_INFO "ｱｲｻｲﾄVer情報
";
CM_ SG_ 1774 CECU6EE_5_4_VEHICLE_TYPE "車型情報
";
CM_ SG_ 1774 CECU6EE_5_6_PRODUCTION_BASE "生産拠点
";
CM_ SG_ 1774 CECU6EE_4_2_WHEEL_DRIVE_TYPE "駆動方式
";
CM_ SG_ 1774 CECU6EE_4_3_3RD_SHEAT_EQUIPMENT "3rdｼｰﾄ有無
";
CM_ SG_ 1774 CECU6EE_4_4_FLG_XMODE "Xﾓｰﾄﾞ有無
";
CM_ SG_ 1774 CECU6EE_4_6_ISS_EQUIPMENT "ISS有無
";
CM_ SG_ 1774 CECU6EE_4_7_TIRE_INFO "ﾀｲﾔ情報
";
CM_ SG_ 1774 CECU6EE_1_0_MSG_COUNTER "ﾒｯｾｰｼﾞｶｳﾝﾀ
";
CM_ SG_ 1774 CECU6EE_1_5_BEV_WHEEL_DRIVE_TYPE "駆動方式(BEV)
";
CM_ SG_ 1774 CECU6EE_0_0_CHECK_SUM "ﾁｪｯｸｻﾑ
";
CM_ SG_ 1773 CECU6ED_7_0_VEHICLE_TYPE_DETAIL "車型情報(詳細)
";
CM_ SG_ 1773 CECU6ED_5_0_TRANSMISSION_TYPE "ﾄﾗﾝｽﾐｯｼｮﾝ情報
";
CM_ SG_ 1773 CECU6ED_5_4_HANDLE "ﾊﾝﾄﾞﾙ情報
";
CM_ SG_ 1773 CECU6ED_4_0_VEHICLE_HEIGHT "車高情報
";
CM_ SG_ 1773 CECU6ED_4_4_SEATHEATER_EQUIPMENT "ｼｰﾄﾋｰﾀｰ有無
";
CM_ SG_ 1773 CECU6ED_3_0_YEAR_CHANGE "年改情報
";
CM_ SG_ 1773 CECU6ED_3_4_HEV_INFO "HEV情報
";
CM_ SG_ 1773 CECU6ED_1_0_MSG_COUNTER "ﾒｯｾｰｼﾞｶｳﾝﾀ
";
CM_ SG_ 1773 CECU6ED_0_0_CHECK_SUM "ﾁｪｯｸｻﾑ
";
CM_ SG_ 996 CECU3E4_7_0_SSM_COMM_INFO "SSM通信情報
";
CM_ SG_ 996 CECU3E4_6_0_CHARGE_LEVEL_ENG_RUN "エンジンRUN中充電レベル
";
CM_ SG_ 996 CECU3E4_6_4_CHARGE_LEVEL_IGN_ON "IG-ONエンスト中充電レベル
";
CM_ SG_ 996 CECU3E4_5_0_GENERATOR_OVER_FLG "発電機過大ﾌﾗｸﾞ
";
CM_ SG_ 996 CECU3E4_5_3_DIAG_COM_REQ "ﾃﾚﾏ診断通信要求
";
CM_ SG_ 996 CECU3E4_5_4_HEADS_UP_FLG "注意喚起ﾌﾗｸﾞ
";
CM_ SG_ 996 CECU3E4_3_0_WASH_CAR_MODE_STS "洗車モード状態
";
CM_ SG_ 996 CECU3E4_2_0_POW_ON_FIX_MODE_STS "電源ON固定モード状態
";
CM_ SG_ 996 CECU3E4_2_3_PET_MODE_STS "ペットモード状態
";
CM_ SG_ 996 CECU3E4_2_6_SHUT_DOWN_MODE_STS "シャットダウンモード遷移可否状態
";
CM_ SG_ 996 CECU3E4_2_7_OCCUPATION_CSTM "乗員検知設定値
";
CM_ SG_ 996 CECU3E4_1_0_MSG_COUNTER "ﾒｯｾｰｼﾞｶｳﾝﾀ
";
CM_ SG_ 996 CECU3E4_0_0_CHECK_SUM "ﾁｪｯｸｻﾑ
";
CM_ SG_ 981 CGW3D5_7_0_SYNC_MSG_MAC "同期メッセージ用MAC
";
CM_ SG_ 981 CGW3D5_4_4_RESET_COUNTER "ﾘｾｯﾄｶｳﾝﾀ
";
CM_ SG_ 981 CGW3D5_1_0_TRIP_COUNTER "ﾄﾘｯﾌﾟｶｳﾝﾀ
";
CM_ SG_ 1280 CGW500_1_4_ActiveWakeUpBit "Active Wakeup ﾌﾗｸﾞ
";
CM_ SG_ 1280 CGW500_0_0_SourceNodeID "送信元ID
";
CM_ SG_ 1633 CECU661_7_0_PRESENT_TIME_SEC "現在時刻(秒)
";
CM_ SG_ 1633 CECU661_6_0_PRESENT_TIME_MIN "現在時刻(分)
";
CM_ SG_ 1633 CECU661_5_0_PRESENT_TIME_HOUR "現在時刻(時)
";
CM_ SG_ 1633 CECU661_4_0_PRESENT_DAY "現在年月日(日)
";
CM_ SG_ 1633 CECU661_3_0_PRESENT_MONTH "現在年月日(月)
";
CM_ SG_ 1633 CECU661_2_0_PRESENT_YEAR "現在年月日(年)
";
CM_ SG_ 1632 CGW660_7_0_COUNT_TIME "時間ｶｳﾝﾀ
";
CM_ SG_ 1632 CGW660_3_0_COUNT_TRIP "Tripｶｳﾝﾀ
";
CM_ SG_ 1632 CGW660_1_0_SUB_ID "ｻﾌﾞID
";
CM_ SG_ 1752 DCM6D8_7_0_PRESENT_TIME_SEC "現在時刻情報(秒)
";
CM_ SG_ 1752 DCM6D8_6_0_PRESENT_TIME_MIN "現在時刻情報(分)
";
CM_ SG_ 1752 DCM6D8_5_0_PRESENT_TIME_HOUR "現在時刻情報(時)
";
CM_ SG_ 1752 DCM6D8_4_0_PRESENT_DAY "現在時刻情報(日)
";
CM_ SG_ 1752 DCM6D8_3_0_PRESENT_MONTH "現在時刻情報(月)
";
CM_ SG_ 1752 DCM6D8_2_0_DATA_COLLECT_INTERVAL "データ収集間隔設定
";
CM_ SG_ 1752 DCM6D8_1_0_MSG_COUNTER "ﾒｯｾｰｼﾞｶｳﾝﾀ
";
CM_ SG_ 1752 DCM6D8_1_4_PRESS_SOS_BUTTON "SOSﾎﾞﾀﾝ押下
";
CM_ SG_ 1752 DCM6D8_0_0_CHECK_SUM "ﾁｪｯｸｻﾑ
";
CM_ SG_ 1744 CECU6D0_4_0_OTA_ABORT "OTA中止
";
CM_ SG_ 1744 CECU6D0_4_1_OTA_SUSPEND "OTA中断
";
CM_ SG_ 1744 CECU6D0_4_2_OTA_SEQUENCE "OTA実行シーケンス
";
CM_ SG_ 1744 CECU6D0_1_0_MSG_COUNTER "ﾒｯｾｰｼﾞｶｳﾝﾀ
";
CM_ SG_ 1744 CECU6D0_1_4_OTA_STATUS_UPDATE "OTAステータス アップデート実行中
";
CM_ SG_ 1744 CECU6D0_0_0_CHECK_SUM "ﾁｪｯｸｻﾑ
";
CM_ SG_ 1743 DCM6CF_6_6_AACN_FLG "AACNフラグ
";
CM_ SG_ 1743 DCM6CF_5_0_EMERGENCY_CALL_ON_OFF "緊急通報ON/OFF
";
CM_ SG_ 1743 DCM6CF_4_2_STR_HEATER_ON_OFF "ｽﾃｱﾘﾝｸﾞﾋｰﾀｰ ON/OFF
";
CM_ SG_ 1743 DCM6CF_3_0_RES_CONTRACT_INFO "ﾘﾓｽﾀ契約情報
";
CM_ SG_ 1743 DCM6CF_3_1_REQ_ST_ON "Request ST ON
";
CM_ SG_ 1743 DCM6CF_3_3_ON_SIGN "E/G start signal
";
CM_ SG_ 1743 DCM6CF_3_5_REQ_PARKLIGHT_HORN "Request park light ＆Horn
";
CM_ SG_ 1743 DCM6CF_2_1_DCM_FAILURE_STATUS "DCM故障ｽﾃｰﾀｽ
";
CM_ SG_ 1743 DCM6CF_2_2_REQ_WINDOW_STATUS "窓&ｻﾝﾙｰﾌ開閉状態要求
";
CM_ SG_ 1743 DCM6CF_1_0_MSG_COUNTER "ﾒｯｾｰｼﾞｶｳﾝﾀ
";
CM_ SG_ 1743 DCM6CF_1_6_DKY_PROV_STS "DKCU向けDKY契約状態通知
";
CM_ SG_ 1743 DCM6CF_1_7_PNC_PROV_STS "EVCC向けPnC契約状態通知
";
CM_ SG_ 1743 DCM6CF_0_0_CHECK_SUM "ﾁｪｯｸｻﾑ
";
CM_ SG_ 1749 CECU6D5_6_0_CSTM_FMHD "ウェルカムランプ(降車)
";
CM_ SG_ 1749 CECU6D5_5_0_CSTM_WRH "ワイパ連動オートライト機能ON/OFF設定
";
CM_ SG_ 1749 CECU6D5_5_1_CSTM_LMHD "ウェルカムランプ(乗車)
";
CM_ SG_ 1749 CECU6D5_5_3 "北米ウェルカムランプ(リービング)（カスタマイズ）
";
CM_ SG_ 1749 CECU6D5_5_5_CSTM_HBA "HBA 有無設定
";
CM_ SG_ 1749 CECU6D5_5_7_ADB_ACTIVE "ADB有無設定
";
CM_ SG_ 1749 CECU6D5_4_0_JUDGE_ILL "照度判定
";
CM_ SG_ 1749 CECU6D5_4_1_HEADLAMP_AUTO_SW "ライティングAUTO SW 出力信号
";
CM_ SG_ 1749 CECU6D5_4_2_IND_ACTIVE_HBA "HBA 作動灯
";
CM_ SG_ 1749 CECU6D5_4_4_FGT_LGTOFF_WARNING "ライト消し忘れ警報
";
CM_ SG_ 1749 CECU6D5_3_0_CRN_R_REQ "コーナリングランプR 出力要求
";
CM_ SG_ 1749 CECU6D5_3_2_CRN_L_REQ "コーナリングランプL 出力要求
";
CM_ SG_ 1749 CECU6D5_3_4_FMH "フォローミーホーム出力情報
";
CM_ SG_ 1749 CECU6D5_3_5_LMH "リードミーホーム出力情報
";
CM_ SG_ 1749 CECU6D5_2_0_LGT_1 "ライティング1 リレー出力要求
";
CM_ SG_ 1749 CECU6D5_2_1_LGT_LO "ライティングLo リレー出力要求
";
CM_ SG_ 1749 CECU6D5_2_2_LGT_HI "ライティングHi リレー出力要求
";
CM_ SG_ 1749 CECU6D5_2_4_FFOG_RELAY_REQ "Fフォグランプリレー出力要求
";
CM_ SG_ 1749 CECU6D5_2_5_RFOG_RELAY_REQ "Rフォグランプリレー出力要求
";
CM_ SG_ 1749 CECU6D5_2_6_LGT_DRL "DRL リレー出力要求
";
CM_ SG_ 1749 CECU6D5_1_0_MSG_COUNTER "ﾒｯｾｰｼﾞｶｳﾝﾀ
";
CM_ SG_ 1749 CECU6D5_0_0_CHECK_SUM "ﾁｪｯｸｻﾑ
";
CM_ SG_ 1753 CECU6D9_2_0_RCC_DOOR_LOCK_REQ "RCC ドアロック要求
";
CM_ SG_ 1753 CECU6D9_2_1_RCC_KEY_SEARCH_REQ "RCC アクセスキー確認要求
";
CM_ SG_ 1753 CECU6D9_2_2_RCC_BWAM_SETTING "バッテリ温調設定
";
CM_ SG_ 1753 CECU6D9_1_0_MSG_COUNTER "ﾒｯｾｰｼﾞｶｳﾝﾀ
";
CM_ SG_ 1753 CECU6D9_1_4_RCC_FLG "RCC実行中フラグ
";
CM_ SG_ 1753 CECU6D9_0_0_CHECK_SUM "ﾁｪｯｸｻﾑ
";
CM_ SG_ 723 CECU2D3_2_0_IGA_ON_REQUEST "IGaON要求
";
CM_ SG_ 723 CECU2D3_2_1_IGA_OFF_REQUEST "IGaOFF要求
";
CM_ SG_ 723 CECU2D3_2_2_IGB_ON_REQUEST "IGbON要求
";
CM_ SG_ 723 CECU2D3_2_3_IGB_OFF_REQUEST "IGbOFF要求
";
CM_ SG_ 723 CECU2D3_2_4_READY_ON_REQUEST "ReadyON要求
";
CM_ SG_ 723 CECU2D3_2_5_IGA_STATE "IGa状態
";
CM_ SG_ 723 CECU2D3_2_6_IGB_STATE "IGb状態
";
CM_ SG_ 723 CECU2D3_2_7_FACT_MODE "電源遷移制限モード
";
CM_ SG_ 723 CECU2D3_1_0_MSG_COUNTER "ﾒｯｾｰｼﾞｶｳﾝﾀ
";
CM_ SG_ 723 CECU2D3_0_0_CHECK_SUM "ﾁｪｯｸｻﾑ
";
CM_ SG_ 1747 CECU6D3_3_0_PRE_CONDITIONING "プレコンディショニングフラグ
";
CM_ SG_ 1747 CECU6D3_2_0_READY_OFF_REQUEST "ReadyOFF要求
";
CM_ SG_ 1747 CECU6D3_2_1_HVSYST_REQUEST "高電圧システム起動要求
";
CM_ SG_ 1747 CECU6D3_2_2_RCC_HVSYST_REQUEST "RCC 高電圧システム起動要求
";
CM_ SG_ 1747 CECU6D3_2_3_BAT_INFO_GET_FLG "バッテリー情報取得フラグ
";
CM_ SG_ 1747 CECU6D3_1_0_MSG_COUNTER "ﾒｯｾｰｼﾞｶｳﾝﾀ
";
CM_ SG_ 1747 CECU6D3_0_0_CHECK_SUM "ﾁｪｯｸｻﾑ
";
CM_ SG_ 930 MET3A2_7_0_FUEL_AMOUNT "残燃料表示
";
CM_ SG_ 930 MET3A2_6_0_SEATBELT_RR_RH "ｼｰﾄﾍﾞﾙﾄﾊﾞｯｸﾙSW　後席右
";
CM_ SG_ 930 MET3A2_6_1_SEATBELT_RR_CTR "ｼｰﾄﾍﾞﾙﾄﾊﾞｯｸﾙSW　後席中央
";
CM_ SG_ 930 MET3A2_6_2_SEATBELT_RR_LH "ｼｰﾄﾍﾞﾙﾄﾊﾞｯｸﾙSW　後席左
";
CM_ SG_ 930 MET3A2_6_3_SEATBELT_THIRD_RH "ｼｰﾄﾍﾞﾙﾄﾊﾞｯｸﾙSW　3rd後席右
";
CM_ SG_ 930 MET3A2_6_4_SEATBELT_THIRD_CTR "ｼｰﾄﾍﾞﾙﾄﾊﾞｯｸﾙSW　3rd後席中央
";
CM_ SG_ 930 MET3A2_6_5_SEATBELT_THIRD_LH "ｼｰﾄﾍﾞﾙﾄﾊﾞｯｸﾙSW　3rd後席左
";
CM_ SG_ 930 MET3A2_5_0_FLG_RR_REMINDER "幼児置き去り警報実施フラグ
";
CM_ SG_ 930 MET3A2_2_0_ODO_DETAIL "オドﾒｰﾀ値
";
CM_ SG_ 930 MET3A2_1_0_MSG_COUNTER "ﾒｯｾｰｼﾞｶｳﾝﾀ
";
CM_ SG_ 930 MET3A2_1_4_FAIL_DISP "MET表示フェールフラグ
";
CM_ SG_ 930 MET3A2_0_0_CHECK_SUM "ﾁｪｯｸｻﾑ
";
CM_ SG_ 1677 MET68D_7_0_STATUS_WASHER_LAMP "ｳｫｯｼｬ残量警告灯状態
";
CM_ SG_ 1677 MET68D_7_1_OILPRESSURE_SW "ｵｲﾙﾌﾟﾚｯｼｬSW状態
";
CM_ SG_ 1677 MET68D_7_2_FLG_EAM "EAM車両装備情報
";
CM_ SG_ 1677 MET68D_7_3_CSTM_IND_RED "ｱｲｻｲﾄﾓﾆﾀｰ変更設定赤色ｲﾝｼﾞｹｰﾀ
";
CM_ SG_ 1677 MET68D_7_4_CSTM_IND_YELLOW "ｱｲｻｲﾄﾓﾆﾀｰ変更設定黄色ｲﾝｼﾞｹｰﾀ
";
CM_ SG_ 1677 MET68D_7_5_CSTM_IND_GREEN "ｱｲｻｲﾄﾓﾆﾀｰ変更設定緑色ｲﾝｼﾞｹｰﾀ
";
CM_ SG_ 1677 MET68D_7_6_REQ_CSTM_SRH "SRHｶｽﾀﾏｲｽﾞ変更要求
";
CM_ SG_ 1677 MET68D_7_7_CSTM_SRH "SRHｶｽﾀﾏｲｽﾞ変更設定
";
CM_ SG_ 1677 MET68D_6_5_REQ_CHG_CSTM_RAB "RABｶｽﾀﾏｲｽﾞ要求変更
";
CM_ SG_ 1677 MET68D_6_6_CSTM_RAB "ｿﾅｰｶｽﾀﾏｲｽﾞ変更設定(RABON/OFF)
";
CM_ SG_ 1677 MET68D_6_7_CSTM_SONNER "ｿﾅｰｶｽﾀﾏｲｽﾞ変更設定(ｿﾅｰON/OFF)
";
CM_ SG_ 1677 MET68D_5_0_TEMP_FOR_PPA "歩行者保護A/B用温度
";
CM_ SG_ 1677 MET68D_2_0_ODO "ｵﾄﾞﾒｰﾀ値
";
CM_ SG_ 1677 MET68D_1_0_MSG_COUNTER "ﾒｯｾｰｼﾞｶｳﾝﾀ
";
CM_ SG_ 1677 MET68D_1_4_RESET_CSTM_TPMS_RAEB "ｶｽﾀﾏｲｽﾞﾘｾｯﾄ要求(TPMS/RAEB)
";
CM_ SG_ 1677 MET68D_1_5_REQ_CHG_CSTM_TPMS "TPMSｶｽﾀﾏｲｽﾞ要求変更
";
CM_ SG_ 1677 MET68D_1_6_CSTM_TIRE_UNIT "ﾀｲﾔ空気圧表示単位設定
";
CM_ SG_ 1677 MET68D_0_0_CHECK_SUM "ﾁｪｯｸｻﾑ
";
CM_ SG_ 915 MET393_7_0_REQ_CHG_CSTM_EYE "ｱｲｻｲﾄｶｽﾀﾏｲｽﾞ要求変更
";
CM_ SG_ 915 MET393_7_1_REQ_RESET_CSTM_EYE "ｱｲｻｲﾄｶｽﾀﾏｲｽﾞﾘｾｯﾄ要求
";
CM_ SG_ 915 MET393_7_2_CSTM_ALK "ｱｲｻｲﾄｶｽﾀﾏｲｽﾞ変更設定(車線中央維持)
";
CM_ SG_ 915 MET393_7_3_CSTM_HBA "ｱｲｻｲﾄｶｽﾀﾏｲｽﾞ変更設定値(HBA)
";
CM_ SG_ 915 MET393_7_4_CSTM_MIS_AT_BACK "ｱｲｻｲﾄｶｽﾀﾏｲｽﾞ変更設定(AT誤後進抑制制御)
";
CM_ SG_ 915 MET393_7_6_CSTM_ACC_CONT "ｱｲｻｲﾄｶｽﾀﾏｲｽﾞ変更設定(ACC加速特性)
";
CM_ SG_ 915 MET393_6_0_R_DIFF_TEMP "R.DIFF油温ｾﾝｻ
";
CM_ SG_ 915 MET393_5_2_WARN_R_DIFF_TEMP "R.DIFF油温警告灯
";
CM_ SG_ 915 MET393_5_4_ADAPTIVECC_NOALIVE "追従ｸﾙｺﾝ未着判定ﾌﾗｸﾞ
";
CM_ SG_ 915 MET393_5_5_DUAL_RANGE_LO "ﾃﾞｭｱﾙﾚﾝｼﾞLo
";
CM_ SG_ 915 MET393_5_6_CSTM_SPD_LIMITER "ｱｲｻｲﾄｶｽﾀﾏｲｽﾞ変更設定(SAS)
";
CM_ SG_ 915 MET393_5_7_CSTM_LANE_CONT "ｱｲｻｲﾄｶｽﾀﾏｲｽﾞ変更設定(通行車線)
";
CM_ SG_ 915 MET393_4_0_FUEL_LEVEL_RESIST "燃料ﾚﾍﾞﾙｾﾝｻ抵抗値
";
CM_ SG_ 915 MET393_3_5_SI_DRIVE_SW "SI-DRIVE SW情報
";
CM_ SG_ 915 MET393_2_0_OUTTEMP_FOR_DIAG "診断用外気温
";
CM_ SG_ 915 MET393_1_0_MSG_COUNTER "ﾒｯｾｰｼﾞｶｳﾝﾀ
";
CM_ SG_ 915 MET393_1_4_CSTM_IND_BLUE "ｱｲｻｲﾄﾓﾆﾀｰ変更設定青色ｲﾝｼﾞｹｰﾀ
";
CM_ SG_ 915 MET393_1_5_CSTM_AES_CONT "ｱｲｻｲﾄｶｽﾀﾏｲｽﾞ変更設定(AES)
";
CM_ SG_ 915 MET393_1_6_FLG_PEDESTRIAN_AIRBAG "歩行者保護A/B有無ﾌﾗｸﾞ
";
CM_ SG_ 915 MET393_0_0_CHECK_SUM "ﾁｪｯｸｻﾑ
";
CM_ SG_ 912 MET390_7_0_VDC_ON_OFF "VDC SW情報
";
CM_ SG_ 912 MET390_7_2_RR_DOOR_RECORD_L "後席ﾄﾞｱ開履歴送信（左）
";
CM_ SG_ 912 MET390_7_3_RR_DOOR_RECORD_R "後席ﾄﾞｱ開履歴送信（右）
";
CM_ SG_ 912 MET390_7_4_REQ_CHG_CSTM_PSM "PSMｶｽﾀﾏｲｽﾞ要求変更
";
CM_ SG_ 912 MET390_7_5_REQ_RESET_CSTM_PSM "PSM　ｶｽﾀﾏｲｽﾞﾘｾｯﾄ要求
";
CM_ SG_ 912 MET390_7_6_CSTM_MIR_AFOLD_CONT "ﾄﾞｱﾐﾗｰｶｽﾀﾏｲｽﾞ変更設定(ｵｰﾄ電動格納ﾐﾗｰ)
";
CM_ SG_ 912 MET390_7_7_CSTM_MIR_RTILT_CONT "ﾄﾞｱﾐﾗｰｶｽﾀﾏｲｽﾞ変更設定(ﾘﾊﾞｰｽ連動ﾐﾗｰ)
";
CM_ SG_ 912 MET390_6_0_SEATBELT_DRVR "ｼｰﾄﾍﾞﾙﾄﾊﾞｯｸﾙSW　D席
";
CM_ SG_ 912 MET390_6_1_SEATBELT_PASS "ｼｰﾄﾍﾞﾙﾄﾊﾞｯｸﾙSW　P席
";
CM_ SG_ 912 MET390_6_2_TURN_SIG_LEFT "ﾀｰﾝ左出力信号
";
CM_ SG_ 912 MET390_6_3_TURN_SIG_RIGHT "ﾀｰﾝ右出力信号
";
CM_ SG_ 912 MET390_6_4_BRIGHT_SW "ﾌﾞﾗｲﾄ信号
";
CM_ SG_ 912 MET390_6_5_FAIL_UART_WA_BOX "WA-BOX UART通信異常
";
CM_ SG_ 912 MET390_6_6_ISS_OFF_SW "ISS OFFｽｲｯﾁ状態
";
CM_ SG_ 912 MET390_6_7_FLG_DMS "DMS車両装備情報
";
CM_ SG_ 912 MET390_5_0_ILL_BRIGHTNESS "ｲﾙﾐ輝度値
";
CM_ SG_ 912 MET390_4_0_OUTTEMP_FOR_IND "表示用外気温
";
CM_ SG_ 912 MET390_3_0_UNIT_SPEED_TRIP "速度計/距離計表示単位
";
CM_ SG_ 912 MET390_3_1_FLG_EYESIGHT "EyeSightﾌﾗｸﾞ
";
CM_ SG_ 912 MET390_3_2_FLG_ISS "ISSﾌﾗｸﾞ
";
CM_ SG_ 912 MET390_3_3_FLG_HEV "HEVﾌﾗｸﾞ
";
CM_ SG_ 912 MET390_3_4_FLG_IMB "IMﾌﾗｸﾞ
";
CM_ SG_ 912 MET390_3_5_TIRE_SIZE "ﾀｲﾔ径情報
";
CM_ SG_ 912 MET390_3_6_FLG_XMODE "Xモード車両装備情報
";
CM_ SG_ 912 MET390_2_0_VEHICLE_SERIES "車型情報
";
CM_ SG_ 912 MET390_2_3_DESTINATION "仕向地情報
";
CM_ SG_ 912 MET390_2_7_PASS_DOOR_RECORD "助手席ﾄﾞｱ開履歴送信
";
CM_ SG_ 912 MET390_1_0_MSG_COUNTER "ﾒｯｾｰｼﾞｶｳﾝﾀ
";
CM_ SG_ 912 MET390_1_4_WAKE_UP_FRAME "ｳｪｲｸｱｯﾌﾟﾌﾚｰﾑ識別ﾌﾗｸﾞ
";
CM_ SG_ 912 MET390_1_5_REQ_COMM_CONT "通信継続要求ﾌﾗｸﾞ
";
CM_ SG_ 912 MET390_1_6_DMS_ID_SET "DMS ID設定完了ﾌﾗｸﾞ
";
CM_ SG_ 912 MET390_1_7_FAIL_EEPROM "EEPROMﾌｪｰﾙ
";
CM_ SG_ 912 MET390_0_0_CHECK_SUM "ﾁｪｯｸｻﾑ
";
CM_ SG_ 1291 MET50B_1_4_ActiveWakeUpBit "Active Wakeup ﾌﾗｸﾞ
";
CM_ SG_ 1291 MET50B_0_0_SourceNodeID "送信元ID
";
CM_ SG_ 28 STA01C_7_0_SND_MAC "送信用MAC
";
CM_ SG_ 28 STA01C_4_4_RESET_FLG "ﾘｾｯﾄﾌﾗｸﾞ
";
CM_ SG_ 28 STA01C_4_6_SNDMSG_CNT "送信用ﾒｯｾｰｼﾞｶｳﾝﾀ
";
CM_ SG_ 28 STA01C_3_0_MSG_COUNTER "ﾒｯｾｰｼﾞｶｳﾝﾀ
";
CM_ SG_ 28 STA01C_3_4_CODE_ERR "ｴﾗｰｺｰﾄﾞﾋﾞｯﾄ
";
CM_ SG_ 28 STA01C_3_7_ABS_ANGLE_DETECT "絶対角検出ﾌﾗｸﾞ
";
CM_ SG_ 28 STA01C_2_0_FLG_CALIB "ｷｬﾘﾌﾞﾚｰｼｮﾝ
";
CM_ SG_ 28 STA01C_2_1_FLG_OK "OKﾌﾗｸﾞ
";
CM_ SG_ 28 STA01C_1_0_SAS_SIG "ｾﾝｻ信号ﾋﾞｯﾄ
";
CM_ SG_ 2 STA002_4_0_CHECK_SUM "ﾁｪｯｸｻﾑﾋﾞｯﾄ
";
CM_ SG_ 2 STA002_3_0_FLG_MSG_WATCHING "ﾒｯｾｰｼﾞ監視中ﾌﾗｸﾞ
";
CM_ SG_ 2 STA002_3_1_MSG_COUNTER "SASﾒｯｾｰｼﾞｶｳﾝﾀ
";
CM_ SG_ 2 STA002_2_0_CODE_ERR "ｴﾗｰｺｰﾄﾞﾋﾞｯﾄ
";
CM_ SG_ 2 STA002_2_4_ABS_ANGLE_DETECT "絶対角検出ﾌﾗｸﾞ
";
CM_ SG_ 2 STA002_2_5_FLG_CALIB "ｷｬﾘﾌﾞﾚｰｼｮﾝ
";
CM_ SG_ 2 STA002_2_6_FLG_OK "OKﾌﾗｸﾞ
";
CM_ SG_ 2 STA002_1_0_SAS_SIG "ｾﾝｻ信号ﾋﾞｯﾄ
";
CM_ SG_ 1349 STA545_7_0_NETWORK_STATUS "ﾈｯﾄﾜｰｸｽﾃｰﾀｽ
";
CM_ SG_ 1657 TPM679_3_0_STATE_TPMS "TPMS状態ﾌﾗｸﾞ
";
CM_ SG_ 1657 TPM679_3_2_DEFINED_STATE_TPMS "TPMS状態確定
";
CM_ SG_ 1657 TPM679_3_4_MODE_SELECT_TPMS "TPMSカスタマイズMode種別
";
CM_ SG_ 1657 TPM679_2_0_WARN_TPMS "TPMSｳｫｰﾆﾝｸﾞ
";
CM_ SG_ 1657 TPM679_2_3_INTERRUPT "割り込み表示
";
CM_ SG_ 1657 TPM679_2_5_CHECKLUMP_TPMS "TPMSチェックランプ点灯信号
";
CM_ SG_ 1657 TPM679_1_0_MSG_COUNTER "ﾒｯｾｰｼﾞｶｳﾝﾀ
";
CM_ SG_ 1657 TPM679_1_6 "予約:通信継続要求ﾌﾗｸﾞ(拡張)
";
CM_ SG_ 1657 TPM679_0_0_CHECK_SUM "ﾁｪｯｸｻﾑ
";
CM_ SG_ 1634 ABG662_4_0_CDS_BEV "衝突検知信号（BEV用）
";
CM_ SG_ 1634 ABG662_1_0_MSG_COUNTER "ﾒｯｾｰｼﾞｶｳﾝﾀ
";
CM_ SG_ 1634 ABG662_0_0_CHECK_SUM "ﾁｪｯｸｻﾑ
";
CM_ SG_ 827 ABG33B_4_0_PASSENGER_BELT_INFO "助手席シートベルト情報
";
CM_ SG_ 827 ABG33B_4_2_PASSENGER_DETECT_INFO "助手席乗員判定情報
";
CM_ SG_ 827 ABG33B_3_0_PPS_STATUS_FAIL_IGN "歩行者保護A/B故障有無状態（点火）
";
CM_ SG_ 827 ABG33B_3_1_PPS_STATUS_FAIL_DEV "歩行者保護A/B故障有無状態（ﾃﾞﾊﾞｲｽ）
";
CM_ SG_ 827 ABG33B_3_2_PPS_STATUS_FAIL_SSR "歩行者保護A/B故障有無状態（ｾﾝｻ）
";
CM_ SG_ 827 ABG33B_3_3_PPS_STATUS_FAIL_ECU "歩行者保護A/B故障有無状態（ECU）
";
CM_ SG_ 827 ABG33B_2_0_IND_WARN_PPA "歩行者ｴｱﾊﾞｯｸﾞｳｫｰﾆﾝｸﾞﾗﾝﾌﾟ点灯・点滅要求
";
CM_ SG_ 827 ABG33B_2_2_DETECT_CRUSH "衝突検知信号(歩行者)
";
CM_ SG_ 827 ABG33B_1_0_MSG_COUNTER "ﾒｯｾｰｼﾞｶｳﾝﾀ
";
CM_ SG_ 827 ABG33B_1_4_FLG_PEDESTRIAN_AIRBAG "歩行者保護A/B有無ﾌﾗｸﾞ
";
CM_ SG_ 827 ABG33B_1_6 "予約:通信継続要求ﾌﾗｸﾞ(拡張)
";
CM_ SG_ 827 ABG33B_0_0_CHECK_SUM "ﾁｪｯｸｻﾑ
";
CM_ SG_ 826 ABG33A_7_0_VELOCITYCHANGE_VX_MAX "衝突時ΔVx MAX
";
CM_ SG_ 826 ABG33A_6_0_VELOCITYCHANGE_VX_MAX "衝突時ΔVx MAX
";
CM_ SG_ 826 ABG33A_5_0_P_SIDE_ABG_DEPLOY "P席ｻｲﾄﾞｴｱﾊﾞｯｸﾞ展開判定
";
CM_ SG_ 826 ABG33A_5_1_D_SIDE_ABG_DEPLOY "D席ｻｲﾄﾞｴｱﾊﾞｯｸﾞ展開判定
";
CM_ SG_ 826 ABG33A_5_2_FRONT_FAR_ABG_DEPLOY "前席ﾌｧｰｻｲﾄﾞｴｱﾊﾞｯｸﾞ展開判定
";
CM_ SG_ 826 ABG33A_5_3_REAR_FAR_ABG_DEPLOY "後席ﾌｧｰｻｲﾄﾞｴｱﾊﾞｯｸﾞ展開判定
";
CM_ SG_ 826 ABG33A_5_4_REAR_RH_ABG_DEPLOY "後席ｻｲﾄﾞｴｱﾊﾞｯｸﾞRH展開判定
";
CM_ SG_ 826 ABG33A_5_5_REAR_LH_ABG_DEPLOY "後席ｻｲﾄﾞｴｱﾊﾞｯｸﾞLH展開判定
";
CM_ SG_ 826 ABG33A_5_6_P_CURTAIN_ABG_DEPLOY "P席ｶｰﾃﾝｴｱﾊﾞｯｸﾞ展開判定
";
CM_ SG_ 826 ABG33A_5_7_D_CURTAIN_ABG_DEPLOY "D席ｶｰﾃﾝｴｱﾊﾞｯｸﾞ展開判定
";
CM_ SG_ 826 ABG33A_4_0_D_FRONT_ABG_DEPLOY "D席ﾌﾛﾝﾄｴｱﾊﾞｯｸﾞ展開判定
";
CM_ SG_ 826 ABG33A_4_1_P_FRONT_ABG_DEPLOY "P席ﾌﾛﾝﾄｴｱﾊﾞｯｸﾞ展開判定
";
CM_ SG_ 826 ABG33A_4_2_P_ABG_DEPLOY "P席ｼｰﾄｸｯｼｮﾝｴｱﾊﾞｯｸﾞ展開判定
";
CM_ SG_ 826 ABG33A_4_3_D_ABG_DEPLOY "D席ｼｰﾄｸｯｼｮﾝｴｱﾊﾞｯｸﾞ展開判定
";
CM_ SG_ 826 ABG33A_4_4_P_BELT_PRETENTION "P席ｼｰﾄﾍﾞﾙﾄﾌﾟﾘﾃﾝｼｮﾅ展開判定
";
CM_ SG_ 826 ABG33A_4_5_D_BELT_PRETENTION "D席ｼｰﾄﾍﾞﾙﾄﾌﾟﾘﾃﾝｼｮﾅ展開判定
";
CM_ SG_ 826 ABG33A_4_6_D_KNEE_ABG_DEPLOY "D席ﾆｰｴｱﾊﾞｯｸﾞ展開判定
";
CM_ SG_ 826 ABG33A_4_7_P_KNEE_ABG_DEPLOY "P席ﾆｰｴｱﾊﾞｯｸﾞ展開判定
";
CM_ SG_ 826 ABG33A_3_0_BELT_WRNING_PASS "P席ﾍﾞﾙﾄ状態(ｳｫｰﾆﾝｸﾞ出力用)
";
CM_ SG_ 826 ABG33A_3_2_BUCKLESW_DRVR "D席ﾊﾞｯｸﾙｽｲｯﾁ
";
CM_ SG_ 826 ABG33A_3_4_OCCUPATION_PASS "P席乗員有無信号
";
CM_ SG_ 826 ABG33A_3_6_IND_ACT_ABG_PASS "P席A/B作動ﾓｰﾄﾞｲﾝｼﾞｹｰﾀ
";
CM_ SG_ 826 ABG33A_2_0_IND_WARN_ABG "ｴｱﾊﾞｯｸﾞｳｫｰﾆﾝｸﾞﾗﾝﾌﾟ点灯・点滅要求
";
CM_ SG_ 826 ABG33A_2_2_DETECT_CRUSH "衝突検知信号
";
CM_ SG_ 826 ABG33A_2_5_STATUS_CRUSH_ECALL "衝突形態
";
CM_ SG_ 826 ABG33A_1_0_MSG_COUNTER "ﾒｯｾｰｼﾞｶｳﾝﾀ
";
CM_ SG_ 826 ABG33A_1_4_FLG_ABGIND_CTRL "P席 A/B ON/OFFｲﾝｼﾞｹｰﾀ点灯要求有無ﾌﾗｸﾞ
";
CM_ SG_ 826 ABG33A_1_5_REQ_COMM_CONT "通信継続要求
";
CM_ SG_ 826 ABG33A_1_6_COLLISION_COUNTER "衝突判定回数
";
CM_ SG_ 826 ABG33A_0_0_CHECK_SUM "ﾁｪｯｸｻﾑ
";
CM_ SG_ 1351 ABG547_7_0_NETWORK_STATUS "ﾈｯﾄﾜｰｸｽﾃｰﾀｽ
";
CM_ SG_ 1315 ABG523_1_4_ActiveWakeUpBit "Active Wakeup ﾌﾗｸﾞ
";
CM_ SG_ 1315 ABG523_0_0_SourceNodeID "送信元ID
";
CM_ SG_ 962 DMS3C2_27_2_EYE_CLOSE_TIME "連続閉眼時間
";
CM_ SG_ 962 DMS3C2_26_0_FACIAL_EXPRESSION "表情認識
";
CM_ SG_ 962 DMS3C2_26_3_DIST_TIME "脇見継続時間
";
CM_ SG_ 962 DMS3C2_24_4_GAZE_CONF_RIGHT "視線算出(右目)信頼度
";
CM_ SG_ 962 DMS3C2_23_3_GAZE_PITCH_RIGHT "視線向き(右目)Pitch角度
";
CM_ SG_ 962 DMS3C2_22_2_GAZE_YAW_RIGHT "視線向き(右目)Yaw角度
";
CM_ SG_ 962 DMS3C2_21_3_GAZE_CONF_LEFT "視線算出(左目)信頼度
";
CM_ SG_ 962 DMS3C2_20_2_GAZE_PITCH_LEFT "視線向き(左目)Pitch角度
";
CM_ SG_ 962 DMS3C2_19_1_GAZE_YAW_LEFT "視線向き(左目)Yaw角度
";
CM_ SG_ 962 DMS3C2_17_6_DRIVER_HEAD_POS_Z "頭位置Z座標
";
CM_ SG_ 962 DMS3C2_16_3_DRIVER_HEAD_POS_Y "頭位置Y座標
";
CM_ SG_ 962 DMS3C2_15_0_DRIVER_HEAD_POS_X "頭位置X座標
";
CM_ SG_ 962 DMS3C2_13_4_VTX_RIGHT_BTM_Y "顔検出枠のxy座標値(矩形の右下(y))
";
CM_ SG_ 962 DMS3C2_12_0_VTX_RIGHT_BTM_X "顔検出枠のxy座標値(矩形の右下(x))
";
CM_ SG_ 962 DMS3C2_10_4_VTX_LEFT_UP_Y "顔検出枠のxy座標値(矩形の左上(y))
";
CM_ SG_ 962 DMS3C2_9_0_VTX_LEFT_UP_X "顔検出枠のxy座標値(矩形の左上(x))
";
CM_ SG_ 962 DMS3C2_8_3_FACE_CONF_FLAG "顔検出フラグ
";
CM_ SG_ 962 DMS3C2_8_4_FRAME_NUM "フレーム番号
";
CM_ SG_ 962 DMS3C2_7_3_EYE_CLS_CONF_FLAG "開眼度信頼度フラグ
";
CM_ SG_ 962 DMS3C2_7_4_SLEEPNESS_LEVEL "眠気値
";
CM_ SG_ 962 DMS3C2_6_3_FACE_AGL_CONF_FLAG "顔向き信頼度フラグ
";
CM_ SG_ 962 DMS3C2_6_4_EYE_CLOSE_LEVEL "開眼度
";
CM_ SG_ 962 DMS3C2_5_2_FACE_ANGLE_ROLL "顔向き角度検出値(Roll)
";
CM_ SG_ 962 DMS3C2_4_1_FACE_ANGLE_PITCH "顔向き角度検出値(Pitch)
";
CM_ SG_ 962 DMS3C2_3_0_FACE_ANGLE_YAW "顔向き角度検出値(Yaw)
";
CM_ SG_ 962 DMS3C2_2_0_E2E_COUNTER "E2Eカウンタ
";
CM_ SG_ 962 DMS3C2_0_0_E2E_CRC "CRC
";
CM_ SG_ 961 DMS3C1_7_4_SHORT_DIST_DETECT "ショートディストラクション判定フラグ
";
CM_ SG_ 961 DMS3C1_7_5_PRESENCE_DETECT "後席乗員検知情報
";
CM_ SG_ 961 DMS3C1_7_6_RADER_EQUIP "ミリ波搭載情報
";
CM_ SG_ 961 DMS3C1_7_7_LOSING_POSTURE_DETECT "異常姿勢検知フラグ
";
CM_ SG_ 961 DMS3C1_6_0_ID_RECOG_CANCEL "ID認識中断フラグ
";
CM_ SG_ 961 DMS3C1_6_1_ID_ENABLE_FLAG "ID有効フラグ
";
CM_ SG_ 961 DMS3C1_6_2_PERMIT_AVN_FLAG "AVN操作許可フラグ
";
CM_ SG_ 961 DMS3C1_6_4_DISTRACTION_STATUS "脇見状態フラグ
";
CM_ SG_ 961 DMS3C1_6_5_DROWSINESS_STATUS "閉眼状態フラグ
";
CM_ SG_ 961 DMS3C1_6_6_DROWSINESS_LV2_STATUS "強い眠気状態フラグ
";
CM_ SG_ 961 DMS3C1_6_7_NOT_DETECTED_STATUS "顔未検出状態フラグ
";
CM_ SG_ 961 DMS3C1_5_0_ID_LIST "ID登録リスト
";
CM_ SG_ 961 DMS3C1_5_5_ID_EDIT_FLAG "ID設定フラグ
";
CM_ SG_ 961 DMS3C1_4_0_DMS_IND_REQ_FLAG "インジゲータ点灯フラグ
";
CM_ SG_ 961 DMS3C1_4_3_DMS_RECOG_STATUS "個人認識ON/OFF状態
";
CM_ SG_ 961 DMS3C1_4_4_DRIVER_STATUS "D席乗員状態
";
CM_ SG_ 961 DMS3C1_3_0_DRIVER_REGIST_ID "個人ID
";
CM_ SG_ 961 DMS3C1_3_4_CUST_EDIT_FLAG "カスタマイズ操作フラグ
";
CM_ SG_ 961 DMS3C1_3_6_ID_RECOG_FLAG "ID識別フラグ
";
CM_ SG_ 961 DMS3C1_2_0_LEVEL_DROWS "居眠り深度
";
CM_ SG_ 961 DMS3C1_2_3_DROWS_DETECT_FLAG "居眠り判定フラグ
";
CM_ SG_ 961 DMS3C1_2_7_DIST_DETECT_FLAG "脇見判定フラグ
";
CM_ SG_ 961 DMS3C1_1_0_MSG_COUNTER "メッセージカウンタ
";
CM_ SG_ 961 DMS3C1_1_4_WAKE_UP_FRAME "ｳｪｲｸｱｯﾌﾟﾌﾚｰﾑ識別ﾌﾗｸﾞ
";
CM_ SG_ 961 DMS3C1_1_5_REQ_COMM_CONT "通信継続要求ﾌﾗｸﾞ
";
CM_ SG_ 961 DMS3C1_1_7_EYE_DIST_FLAG "早鳴りフラグ
";
CM_ SG_ 961 DMS3C1_0_0_CHKSUM "ﾁｪｯｸｻﾑ
";
CM_ SG_ 1290 DMS50A_1_4_ActiveWakeUpBit "Active Wakeup ﾌﾗｸﾞ
";
CM_ SG_ 1290 DMS50A_0_0_SourceNodeID "送信元ID
";
CM_ SG_ 1651 ACN673_7_2_REQ_STRG_H "ステアリングヒータ動作要求
";
CM_ SG_ 1651 ACN673_7_1_SEAT_H_L_AUTOIND "シートヒータ空調（左側） AUTOIND点灯
";
CM_ SG_ 1651 ACN673_7_0_SEAT_H_R_AUTOIND "シートヒータ空調（右側） AUTOIND点灯
";
CM_ SG_ 1651 ACN673_6_0_RR_FAN_SYMBOL "RR FAN SYMBOL
";
CM_ SG_ 1651 ACN673_6_2_SEAT_H_R "シートヒータ空調（右側）
";
CM_ SG_ 1651 ACN673_6_5_SEAT_H_L "シートヒータ空調（左側）
";
CM_ SG_ 1651 ACN673_5_0_DR_ONLY "一席集中状態
";
CM_ SG_ 1651 ACN673_5_2_STRG_H "ステアリングヒータ状態
";
CM_ SG_ 1651 ACN673_5_4_AC_SI_DS_SET "SI-DS空調設定
";
CM_ SG_ 1651 ACN673_5_6_STRG_H_AUTOIND "ステアリングヒータ AUTO IND点灯
";
CM_ SG_ 1651 ACN673_5_7_AC_SI_DS_FLG "SI-DS空調有無フラグ
";
CM_ SG_ 1651 ACN673_4_0_SEAT_HEATER_DR "Dr席　シートヒーター作動状態
";
CM_ SG_ 1651 ACN673_4_2_SEAT_HEATER_PA "Pa席　シートヒーター作動状態
";
CM_ SG_ 1651 ACN673_4_4_SEAT_HEATER "シートヒーター有無
";
CM_ SG_ 1651 ACN673_4_5_TEMP_SET_TYPE "設定温度タイプ
";
CM_ SG_ 1651 ACN673_4_7_VENTI_SEAT_EX_HI "シート空調EX-HI
";
CM_ SG_ 1651 ACN673_1_0_MSG_COUNTER "ﾒｯｾｰｼﾞｶｳﾝﾀ
";
CM_ SG_ 1651 ACN673_1_6_SYNC_RR "SYNC_RR
";
CM_ SG_ 1651 ACN673_1_7_RR_LOCK "RR_LOCK
";
CM_ SG_ 1651 ACN673_0_0_CHECK_SUM "ﾁｪｯｸｻﾑ
";
CM_ SG_ 1650 ACN672_7_0_INFO_AUTO3MODE "AUTO3モード
";
CM_ SG_ 1650 ACN672_7_2_INFO_REAR_TEMP "Rr設定温度
";
CM_ SG_ 1650 ACN672_6_0_DEF "DEF
";
CM_ SG_ 1650 ACN672_6_1_FAN_SYMBOL "FAN SYMBOL
";
CM_ SG_ 1650 ACN672_6_2_REAR_MODE "Rr吹き出し口ﾓｰﾄﾞ
";
CM_ SG_ 1650 ACN672_6_4_UNIT_TEMP "温度仕様
";
CM_ SG_ 1650 ACN672_6_5_SPEC_AC_UNIT "空調仕様
";
CM_ SG_ 1650 ACN672_6_7_REAR_AC "ﾘｱ空調有無
";
CM_ SG_ 1650 ACN672_5_0_AC_VR_MODE "ｴｱｺﾝ音声認識ﾓｰﾄﾞ
";
CM_ SG_ 1650 ACN672_5_2_INFO_TEMP_PASS "Pa設定温度
";
CM_ SG_ 1650 ACN672_4_0_AC_INTERRUPT_DISPLAY "ｴｱｺﾝ割り込み画面表示
";
CM_ SG_ 1650 ACN672_4_1_AC_VR_ACTION "ｴｱｺﾝ音声認識ｺﾏﾝﾄﾞ実行
";
CM_ SG_ 1650 ACN672_4_2_INFO_TEMP_DRVR "Dr設定温度
";
CM_ SG_ 1650 ACN672_3_0_MAX_AC "MAX A/C
";
CM_ SG_ 1650 ACN672_3_1_INFO_SYNC_OR_SING "SYNC
";
CM_ SG_ 1650 ACN672_3_2_INFO_FULL_OR_AUTO "FULL及びAUTO
";
CM_ SG_ 1650 ACN672_3_4_INFO_AC_ON "A/C
";
CM_ SG_ 1650 ACN672_3_5_INFO_RDEF "Rrﾃﾞﾌ
";
CM_ SG_ 1650 ACN672_3_6_INFO_CIRCULATION "内外気
";
CM_ SG_ 1650 ACN672_2_0_INFO_MODE_VENT "吹き出し口ﾓｰﾄﾞ
";
CM_ SG_ 1650 ACN672_2_4_INFO_FANONLY "送風モード
";
CM_ SG_ 1650 ACN672_2_5_INFO_LEV_BLOWERFAN "ﾌｧﾝ段数
";
CM_ SG_ 1650 ACN672_1_0_MSG_COUNTER "ﾒｯｾｰｼﾞｶｳﾝﾀ
";
CM_ SG_ 1650 ACN672_1_4_LVL_BLOWERFAN_RR "Rrﾌｧﾝ段数
";
CM_ SG_ 1650 ACN672_1_7_REAR_AUTO "Rr AUTO
";
CM_ SG_ 1650 ACN672_0_0_CHECK_SUM "ﾁｪｯｸｻﾑ
";
CM_ SG_ 722 ACN2D2_7_0_PD_PRESSURE "A/C PD圧力値
";
CM_ SG_ 722 ACN2D2_6_0_TRQ_COMP_ESTM "ｺﾝﾌﾟﾚｯｻﾄﾙｸ推定値
";
CM_ SG_ 722 ACN2D2_5_0_REQ_ENG_RPM "ｴｱｺﾝ要求ｴﾝｼﾞﾝ回転数
";
CM_ SG_ 722 ACN2D2_5_3_REQ_IDLE_COMP_RPM "ｱｲﾄﾞﾙ時要求ｺﾝﾌﾟﾚｯｻ回転数
";
CM_ SG_ 722 ACN2D2_4_0_LVL_PTC "PTC段数 電気負荷情報
";
CM_ SG_ 722 ACN2D2_4_2_MARGIN_OF_AC "ｴｱｺﾝ余裕度
";
CM_ SG_ 722 ACN2D2_4_5_LVL_BLOWER_FAN "ﾌﾞﾛｱﾌｧﾝSW（電気負荷情報）
";
CM_ SG_ 722 ACN2D2_3_0_PERMIT_ISS "ISS作動許可
";
CM_ SG_ 722 ACN2D2_3_2_TRQ_PAT_COMP_ESTM "A/C見込みﾄﾙｸﾊﾟﾀｰﾝ
";
CM_ SG_ 722 ACN2D2_3_5_IND_ROOM_TEMP "室温表示
";
CM_ SG_ 722 ACN2D2_2_0_FAIL_TRQ_COMP_ESTM "ｺﾝﾌﾟﾚｯｻﾄﾙｸ推定値ﾌｪｰﾙ
";
CM_ SG_ 722 ACN2D2_2_1_FAIL_AC "A/Cﾌｪｰﾙ
";
CM_ SG_ 722 ACN2D2_2_2_REQ_INHIBIT_LOCKUP "L/U禁止要求
";
CM_ SG_ 722 ACN2D2_2_3_AC_ON "A/C信号
";
CM_ SG_ 722 ACN2D2_2_4_RDEFOGSW "RﾃﾞﾌｫｯｶﾞSW
";
CM_ SG_ 722 ACN2D2_2_5_WARM_UP "ｳｫｰﾑｱｯﾌﾟ信号
";
CM_ SG_ 722 ACN2D2_2_6_AC_AUTO_MANUAL "ｵｰﾄｴｱｺﾝ・ﾏﾆｭｱﾙｴｱｺﾝ判別信号
";
CM_ SG_ 722 ACN2D2_2_7_COMP_TYPE "ｺﾝﾌﾟﾚｯｻﾀｲﾌﾟ
";
CM_ SG_ 722 ACN2D2_1_0_MSG_COUNTER "ﾒｯｾｰｼﾞｶｳﾝﾀ
";
CM_ SG_ 722 ACN2D2_1_4 "ｳｪｲｸｱｯﾌﾟﾌﾚｰﾑ識別ﾌﾗｸﾞ
";
CM_ SG_ 722 ACN2D2_1_5 "通信継続要求ﾌﾗｸﾞ
";
CM_ SG_ 722 ACN2D2_1_6 "予約:通信継続要求ﾌﾗｸﾞ(拡張)
";
CM_ SG_ 722 ACN2D2_1_7_WARM_POWER_CONT "暖房促進制御信号
";
CM_ SG_ 722 ACN2D2_0_0_CHECK_SUM "ﾁｪｯｸｻﾑ
";
CM_ SG_ 1667 ACN683_3_2_AC_DEFALTSET "空調デフォルト設定コマンドフラグ
";
CM_ SG_ 1667 ACN683_3_0_RCC_ACN_RES "テレマリモ空作動結果通知フラグ
";
CM_ SG_ 1667 ACN683_2_7_JUDGE_FANONLY "送風モード作動可否
";
CM_ SG_ 1667 ACN683_2_6_CSTM_LINK_SEAT_R "右側シートヒータ空調AUTO連動カスタマイズ
";
CM_ SG_ 1667 ACN683_2_5_CSTM_LINK_SEAT_L "左側 シートヒータ空調
AUTO連動カスタマイズ
";
CM_ SG_ 1667 ACN683_2_4_CSTM_STRG_H_LINK "ステアリングヒータ
AUTO連動カスタマイズ
";
CM_ SG_ 1667 ACN683_2_2_CSTM_TEMP_SVS_R "右側 シートベンチレーション温度 
カスタマイズ
";
CM_ SG_ 1667 ACN683_2_0_CSTM_TEMP_SVS_L "左側 シートベンチレーション温度 
カスタマイズ
";
CM_ SG_ 1667 ACN683_1_6_CSTM_TEMP_SEAT_H_R "右側 シートヒータ温度 
カスタマイズ
";
CM_ SG_ 1667 ACN683_1_4_CSTM_TEMP_SEAT_H_L "左側 シートヒータ温度
カスタマイズ
";
CM_ SG_ 1667 ACN683_1_0_MSG_COUNTER "メッセージカウンタ
";
CM_ SG_ 1667 ACN683_0_0_CHECK_SUM "チェックサム
";
CM_ SG_ 957 ACN3BD_4_0_STATE_HT_ACT "HT昇温デバイス作動状態
";
CM_ SG_ 957 ACN3BD_3_3_STATE_HT_CIR "HT回路状態
";
CM_ SG_ 957 ACN3BD_3_0_STATE_HT_CIR_SW "HT回路切替状態
";
CM_ SG_ 957 ACN3BD_2_0_POS_4WV "HT4方弁実開度
";
CM_ SG_ 957 ACN3BD_1_4_ERR_HTDEV "HT昇温デバイス異常状態
";
CM_ SG_ 957 ACN3BD_1_0_MSG_COUNTER "メッセージカウンタ
";
CM_ SG_ 957 ACN3BD_0_0_CHECK_SUM "チェックサム
";
CM_ SG_ 954 ACN3BA_6_0_ACNDEVICE_FIN "空調デバイス終了処理完了フラグ
";
CM_ SG_ 954 ACN3BA_5_3_VOLT_PRT_10WV "LT10方弁電圧保護情報
";
CM_ SG_ 954 ACN3BA_5_1_TEMP_PRT_10WV "LT10方弁温度保護情報
";
CM_ SG_ 954 ACN3BA_4_0_CONT_CHK_10WV "LT10方弁指示確認
";
CM_ SG_ 954 ACN3BA_3_5_V_ERR_10WV "LT10方弁本体異常情報
";
CM_ SG_ 954 ACN3BA_3_3_CR_ERR_10WV "LT10方弁回路異常情報
";
CM_ SG_ 954 ACN3BA_3_1_ERR_CL "チラー吸熱異常状態
";
CM_ SG_ 954 ACN3BA_2_0_POS_10WV "LT10方弁実開度
";
CM_ SG_ 954 ACN3BA_1_6_INI_10WV "LT10方弁イニシャライズ状態
";
CM_ SG_ 954 ACN3BA_1_4_INFO_10WV "LT10方弁情報(LIN)
";
CM_ SG_ 954 ACN3BA_1_0_MSG_COUNTER "メッセージカウンタ
";
CM_ SG_ 954 ACN3BA_0_0_CHECK_SUM "チェックサム
";
CM_ SG_ 1659 ACN67B_6_0_STATE_INW "注排水状態
";
CM_ SG_ 1659 ACN67B_5_2_JUDGE_OIL_SALVAGE "オイル回収必要通知
";
CM_ SG_ 1659 ACN67B_5_0_OIL_SALVAGE_READY "オイル回収実施準備完了フラグ
";
CM_ SG_ 1659 ACN67B_4_3_STATE_ACLOAD "空調負荷状態
";
CM_ SG_ 1659 ACN67B_4_2_REQ_LT_DEF "LTラジ除霜要求
";
CM_ SG_ 1659 ACN67B_4_1_REQ_HT_RAD "HTラジ放熱要求
";
CM_ SG_ 1659 ACN67B_4_0_STATE_BATHP "電池吸熱可否冷媒状態
";
CM_ SG_ 1659 ACN67B_3_4_REQ_ACCYC "空調要求
";
CM_ SG_ 1659 ACN67B_3_3_JUDGE_AMBHP "外気H/P可否状態
";
CM_ SG_ 1659 ACN67B_3_1_RL_LTO "水温センサ信頼性情報(LTラジ出口)
";
CM_ SG_ 1659 ACN67B_2_0_TW_LTO "LTラジ出口水温
";
CM_ SG_ 1659 ACN67B_1_7_JUDGE_LTHP "LT廃熱HP可否状態
";
CM_ SG_ 1659 ACN67B_1_6_HTS_BAT_COMB "熱源不足状態通知(昇温空調併用)
";
CM_ SG_ 1659 ACN67B_1_5_HTS_AC_ALONE "熱源不足状態通知(空調単独)
";
CM_ SG_ 1659 ACN67B_1_4_PERMIT_TL "サーマルループ許可状態
";
CM_ SG_ 1659 ACN67B_1_0_MSG_COUNTER "メッセージカウンタ
";
CM_ SG_ 1659 ACN67B_0_0_CHECK_SUM "チェックサム
";
CM_ SG_ 1656 ACN678_6_0_COMP_W "コンプレッサ仕事量
";
CM_ SG_ 1656 ACN678_4_0_REQ_HC_H "ヒータコア要求放熱量
";
CM_ SG_ 1656 ACN678_2_0_REQ_EVA_H "エバポレータ要求吸熱量
";
CM_ SG_ 1656 ACN678_1_0_MSG_COUNTER "メッセージカウンタ
";
CM_ SG_ 1656 ACN678_0_0_CHECK_SUM "チェックサム
";
CM_ SG_ 949 ACN3B5_7_4_BWP_STATE_FS "バッテリW/P FS状態
";
CM_ SG_ 949 ACN3B5_5_6_HTWP_R "空調(HT)W/P回転数
";
CM_ SG_ 949 ACN3B5_5_4_RL_DE_CLO "水温センサ信頼性情報
(チラー出口_偏差異常)
";
CM_ SG_ 949 ACN3B5_5_1_RL_WC_CLO "水温センサ信頼性情報
(チラー出口_結線異常)
";
CM_ SG_ 949 ACN3B5_4_0_TW_CLO "チラー出口水温
";
CM_ SG_ 949 ACN3B5_3_6_STATE_TW_CL "特殊処理制御実施状態
";
CM_ SG_ 949 ACN3B5_2_0_BWP_R "バッテリW/P回転数
";
CM_ SG_ 949 ACN3B5_1_7_STATE_HTWP "HT W/P作動状態
";
CM_ SG_ 949 ACN3B5_1_4_WC_ERR_BWP "W/P結線異常情報
(バッテリー用W/P)
";
CM_ SG_ 949 ACN3B5_1_0_MSG_COUNTER "メッセージカウンタ
";
CM_ SG_ 949 ACN3B5_0_0_CHECK_SUM "チェックサム
";
BA_DEF_ SG_  "Fhi_SignalComment" STRING ;
BA_DEF_ SG_  "GenSigInactiveValue" INT 0 10000;
BA_DEF_ SG_  "GenSigStartValue" FLOAT 0 100000000000;
BA_DEF_ SG_  "GenSigSendType" ENUM  "Cyclic","OnWrite","OnWriteWithRepetition","OnChange","OnChangeWithRepetition","IfActive","IfActiveWithRepetition","NoSigSendType";
BA_DEF_ BO_  "MsgRoutingId" STRING ;
BA_DEF_ BO_  "DiagResponse" ENUM  "No","Yes";
BA_DEF_ BO_  "DiagRequest" ENUM  "No","Yes";
BA_DEF_ BO_  "DiagState" ENUM  "No","Yes";
BA_DEF_ BO_  "GenMsgILSupport" ENUM  "No","Yes";
BA_DEF_ BO_  "GenMsgNrOfRepetition" INT 0 999999;
BA_DEF_ BO_  "GenMsgDelayTime" INT 0 1000;
BA_DEF_ BO_  "GenMsgCycleTimeFast" INT 0 10000;
BA_DEF_ BO_  "GenMsgCycleTime" INT 0 10000;
BA_DEF_ BO_  "GenMsgSendType" ENUM  "Cyclic","NotUsed","NotUsed","NotUsed","NotUsed","Cyclic","NotUsed","IfActive","NoMsgSendType";
BA_DEF_ BO_  "CANFD_BRS" ENUM  "0","1";
BA_DEF_ BO_  "VFrameFormat" ENUM  "StandardCAN","ExtendedCAN","reserved","reserved","reserved","reserved","reserved","reserved","reserved","reserved","reserved","reserved","reserved","reserved","StandardCAN_FD","ExtendedCAN_FD";
BA_DEF_DEF_  "Fhi_SignalComment" "";
BA_DEF_DEF_  "GenSigInactiveValue" 0;
BA_DEF_DEF_  "GenSigStartValue" 0;
BA_DEF_DEF_  "GenSigSendType" "NoSigSendType";
BA_DEF_DEF_  "MsgRoutingId" "";
BA_DEF_DEF_  "DiagResponse" "No";
BA_DEF_DEF_  "DiagRequest" "No";
BA_DEF_DEF_  "DiagState" "No";
BA_DEF_DEF_  "GenMsgILSupport" "Yes";
BA_DEF_DEF_  "GenMsgNrOfRepetition" 0;
BA_DEF_DEF_  "GenMsgDelayTime" 0;
BA_DEF_DEF_  "GenMsgCycleTimeFast" 0;
BA_DEF_DEF_  "GenMsgCycleTime" 0;
BA_DEF_DEF_  "GenMsgSendType" "Cyclic";
BA_DEF_DEF_  "CANFD_BRS" "1";
BA_DEF_DEF_  "VFrameFormat" "StandardCAN";
BA_ "GenMsgSendType" BO_ 2564481198 8;
BA_ "GenMsgNrOfRepetition" BO_ 2564481198 1;
BA_ "DiagResponse" BO_ 2564481198 1;
BA_ "GenMsgILSupport" BO_ 2564481198 0;
BA_ "MsgRoutingId" BO_ 2564481198 "186 ";
BA_ "VFrameFormat" BO_ 2564481198 15;
BA_ "GenMsgSendType" BO_ 2564468448 8;
BA_ "GenMsgNrOfRepetition" BO_ 2564468448 1;
BA_ "DiagRequest" BO_ 2564468448 1;
BA_ "GenMsgILSupport" BO_ 2564468448 0;
BA_ "MsgRoutingId" BO_ 2564468448 "185 ";
BA_ "VFrameFormat" BO_ 2564468448 15;
BA_ "GenMsgSendType" BO_ 2564481036 8;
BA_ "GenMsgNrOfRepetition" BO_ 2564481036 1;
BA_ "DiagResponse" BO_ 2564481036 1;
BA_ "GenMsgILSupport" BO_ 2564481036 0;
BA_ "MsgRoutingId" BO_ 2564481036 "182 ";
BA_ "VFrameFormat" BO_ 2564481036 15;
BA_ "GenMsgSendType" BO_ 2564426976 8;
BA_ "GenMsgNrOfRepetition" BO_ 2564426976 1;
BA_ "DiagRequest" BO_ 2564426976 1;
BA_ "GenMsgILSupport" BO_ 2564426976 0;
BA_ "MsgRoutingId" BO_ 2564426976 "181 ";
BA_ "VFrameFormat" BO_ 2564426976 15;
BA_ "GenMsgSendType" BO_ 2564481153 8;
BA_ "GenMsgNrOfRepetition" BO_ 2564481153 1;
BA_ "DiagResponse" BO_ 2564481153 1;
BA_ "GenMsgILSupport" BO_ 2564481153 0;
BA_ "MsgRoutingId" BO_ 2564481153 "176 ";
BA_ "VFrameFormat" BO_ 2564481153 15;
BA_ "GenMsgSendType" BO_ 2564456928 8;
BA_ "GenMsgNrOfRepetition" BO_ 2564456928 1;
BA_ "DiagRequest" BO_ 2564456928 1;
BA_ "GenMsgILSupport" BO_ 2564456928 0;
BA_ "MsgRoutingId" BO_ 2564456928 "175 ";
BA_ "VFrameFormat" BO_ 2564456928 15;
BA_ "GenMsgSendType" BO_ 2564481154 8;
BA_ "GenMsgNrOfRepetition" BO_ 2564481154 1;
BA_ "DiagResponse" BO_ 2564481154 1;
BA_ "GenMsgILSupport" BO_ 2564481154 0;
BA_ "MsgRoutingId" BO_ 2564481154 "172 ";
BA_ "VFrameFormat" BO_ 2564481154 15;
BA_ "GenMsgSendType" BO_ 2564457184 8;
BA_ "GenMsgNrOfRepetition" BO_ 2564457184 1;
BA_ "DiagRequest" BO_ 2564457184 1;
BA_ "GenMsgILSupport" BO_ 2564457184 0;
BA_ "MsgRoutingId" BO_ 2564457184 "171 ";
BA_ "VFrameFormat" BO_ 2564457184 15;
BA_ "GenMsgSendType" BO_ 2564481155 8;
BA_ "GenMsgNrOfRepetition" BO_ 2564481155 1;
BA_ "DiagResponse" BO_ 2564481155 1;
BA_ "GenMsgILSupport" BO_ 2564481155 0;
BA_ "MsgRoutingId" BO_ 2564481155 "170 ";
BA_ "VFrameFormat" BO_ 2564481155 15;
BA_ "GenMsgSendType" BO_ 2564457440 8;
BA_ "GenMsgNrOfRepetition" BO_ 2564457440 1;
BA_ "DiagRequest" BO_ 2564457440 1;
BA_ "GenMsgILSupport" BO_ 2564457440 0;
BA_ "MsgRoutingId" BO_ 2564457440 "169 ";
BA_ "VFrameFormat" BO_ 2564457440 15;
BA_ "VFrameFormat" BO_ 2564481107 1;
BA_ "GenMsgSendType" BO_ 2564481107 8;
BA_ "GenMsgNrOfRepetition" BO_ 2564481107 1;
BA_ "DiagResponse" BO_ 2564481107 1;
BA_ "GenMsgILSupport" BO_ 2564481107 0;
BA_ "MsgRoutingId" BO_ 2564481107 "146 ";
BA_ "VFrameFormat" BO_ 2564445152 1;
BA_ "GenMsgSendType" BO_ 2564445152 8;
BA_ "GenMsgNrOfRepetition" BO_ 2564445152 1;
BA_ "DiagRequest" BO_ 2564445152 1;
BA_ "GenMsgILSupport" BO_ 2564445152 0;
BA_ "MsgRoutingId" BO_ 2564445152 "145 ";
BA_ "GenMsgSendType" BO_ 2564481101 8;
BA_ "GenMsgNrOfRepetition" BO_ 2564481101 1;
BA_ "DiagResponse" BO_ 2564481101 1;
BA_ "GenMsgILSupport" BO_ 2564481101 0;
BA_ "MsgRoutingId" BO_ 2564481101 "135 ";
BA_ "VFrameFormat" BO_ 2564481101 15;
BA_ "GenMsgSendType" BO_ 2564443616 8;
BA_ "GenMsgNrOfRepetition" BO_ 2564443616 1;
BA_ "DiagRequest" BO_ 2564443616 1;
BA_ "GenMsgILSupport" BO_ 2564443616 0;
BA_ "MsgRoutingId" BO_ 2564443616 "134 ";
BA_ "VFrameFormat" BO_ 2564443616 15;
BA_ "VFrameFormat" BO_ 2564481043 1;
BA_ "GenMsgSendType" BO_ 2564481043 8;
BA_ "GenMsgNrOfRepetition" BO_ 2564481043 1;
BA_ "DiagResponse" BO_ 2564481043 1;
BA_ "GenMsgILSupport" BO_ 2564481043 0;
BA_ "MsgRoutingId" BO_ 2564481043 "133 ";
BA_ "VFrameFormat" BO_ 2564428768 1;
BA_ "GenMsgSendType" BO_ 2564428768 8;
BA_ "GenMsgNrOfRepetition" BO_ 2564428768 1;
BA_ "DiagRequest" BO_ 2564428768 1;
BA_ "GenMsgILSupport" BO_ 2564428768 0;
BA_ "MsgRoutingId" BO_ 2564428768 "132 ";
BA_ "GenMsgSendType" BO_ 2564481035 8;
BA_ "GenMsgNrOfRepetition" BO_ 2564481035 1;
BA_ "DiagResponse" BO_ 2564481035 1;
BA_ "GenMsgILSupport" BO_ 2564481035 0;
BA_ "MsgRoutingId" BO_ 2564481035 "131 ";
BA_ "VFrameFormat" BO_ 2564481035 15;
BA_ "GenMsgSendType" BO_ 2564426720 8;
BA_ "GenMsgNrOfRepetition" BO_ 2564426720 1;
BA_ "DiagRequest" BO_ 2564426720 1;
BA_ "GenMsgILSupport" BO_ 2564426720 0;
BA_ "MsgRoutingId" BO_ 2564426720 "130 ";
BA_ "VFrameFormat" BO_ 2564426720 15;
BA_ "GenMsgSendType" BO_ 1984 8;
BA_ "GenMsgCycleTimeFast" BO_ 1984 10;
BA_ "GenMsgNrOfRepetition" BO_ 1984 1;
BA_ "VFrameFormat" BO_ 1984 14;
BA_ "GenMsgSendType" BO_ 1955 8;
BA_ "GenMsgNrOfRepetition" BO_ 1955 1;
BA_ "DiagRequest" BO_ 1955 1;
BA_ "GenMsgILSupport" BO_ 1955 0;
BA_ "MsgRoutingId" BO_ 1955 "129 ";
BA_ "GenMsgSendType" BO_ 2017 8;
BA_ "GenMsgNrOfRepetition" BO_ 2017 1;
BA_ "DiagRequest" BO_ 2017 1;
BA_ "GenMsgILSupport" BO_ 2017 0;
BA_ "MsgRoutingId" BO_ 2017 "128 ";
BA_ "GenMsgSendType" BO_ 1954 8;
BA_ "GenMsgNrOfRepetition" BO_ 1954 1;
BA_ "DiagRequest" BO_ 1954 1;
BA_ "GenMsgILSupport" BO_ 1954 0;
BA_ "MsgRoutingId" BO_ 1954 "127 ";
BA_ "GenMsgSendType" BO_ 2016 8;
BA_ "GenMsgNrOfRepetition" BO_ 2016 1;
BA_ "DiagRequest" BO_ 2016 1;
BA_ "GenMsgILSupport" BO_ 2016 0;
BA_ "MsgRoutingId" BO_ 2016 "126 ";
BA_ "VFrameFormat" BO_ 2564550625 1;
BA_ "GenMsgSendType" BO_ 2564550625 8;
BA_ "GenMsgNrOfRepetition" BO_ 2564550625 1;
BA_ "DiagState" BO_ 2564550625 1;
BA_ "GenMsgILSupport" BO_ 2564550625 0;
BA_ "VFrameFormat" BO_ 2564550624 1;
BA_ "GenMsgSendType" BO_ 2564550624 8;
BA_ "GenMsgNrOfRepetition" BO_ 2564550624 1;
BA_ "DiagState" BO_ 2564550624 1;
BA_ "GenMsgILSupport" BO_ 2564550624 0;
BA_ "MsgRoutingId" BO_ 2564550624 "125 ";
BA_ "GenMsgSendType" BO_ 2015 8;
BA_ "GenMsgNrOfRepetition" BO_ 2015 1;
BA_ "DiagState" BO_ 2015 1;
BA_ "GenMsgILSupport" BO_ 2015 0;
BA_ "MsgRoutingId" BO_ 2015 "123 ";
BA_ "GenMsgSendType" BO_ 2564481454 8;
BA_ "GenMsgNrOfRepetition" BO_ 2564481454 1;
BA_ "DiagResponse" BO_ 2564481454 1;
BA_ "GenMsgILSupport" BO_ 2564481454 0;
BA_ "VFrameFormat" BO_ 2564481454 15;
BA_ "GenMsgSendType" BO_ 2564468449 8;
BA_ "GenMsgNrOfRepetition" BO_ 2564468449 1;
BA_ "DiagRequest" BO_ 2564468449 1;
BA_ "GenMsgILSupport" BO_ 2564468449 0;
BA_ "VFrameFormat" BO_ 2564468449 15;
BA_ "GenMsgSendType" BO_ 2564481409 8;
BA_ "GenMsgNrOfRepetition" BO_ 2564481409 1;
BA_ "DiagResponse" BO_ 2564481409 1;
BA_ "GenMsgILSupport" BO_ 2564481409 0;
BA_ "VFrameFormat" BO_ 2564481409 15;
BA_ "GenMsgSendType" BO_ 2564456929 8;
BA_ "GenMsgNrOfRepetition" BO_ 2564456929 1;
BA_ "DiagRequest" BO_ 2564456929 1;
BA_ "GenMsgILSupport" BO_ 2564456929 0;
BA_ "VFrameFormat" BO_ 2564456929 15;
BA_ "GenMsgSendType" BO_ 2564481477 8;
BA_ "GenMsgNrOfRepetition" BO_ 2564481477 1;
BA_ "DiagResponse" BO_ 2564481477 1;
BA_ "GenMsgILSupport" BO_ 2564481477 0;
BA_ "VFrameFormat" BO_ 2564481477 15;
BA_ "GenMsgSendType" BO_ 2564474337 8;
BA_ "GenMsgNrOfRepetition" BO_ 2564474337 1;
BA_ "DiagRequest" BO_ 2564474337 1;
BA_ "GenMsgILSupport" BO_ 2564474337 0;
BA_ "VFrameFormat" BO_ 2564474337 15;
BA_ "VFrameFormat" BO_ 2564481299 1;
BA_ "GenMsgSendType" BO_ 2564481299 8;
BA_ "GenMsgNrOfRepetition" BO_ 2564481299 1;
BA_ "DiagResponse" BO_ 2564481299 1;
BA_ "GenMsgILSupport" BO_ 2564481299 0;
BA_ "VFrameFormat" BO_ 2564428769 1;
BA_ "GenMsgSendType" BO_ 2564428769 8;
BA_ "GenMsgNrOfRepetition" BO_ 2564428769 1;
BA_ "DiagRequest" BO_ 2564428769 1;
BA_ "GenMsgILSupport" BO_ 2564428769 0;
BA_ "GenMsgSendType" BO_ 2564481292 8;
BA_ "GenMsgNrOfRepetition" BO_ 2564481292 1;
BA_ "DiagResponse" BO_ 2564481292 1;
BA_ "GenMsgILSupport" BO_ 2564481292 0;
BA_ "VFrameFormat" BO_ 2564481292 15;
BA_ "GenMsgSendType" BO_ 2564426977 8;
BA_ "GenMsgNrOfRepetition" BO_ 2564426977 1;
BA_ "DiagRequest" BO_ 2564426977 1;
BA_ "GenMsgILSupport" BO_ 2564426977 0;
BA_ "VFrameFormat" BO_ 2564426977 15;
BA_ "GenMsgSendType" BO_ 1900 8;
BA_ "GenMsgNrOfRepetition" BO_ 1900 1;
BA_ "DiagResponse" BO_ 1900 1;
BA_ "GenMsgILSupport" BO_ 1900 0;
BA_ "GenMsgSendType" BO_ 1892 8;
BA_ "GenMsgNrOfRepetition" BO_ 1892 1;
BA_ "DiagRequest" BO_ 1892 1;
BA_ "GenMsgILSupport" BO_ 1892 0;
BA_ "MsgRoutingId" BO_ 1892 "120 ";
BA_ "GenMsgSendType" BO_ 2564481291 8;
BA_ "GenMsgNrOfRepetition" BO_ 2564481291 1;
BA_ "DiagResponse" BO_ 2564481291 1;
BA_ "GenMsgILSupport" BO_ 2564481291 0;
BA_ "VFrameFormat" BO_ 2564481291 15;
BA_ "GenMsgSendType" BO_ 2564426721 8;
BA_ "GenMsgNrOfRepetition" BO_ 2564426721 1;
BA_ "DiagRequest" BO_ 2564426721 1;
BA_ "GenMsgILSupport" BO_ 2564426721 0;
BA_ "VFrameFormat" BO_ 2564426721 15;
BA_ "GenMsgSendType" BO_ 1848 8;
BA_ "GenMsgNrOfRepetition" BO_ 1848 1;
BA_ "DiagResponse" BO_ 1848 1;
BA_ "GenMsgILSupport" BO_ 1848 0;
BA_ "MsgRoutingId" BO_ 1848 "119 ";
BA_ "GenMsgSendType" BO_ 1840 8;
BA_ "GenMsgNrOfRepetition" BO_ 1840 1;
BA_ "DiagRequest" BO_ 1840 1;
BA_ "GenMsgILSupport" BO_ 1840 0;
BA_ "MsgRoutingId" BO_ 1840 "118 ";
BA_ "GenMsgSendType" BO_ 2564481363 8;
BA_ "GenMsgNrOfRepetition" BO_ 2564481363 1;
BA_ "DiagResponse" BO_ 2564481363 1;
BA_ "GenMsgILSupport" BO_ 2564481363 0;
BA_ "VFrameFormat" BO_ 2564481363 1;
BA_ "GenMsgSendType" BO_ 2564445153 8;
BA_ "GenMsgNrOfRepetition" BO_ 2564445153 1;
BA_ "DiagRequest" BO_ 2564445153 1;
BA_ "GenMsgILSupport" BO_ 2564445153 0;
BA_ "VFrameFormat" BO_ 2564445153 1;
BA_ "GenMsgCycleTime" BO_ 1774 1000;
BA_ "VFrameFormat" BO_ 1774 14;
BA_ "GenMsgCycleTime" BO_ 1773 1000;
BA_ "VFrameFormat" BO_ 1773 14;
BA_ "GenMsgCycleTime" BO_ 996 500;
BA_ "GenMsgDelayTime" BO_ 996 10;
BA_ "GenMsgCycleTimeFast" BO_ 996 20;
BA_ "GenMsgNrOfRepetition" BO_ 996 5;
BA_ "VFrameFormat" BO_ 996 14;
BA_ "GenMsgCycleTime" BO_ 981 100;
BA_ "VFrameFormat" BO_ 981 14;
BA_ "GenMsgCycleTime" BO_ 1280 1000;
BA_ "VFrameFormat" BO_ 1280 14;
BA_ "GenMsgCycleTime" BO_ 1633 1000;
BA_ "VFrameFormat" BO_ 1633 14;
BA_ "GenMsgCycleTime" BO_ 1632 500;
BA_ "VFrameFormat" BO_ 1632 14;
BA_ "GenMsgCycleTime" BO_ 1752 1200;
BA_ "GenMsgCycleTimeFast" BO_ 1752 100;
BA_ "GenMsgNrOfRepetition" BO_ 1752 1;
BA_ "MsgRoutingId" BO_ 1752 "117 ";
BA_ "GenMsgILSupport" BO_ 1752 0;
BA_ "VFrameFormat" BO_ 1752 14;
BA_ "GenMsgCycleTime" BO_ 1744 1200;
BA_ "GenMsgCycleTimeFast" BO_ 1744 100;
BA_ "GenMsgNrOfRepetition" BO_ 1744 1;
BA_ "VFrameFormat" BO_ 1744 14;
BA_ "GenMsgCycleTime" BO_ 1743 1200;
BA_ "GenMsgCycleTimeFast" BO_ 1743 100;
BA_ "GenMsgNrOfRepetition" BO_ 1743 1;
BA_ "MsgRoutingId" BO_ 1743 "116 ";
BA_ "GenMsgILSupport" BO_ 1743 0;
BA_ "VFrameFormat" BO_ 1743 14;
BA_ "GenMsgCycleTime" BO_ 1749 1000;
BA_ "GenMsgDelayTime" BO_ 1749 10;
BA_ "GenMsgCycleTimeFast" BO_ 1749 20;
BA_ "GenMsgNrOfRepetition" BO_ 1749 10;
BA_ "VFrameFormat" BO_ 1749 14;
BA_ "GenMsgCycleTime" BO_ 1753 1200;
BA_ "GenMsgDelayTime" BO_ 1753 10;
BA_ "GenMsgNrOfRepetition" BO_ 1753 1;
BA_ "VFrameFormat" BO_ 1753 14;
BA_ "GenMsgCycleTime" BO_ 723 50;
BA_ "GenMsgDelayTime" BO_ 723 10;
BA_ "GenMsgCycleTimeFast" BO_ 723 10;
BA_ "GenMsgNrOfRepetition" BO_ 723 3;
BA_ "VFrameFormat" BO_ 723 14;
BA_ "GenMsgCycleTime" BO_ 1747 1200;
BA_ "GenMsgDelayTime" BO_ 1747 10;
BA_ "GenMsgCycleTimeFast" BO_ 1747 100;
BA_ "GenMsgNrOfRepetition" BO_ 1747 5;
BA_ "VFrameFormat" BO_ 1747 14;
BA_ "GenMsgCycleTime" BO_ 930 100;
BA_ "GenMsgDelayTime" BO_ 930 10;
BA_ "GenMsgCycleTimeFast" BO_ 930 50;
BA_ "GenMsgNrOfRepetition" BO_ 930 4;
BA_ "MsgRoutingId" BO_ 930 "110 ";
BA_ "GenMsgILSupport" BO_ 930 0;
BA_ "VFrameFormat" BO_ 930 14;
BA_ "GenMsgCycleTime" BO_ 1677 1200;
BA_ "GenMsgDelayTime" BO_ 1677 10;
BA_ "GenMsgCycleTimeFast" BO_ 1677 200;
BA_ "GenMsgNrOfRepetition" BO_ 1677 5;
BA_ "MsgRoutingId" BO_ 1677 "109 ";
BA_ "GenMsgILSupport" BO_ 1677 0;
BA_ "VFrameFormat" BO_ 1677 14;
BA_ "GenMsgCycleTime" BO_ 915 100;
BA_ "GenMsgDelayTime" BO_ 915 10;
BA_ "GenMsgCycleTimeFast" BO_ 915 20;
BA_ "GenMsgNrOfRepetition" BO_ 915 2;
BA_ "MsgRoutingId" BO_ 915 "106 ";
BA_ "GenMsgILSupport" BO_ 915 0;
BA_ "VFrameFormat" BO_ 915 14;
BA_ "GenMsgCycleTime" BO_ 912 100;
BA_ "GenMsgDelayTime" BO_ 912 10;
BA_ "GenMsgCycleTimeFast" BO_ 912 50;
BA_ "GenMsgNrOfRepetition" BO_ 912 4;
BA_ "MsgRoutingId" BO_ 912 "105 ";
BA_ "GenMsgILSupport" BO_ 912 0;
BA_ "VFrameFormat" BO_ 912 14;
BA_ "GenMsgCycleTime" BO_ 1291 1000;
BA_ "MsgRoutingId" BO_ 1291 "104 ";
BA_ "GenMsgILSupport" BO_ 1291 0;
BA_ "VFrameFormat" BO_ 1291 14;
BA_ "GenMsgCycleTime" BO_ 28 10;
BA_ "VFrameFormat" BO_ 28 14;
BA_ "GenMsgCycleTime" BO_ 2 10;
BA_ "VFrameFormat" BO_ 2 14;
BA_ "GenMsgCycleTime" BO_ 1349 1000;
BA_ "VFrameFormat" BO_ 1349 14;
BA_ "GenMsgCycleTime" BO_ 1657 1000;
BA_ "MsgRoutingId" BO_ 1657 "94 ";
BA_ "GenMsgILSupport" BO_ 1657 0;
BA_ "VFrameFormat" BO_ 1657 14;
BA_ "GenMsgCycleTime" BO_ 1634 1000;
BA_ "GenMsgCycleTimeFast" BO_ 1634 100;
BA_ "GenMsgNrOfRepetition" BO_ 1634 50;
BA_ "VFrameFormat" BO_ 1634 14;
BA_ "GenMsgCycleTime" BO_ 827 120;
BA_ "GenMsgDelayTime" BO_ 827 10;
BA_ "GenMsgCycleTimeFast" BO_ 827 120;
BA_ "GenMsgNrOfRepetition" BO_ 827 50;
BA_ "MsgRoutingId" BO_ 827 "93 ";
BA_ "VFrameFormat" BO_ 827 14;
BA_ "GenMsgCycleTime" BO_ 826 120;
BA_ "GenMsgDelayTime" BO_ 826 10;
BA_ "GenMsgCycleTimeFast" BO_ 826 120;
BA_ "GenMsgNrOfRepetition" BO_ 826 50;
BA_ "MsgRoutingId" BO_ 826 "92 ";
BA_ "VFrameFormat" BO_ 826 14;
BA_ "GenMsgCycleTime" BO_ 1351 1000;
BA_ "VFrameFormat" BO_ 1351 14;
BA_ "GenMsgCycleTime" BO_ 1315 1000;
BA_ "VFrameFormat" BO_ 1315 14;
BA_ "GenMsgCycleTime" BO_ 962 120;
BA_ "GenMsgCycleTimeFast" BO_ 962 50;
BA_ "GenMsgNrOfRepetition" BO_ 962 3;
BA_ "VFrameFormat" BO_ 962 14;
BA_ "GenMsgCycleTime" BO_ 961 120;
BA_ "GenMsgCycleTimeFast" BO_ 961 50;
BA_ "GenMsgNrOfRepetition" BO_ 961 3;
BA_ "MsgRoutingId" BO_ 961 "91 ";
BA_ "VFrameFormat" BO_ 961 14;
BA_ "GenMsgCycleTime" BO_ 1290 1000;
BA_ "MsgRoutingId" BO_ 1290 "90 ";
BA_ "VFrameFormat" BO_ 1290 14;
BA_ "GenMsgCycleTime" BO_ 1651 1200;
BA_ "GenMsgDelayTime" BO_ 1651 10;
BA_ "GenMsgCycleTimeFast" BO_ 1651 20;
BA_ "GenMsgNrOfRepetition" BO_ 1651 3;
BA_ "MsgRoutingId" BO_ 1651 "89 ";
BA_ "GenMsgILSupport" BO_ 1651 0;
BA_ "VFrameFormat" BO_ 1651 14;
BA_ "GenMsgCycleTime" BO_ 1650 1200;
BA_ "GenMsgDelayTime" BO_ 1650 10;
BA_ "GenMsgCycleTimeFast" BO_ 1650 20;
BA_ "GenMsgNrOfRepetition" BO_ 1650 3;
BA_ "MsgRoutingId" BO_ 1650 "88 ";
BA_ "GenMsgILSupport" BO_ 1650 0;
BA_ "VFrameFormat" BO_ 1650 14;
BA_ "GenMsgCycleTime" BO_ 722 30;
BA_ "MsgRoutingId" BO_ 722 "87 ";
BA_ "GenMsgILSupport" BO_ 722 0;
BA_ "VFrameFormat" BO_ 722 14;
BA_ "GenMsgCycleTime" BO_ 1667 1200;
BA_ "GenMsgDelayTime" BO_ 1667 10;
BA_ "GenMsgCycleTimeFast" BO_ 1667 20;
BA_ "GenMsgNrOfRepetition" BO_ 1667 3;
BA_ "MsgRoutingId" BO_ 1667 "86 ";
BA_ "GenMsgILSupport" BO_ 1667 0;
BA_ "VFrameFormat" BO_ 1667 14;
BA_ "GenMsgCycleTime" BO_ 957 100;
BA_ "GenMsgDelayTime" BO_ 957 10;
BA_ "GenMsgNrOfRepetition" BO_ 957 1;
BA_ "MsgRoutingId" BO_ 957 "85 ";
BA_ "GenMsgILSupport" BO_ 957 0;
BA_ "VFrameFormat" BO_ 957 14;
BA_ "GenMsgCycleTime" BO_ 954 100;
BA_ "GenMsgDelayTime" BO_ 954 10;
BA_ "GenMsgNrOfRepetition" BO_ 954 1;
BA_ "MsgRoutingId" BO_ 954 "84 ";
BA_ "GenMsgILSupport" BO_ 954 0;
BA_ "VFrameFormat" BO_ 954 14;
BA_ "GenMsgCycleTime" BO_ 1659 1000;
BA_ "GenMsgDelayTime" BO_ 1659 10;
BA_ "GenMsgCycleTimeFast" BO_ 1659 20;
BA_ "GenMsgNrOfRepetition" BO_ 1659 3;
BA_ "MsgRoutingId" BO_ 1659 "83 ";
BA_ "GenMsgILSupport" BO_ 1659 0;
BA_ "VFrameFormat" BO_ 1659 14;
BA_ "GenMsgCycleTime" BO_ 1656 1000;
BA_ "MsgRoutingId" BO_ 1656 "82 ";
BA_ "GenMsgILSupport" BO_ 1656 0;
BA_ "VFrameFormat" BO_ 1656 14;
BA_ "GenMsgCycleTime" BO_ 949 100;
BA_ "GenMsgDelayTime" BO_ 949 10;
BA_ "GenMsgNrOfRepetition" BO_ 949 1;
BA_ "MsgRoutingId" BO_ 949 "81 ";
BA_ "GenMsgILSupport" BO_ 949 0;
BA_ "VFrameFormat" BO_ 949 14;
BA_ "GenSigSendType" SG_ 2564481198 DMS18DAE0AE_DIAG_DATA_EXT7 2;
BA_ "GenSigSendType" SG_ 2564481198 DMS18DAE0AE_DIAG_DATA_EXT6 2;
BA_ "GenSigSendType" SG_ 2564481198 DMS18DAE0AE_DIAG_DATA_EXT5 2;
BA_ "GenSigSendType" SG_ 2564481198 DMS18DAE0AE_DIAG_DATA_EXT4 2;
BA_ "GenSigSendType" SG_ 2564481198 DMS18DAE0AE_DIAG_DATA_EXT3 2;
BA_ "GenSigSendType" SG_ 2564481198 DMS18DAE0AE_DIAG_DATA_EXT2 2;
BA_ "GenSigSendType" SG_ 2564481198 DMS18DAE0AE_DIAG_DATA_EXT1 2;
BA_ "GenSigSendType" SG_ 2564481198 DMS18DAE0AE_DIAG_DATA 2;
BA_ "GenSigSendType" SG_ 2564468448 DNT18DAAEE0_DIAG_DATA_EXT7 2;
BA_ "GenSigSendType" SG_ 2564468448 DNT18DAAEE0_DIAG_DATA_EXT6 2;
BA_ "GenSigSendType" SG_ 2564468448 DNT18DAAEE0_DIAG_DATA_EXT5 2;
BA_ "GenSigSendType" SG_ 2564468448 DNT18DAAEE0_DIAG_DATA_EXT4 2;
BA_ "GenSigSendType" SG_ 2564468448 DNT18DAAEE0_DIAG_DATA_EXT3 2;
BA_ "GenSigSendType" SG_ 2564468448 DNT18DAAEE0_DIAG_DATA_EXT2 2;
BA_ "GenSigSendType" SG_ 2564468448 DNT18DAAEE0_DIAG_DATA_EXT1 2;
BA_ "GenSigSendType" SG_ 2564468448 DNT18DAAEE0_DIAG_DATA 2;
BA_ "GenSigSendType" SG_ 2564481036 BST18DAE00C_DIAG_DATA_EXT7 2;
BA_ "GenSigSendType" SG_ 2564481036 BST18DAE00C_DIAG_DATA_EXT6 2;
BA_ "GenSigSendType" SG_ 2564481036 BST18DAE00C_DIAG_DATA_EXT5 2;
BA_ "GenSigSendType" SG_ 2564481036 BST18DAE00C_DIAG_DATA_EXT4 2;
BA_ "GenSigSendType" SG_ 2564481036 BST18DAE00C_DIAG_DATA_EXT3 2;
BA_ "GenSigSendType" SG_ 2564481036 BST18DAE00C_DIAG_DATA_EXT2 2;
BA_ "GenSigSendType" SG_ 2564481036 BST18DAE00C_DIAG_DATA_EXT1 2;
BA_ "GenSigSendType" SG_ 2564481036 BST18DAE00C_DIAG_DATA 2;
BA_ "GenSigSendType" SG_ 2564426976 DNT18DA0CE0_DIAG_DATA_EXT7 2;
BA_ "GenSigSendType" SG_ 2564426976 DNT18DA0CE0_DIAG_DATA_EXT6 2;
BA_ "GenSigSendType" SG_ 2564426976 DNT18DA0CE0_DIAG_DATA_EXT5 2;
BA_ "GenSigSendType" SG_ 2564426976 DNT18DA0CE0_DIAG_DATA_EXT4 2;
BA_ "GenSigSendType" SG_ 2564426976 DNT18DA0CE0_DIAG_DATA_EXT3 2;
BA_ "GenSigSendType" SG_ 2564426976 DNT18DA0CE0_DIAG_DATA_EXT2 2;
BA_ "GenSigSendType" SG_ 2564426976 DNT18DA0CE0_DIAG_DATA_EXT1 2;
BA_ "GenSigSendType" SG_ 2564426976 DNT18DA0CE0_DIAG_DATA 2;
BA_ "GenSigSendType" SG_ 2564481153 MCA18DAE081_DIAG_DATA_EXT7 2;
BA_ "GenSigSendType" SG_ 2564481153 MCA18DAE081_DIAG_DATA_EXT6 2;
BA_ "GenSigSendType" SG_ 2564481153 MCA18DAE081_DIAG_DATA_EXT5 2;
BA_ "GenSigSendType" SG_ 2564481153 MCA18DAE081_DIAG_DATA_EXT4 2;
BA_ "GenSigSendType" SG_ 2564481153 MCA18DAE081_DIAG_DATA_EXT3 2;
BA_ "GenSigSendType" SG_ 2564481153 MCA18DAE081_DIAG_DATA_EXT2 2;
BA_ "GenSigSendType" SG_ 2564481153 MCA18DAE081_DIAG_DATA_EXT1 2;
BA_ "GenSigSendType" SG_ 2564481153 MCA18DAE081_DIAG_DATA 2;
BA_ "GenSigSendType" SG_ 2564456928 DNT18DA81E0_DIAG_DATA_EXT7 2;
BA_ "GenSigSendType" SG_ 2564456928 DNT18DA81E0_DIAG_DATA_EXT6 2;
BA_ "GenSigSendType" SG_ 2564456928 DNT18DA81E0_DIAG_DATA_EXT5 2;
BA_ "GenSigSendType" SG_ 2564456928 DNT18DA81E0_DIAG_DATA_EXT4 2;
BA_ "GenSigSendType" SG_ 2564456928 DNT18DA81E0_DIAG_DATA_EXT3 2;
BA_ "GenSigSendType" SG_ 2564456928 DNT18DA81E0_DIAG_DATA_EXT2 2;
BA_ "GenSigSendType" SG_ 2564456928 DNT18DA81E0_DIAG_DATA_EXT1 2;
BA_ "GenSigSendType" SG_ 2564456928 DNT18DA81E0_DIAG_DATA 2;
BA_ "GenSigSendType" SG_ 2564481154 FCRL18DAE082_DIAG_DATA_EXT7 2;
BA_ "GenSigSendType" SG_ 2564481154 FCRL18DAE082_DIAG_DATA_EXT6 2;
BA_ "GenSigSendType" SG_ 2564481154 FCRL18DAE082_DIAG_DATA_EXT5 2;
BA_ "GenSigSendType" SG_ 2564481154 FCRL18DAE082_DIAG_DATA_EXT4 2;
BA_ "GenSigSendType" SG_ 2564481154 FCRL18DAE082_DIAG_DATA_EXT3 2;
BA_ "GenSigSendType" SG_ 2564481154 FCRL18DAE082_DIAG_DATA_EXT2 2;
BA_ "GenSigSendType" SG_ 2564481154 FCRL18DAE082_DIAG_DATA_EXT1 2;
BA_ "GenSigSendType" SG_ 2564481154 FCRL18DAE082_DIAG_DATA 2;
BA_ "GenSigSendType" SG_ 2564457184 DNT18DA82E0_DIAG_DATA_EXT7 2;
BA_ "GenSigSendType" SG_ 2564457184 DNT18DA82E0_DIAG_DATA_EXT6 2;
BA_ "GenSigSendType" SG_ 2564457184 DNT18DA82E0_DIAG_DATA_EXT5 2;
BA_ "GenSigSendType" SG_ 2564457184 DNT18DA82E0_DIAG_DATA_EXT4 2;
BA_ "GenSigSendType" SG_ 2564457184 DNT18DA82E0_DIAG_DATA_EXT3 2;
BA_ "GenSigSendType" SG_ 2564457184 DNT18DA82E0_DIAG_DATA_EXT2 2;
BA_ "GenSigSendType" SG_ 2564457184 DNT18DA82E0_DIAG_DATA_EXT1 2;
BA_ "GenSigSendType" SG_ 2564457184 DNT18DA82E0_DIAG_DATA 2;
BA_ "GenSigSendType" SG_ 2564481155 FCRR18DAE083_DIAG_DATA_EXT7 2;
BA_ "GenSigSendType" SG_ 2564481155 FCRR18DAE083_DIAG_DATA_EXT6 2;
BA_ "GenSigSendType" SG_ 2564481155 FCRR18DAE083_DIAG_DATA_EXT5 2;
BA_ "GenSigSendType" SG_ 2564481155 FCRR18DAE083_DIAG_DATA_EXT4 2;
BA_ "GenSigSendType" SG_ 2564481155 FCRR18DAE083_DIAG_DATA_EXT3 2;
BA_ "GenSigSendType" SG_ 2564481155 FCRR18DAE083_DIAG_DATA_EXT2 2;
BA_ "GenSigSendType" SG_ 2564481155 FCRR18DAE083_DIAG_DATA_EXT1 2;
BA_ "GenSigSendType" SG_ 2564481155 FCRR18DAE083_DIAG_DATA 2;
BA_ "GenSigSendType" SG_ 2564457440 DNT18DA83E0_DIAG_DATA_EXT7 2;
BA_ "GenSigSendType" SG_ 2564457440 DNT18DA83E0_DIAG_DATA_EXT6 2;
BA_ "GenSigSendType" SG_ 2564457440 DNT18DA83E0_DIAG_DATA_EXT5 2;
BA_ "GenSigSendType" SG_ 2564457440 DNT18DA83E0_DIAG_DATA_EXT4 2;
BA_ "GenSigSendType" SG_ 2564457440 DNT18DA83E0_DIAG_DATA_EXT3 2;
BA_ "GenSigSendType" SG_ 2564457440 DNT18DA83E0_DIAG_DATA_EXT2 2;
BA_ "GenSigSendType" SG_ 2564457440 DNT18DA83E0_DIAG_DATA_EXT1 2;
BA_ "GenSigSendType" SG_ 2564457440 DNT18DA83E0_DIAG_DATA 2;
BA_ "GenSigSendType" SG_ 2564481107 ABG18DAE053_DIAG_DATA 2;
BA_ "GenSigSendType" SG_ 2564445152 DNT18DA53E0_DIAG_DATA 2;
BA_ "GenSigSendType" SG_ 2564481101 STA18DAE04D_DIAG_DATA_EXT7 2;
BA_ "GenSigSendType" SG_ 2564481101 STA18DAE04D_DIAG_DATA_EXT6 2;
BA_ "GenSigSendType" SG_ 2564481101 STA18DAE04D_DIAG_DATA_EXT5 2;
BA_ "GenSigSendType" SG_ 2564481101 STA18DAE04D_DIAG_DATA_EXT4 2;
BA_ "GenSigSendType" SG_ 2564481101 STA18DAE04D_DIAG_DATA_EXT3 2;
BA_ "GenSigSendType" SG_ 2564481101 STA18DAE04D_DIAG_DATA_EXT2 2;
BA_ "GenSigSendType" SG_ 2564481101 STA18DAE04D_DIAG_DATA_EXT1 2;
BA_ "GenSigSendType" SG_ 2564481101 STA18DAE04D_DIAG_DATA 2;
BA_ "GenSigSendType" SG_ 2564443616 DNT18DA4DE0_DIAG_DATA_EXT7 2;
BA_ "GenSigSendType" SG_ 2564443616 DNT18DA4DE0_DIAG_DATA_EXT6 2;
BA_ "GenSigSendType" SG_ 2564443616 DNT18DA4DE0_DIAG_DATA_EXT5 2;
BA_ "GenSigSendType" SG_ 2564443616 DNT18DA4DE0_DIAG_DATA_EXT4 2;
BA_ "GenSigSendType" SG_ 2564443616 DNT18DA4DE0_DIAG_DATA_EXT3 2;
BA_ "GenSigSendType" SG_ 2564443616 DNT18DA4DE0_DIAG_DATA_EXT2 2;
BA_ "GenSigSendType" SG_ 2564443616 DNT18DA4DE0_DIAG_DATA_EXT1 2;
BA_ "GenSigSendType" SG_ 2564443616 DNT18DA4DE0_DIAG_DATA 2;
BA_ "GenSigSendType" SG_ 2564481043 EPS18DAE013_DIAG_DATA_EXT7 2;
BA_ "GenSigSendType" SG_ 2564481043 EPS18DAE013_DIAG_DATA_EXT6 2;
BA_ "GenSigSendType" SG_ 2564481043 EPS18DAE013_DIAG_DATA_EXT5 2;
BA_ "GenSigSendType" SG_ 2564481043 EPS18DAE013_DIAG_DATA_EXT4 2;
BA_ "GenSigSendType" SG_ 2564481043 EPS18DAE013_DIAG_DATA_EXT3 2;
BA_ "GenSigSendType" SG_ 2564481043 EPS18DAE013_DIAG_DATA_EXT2 2;
BA_ "GenSigSendType" SG_ 2564481043 EPS18DAE013_DIAG_DATA_EXT1 2;
BA_ "GenSigSendType" SG_ 2564481043 EPS18DAE013_DIAG_DATA 2;
BA_ "GenSigSendType" SG_ 2564428768 DNT18DA13E0_DIAG_DATA_EXT7 2;
BA_ "GenSigSendType" SG_ 2564428768 DNT18DA13E0_DIAG_DATA_EXT6 2;
BA_ "GenSigSendType" SG_ 2564428768 DNT18DA13E0_DIAG_DATA_EXT5 2;
BA_ "GenSigSendType" SG_ 2564428768 DNT18DA13E0_DIAG_DATA_EXT4 2;
BA_ "GenSigSendType" SG_ 2564428768 DNT18DA13E0_DIAG_DATA_EXT3 2;
BA_ "GenSigSendType" SG_ 2564428768 DNT18DA13E0_DIAG_DATA_EXT2 2;
BA_ "GenSigSendType" SG_ 2564428768 DNT18DA13E0_DIAG_DATA_EXT1 2;
BA_ "GenSigSendType" SG_ 2564428768 DNT18DA13E0_DIAG_DATA 2;
BA_ "GenSigSendType" SG_ 2564481035 VDC18DAE00B_DIAG_DATA_EXT7 2;
BA_ "GenSigSendType" SG_ 2564481035 VDC18DAE00B_DIAG_DATA_EXT6 2;
BA_ "GenSigSendType" SG_ 2564481035 VDC18DAE00B_DIAG_DATA_EXT5 2;
BA_ "GenSigSendType" SG_ 2564481035 VDC18DAE00B_DIAG_DATA_EXT4 2;
BA_ "GenSigSendType" SG_ 2564481035 VDC18DAE00B_DIAG_DATA_EXT3 2;
BA_ "GenSigSendType" SG_ 2564481035 VDC18DAE00B_DIAG_DATA_EXT2 2;
BA_ "GenSigSendType" SG_ 2564481035 VDC18DAE00B_DIAG_DATA_EXT1 2;
BA_ "GenSigSendType" SG_ 2564481035 VDC18DAE00B_DIAG_DATA 2;
BA_ "GenSigSendType" SG_ 2564426720 DNT18DA0BE0_DIAG_DATA_EXT7 2;
BA_ "GenSigSendType" SG_ 2564426720 DNT18DA0BE0_DIAG_DATA_EXT6 2;
BA_ "GenSigSendType" SG_ 2564426720 DNT18DA0BE0_DIAG_DATA_EXT5 2;
BA_ "GenSigSendType" SG_ 2564426720 DNT18DA0BE0_DIAG_DATA_EXT4 2;
BA_ "GenSigSendType" SG_ 2564426720 DNT18DA0BE0_DIAG_DATA_EXT3 2;
BA_ "GenSigSendType" SG_ 2564426720 DNT18DA0BE0_DIAG_DATA_EXT2 2;
BA_ "GenSigSendType" SG_ 2564426720 DNT18DA0BE0_DIAG_DATA_EXT1 2;
BA_ "GenSigSendType" SG_ 2564426720 DNT18DA0BE0_DIAG_DATA 2;
BA_ "GenSigSendType" SG_ 1984 VDC7C0_2_0_REQ_CALIB_CANSTO 4;
BA_ "GenSigSendType" SG_ 1955 DNT7A3_DIAG_DATA_EXT7 2;
BA_ "GenSigSendType" SG_ 1955 DNT7A3_DIAG_DATA_EXT6 2;
BA_ "GenSigSendType" SG_ 1955 DNT7A3_DIAG_DATA_EXT5 2;
BA_ "GenSigSendType" SG_ 1955 DNT7A3_DIAG_DATA_EXT4 2;
BA_ "GenSigSendType" SG_ 1955 DNT7A3_DIAG_DATA_EXT3 2;
BA_ "GenSigSendType" SG_ 1955 DNT7A3_DIAG_DATA_EXT2 2;
BA_ "GenSigSendType" SG_ 1955 DNT7A3_DIAG_DATA_EXT1 2;
BA_ "GenSigSendType" SG_ 1955 DNT7A3_DIAG_DATA 2;
BA_ "GenSigSendType" SG_ 2017 DNT7E1_DIAG_DATA_EXT7 2;
BA_ "GenSigSendType" SG_ 2017 DNT7E1_DIAG_DATA_EXT6 2;
BA_ "GenSigSendType" SG_ 2017 DNT7E1_DIAG_DATA_EXT5 2;
BA_ "GenSigSendType" SG_ 2017 DNT7E1_DIAG_DATA_EXT4 2;
BA_ "GenSigSendType" SG_ 2017 DNT7E1_DIAG_DATA_EXT3 2;
BA_ "GenSigSendType" SG_ 2017 DNT7E1_DIAG_DATA_EXT2 2;
BA_ "GenSigSendType" SG_ 2017 DNT7E1_DIAG_DATA_EXT1 2;
BA_ "GenSigSendType" SG_ 2017 DNT7E1_DIAG_DATA 2;
BA_ "GenSigSendType" SG_ 1954 DNT7A2_DIAG_DATA_EXT7 2;
BA_ "GenSigSendType" SG_ 1954 DNT7A2_DIAG_DATA_EXT6 2;
BA_ "GenSigSendType" SG_ 1954 DNT7A2_DIAG_DATA_EXT5 2;
BA_ "GenSigSendType" SG_ 1954 DNT7A2_DIAG_DATA_EXT4 2;
BA_ "GenSigSendType" SG_ 1954 DNT7A2_DIAG_DATA_EXT3 2;
BA_ "GenSigSendType" SG_ 1954 DNT7A2_DIAG_DATA_EXT2 2;
BA_ "GenSigSendType" SG_ 1954 DNT7A2_DIAG_DATA_EXT1 2;
BA_ "GenSigSendType" SG_ 1954 DNT7A2_DIAG_DATA 2;
BA_ "GenSigSendType" SG_ 2016 DNT7E0_DIAG_DATA_EXT7 2;
BA_ "GenSigSendType" SG_ 2016 DNT7E0_DIAG_DATA_EXT6 2;
BA_ "GenSigSendType" SG_ 2016 DNT7E0_DIAG_DATA_EXT5 2;
BA_ "GenSigSendType" SG_ 2016 DNT7E0_DIAG_DATA_EXT4 2;
BA_ "GenSigSendType" SG_ 2016 DNT7E0_DIAG_DATA_EXT3 2;
BA_ "GenSigSendType" SG_ 2016 DNT7E0_DIAG_DATA_EXT2 2;
BA_ "GenSigSendType" SG_ 2016 DNT7E0_DIAG_DATA_EXT1 2;
BA_ "GenSigSendType" SG_ 2016 DNT7E0_DIAG_DATA 2;
BA_ "GenSigSendType" SG_ 2564550625 CECU18DBEFE1_DIAG_DATA 2;
BA_ "GenSigSendType" SG_ 2564550624 DNT18DBEFE0_DIAG_DATA 2;
BA_ "GenSigSendType" SG_ 2015 DNT7DF_7_0_DIAG_DATA 2;
BA_ "GenSigSendType" SG_ 2015 DNT7DF_2_0_DIAG_N_PCI_OR_DATA 2;
BA_ "GenSigSendType" SG_ 2015 DNT7DF_1_0_DIAG_N_PCI_OR_DATA 2;
BA_ "GenSigSendType" SG_ 2015 DNT7DF_0_0_DIAG_N_PCI 2;
BA_ "GenSigSendType" SG_ 2564481454 DMS18DAE1AE_DIAG_DATA_EXT7 2;
BA_ "GenSigSendType" SG_ 2564481454 DMS18DAE1AE_DIAG_DATA_EXT6 2;
BA_ "GenSigSendType" SG_ 2564481454 DMS18DAE1AE_DIAG_DATA_EXT5 2;
BA_ "GenSigSendType" SG_ 2564481454 DMS18DAE1AE_DIAG_DATA_EXT4 2;
BA_ "GenSigSendType" SG_ 2564481454 DMS18DAE1AE_DIAG_DATA_EXT3 2;
BA_ "GenSigSendType" SG_ 2564481454 DMS18DAE1AE_DIAG_DATA_EXT2 2;
BA_ "GenSigSendType" SG_ 2564481454 DMS18DAE1AE_DIAG_DATA_EXT1 2;
BA_ "GenSigSendType" SG_ 2564481454 DMS18DAE1AE_DIAG_DATA 2;
BA_ "GenSigSendType" SG_ 2564468449 CECU18DAAEE1_DIAG_DATA_EXT7 2;
BA_ "GenSigSendType" SG_ 2564468449 CECU18DAAEE1_DIAG_DATA_EXT6 2;
BA_ "GenSigSendType" SG_ 2564468449 CECU18DAAEE1_DIAG_DATA_EXT5 2;
BA_ "GenSigSendType" SG_ 2564468449 CECU18DAAEE1_DIAG_DATA_EXT4 2;
BA_ "GenSigSendType" SG_ 2564468449 CECU18DAAEE1_DIAG_DATA_EXT3 2;
BA_ "GenSigSendType" SG_ 2564468449 CECU18DAAEE1_DIAG_DATA_EXT2 2;
BA_ "GenSigSendType" SG_ 2564468449 CECU18DAAEE1_DIAG_DATA_EXT1 2;
BA_ "GenSigSendType" SG_ 2564468449 CECU18DAAEE1_DIAG_DATA 2;
BA_ "GenSigSendType" SG_ 2564481409 MCA18DAE181_DIAG_DATA_EXT7 2;
BA_ "GenSigSendType" SG_ 2564481409 MCA18DAE181_DIAG_DATA_EXT6 2;
BA_ "GenSigSendType" SG_ 2564481409 MCA18DAE181_DIAG_DATA_EXT5 2;
BA_ "GenSigSendType" SG_ 2564481409 MCA18DAE181_DIAG_DATA_EXT4 2;
BA_ "GenSigSendType" SG_ 2564481409 MCA18DAE181_DIAG_DATA_EXT3 2;
BA_ "GenSigSendType" SG_ 2564481409 MCA18DAE181_DIAG_DATA_EXT2 2;
BA_ "GenSigSendType" SG_ 2564481409 MCA18DAE181_DIAG_DATA_EXT1 2;
BA_ "GenSigSendType" SG_ 2564481409 MCA18DAE181_DIAG_DATA 2;
BA_ "GenSigSendType" SG_ 2564456929 CECU18DA81E1_DIAG_DATA_EXT7 2;
BA_ "GenSigSendType" SG_ 2564456929 CECU18DA81E1_DIAG_DATA_EXT6 2;
BA_ "GenSigSendType" SG_ 2564456929 CECU18DA81E1_DIAG_DATA_EXT5 2;
BA_ "GenSigSendType" SG_ 2564456929 CECU18DA81E1_DIAG_DATA_EXT4 2;
BA_ "GenSigSendType" SG_ 2564456929 CECU18DA81E1_DIAG_DATA_EXT3 2;
BA_ "GenSigSendType" SG_ 2564456929 CECU18DA81E1_DIAG_DATA_EXT2 2;
BA_ "GenSigSendType" SG_ 2564456929 CECU18DA81E1_DIAG_DATA_EXT1 2;
BA_ "GenSigSendType" SG_ 2564456929 CECU18DA81E1_DIAG_DATA 2;
BA_ "GenSigSendType" SG_ 2564481477 BEV18DAE1C5_DIAG_DATA_EXT7 2;
BA_ "GenSigSendType" SG_ 2564481477 BEV18DAE1C5_DIAG_DATA_EXT6 2;
BA_ "GenSigSendType" SG_ 2564481477 BEV18DAE1C5_DIAG_DATA_EXT5 2;
BA_ "GenSigSendType" SG_ 2564481477 BEV18DAE1C5_DIAG_DATA_EXT4 2;
BA_ "GenSigSendType" SG_ 2564481477 BEV18DAE1C5_DIAG_DATA_EXT3 2;
BA_ "GenSigSendType" SG_ 2564481477 BEV18DAE1C5_DIAG_DATA_EXT2 2;
BA_ "GenSigSendType" SG_ 2564481477 BEV18DAE1C5_DIAG_DATA_EXT1 2;
BA_ "GenSigSendType" SG_ 2564481477 BEV18DAE1C5_DIAG_DATA 2;
BA_ "GenSigSendType" SG_ 2564474337 CECU18DAC5E1_DIAG_DATA_EXT7 2;
BA_ "GenSigSendType" SG_ 2564474337 CECU18DAC5E1_DIAG_DATA_EXT6 2;
BA_ "GenSigSendType" SG_ 2564474337 CECU18DAC5E1_DIAG_DATA_EXT5 2;
BA_ "GenSigSendType" SG_ 2564474337 CECU18DAC5E1_DIAG_DATA_EXT4 2;
BA_ "GenSigSendType" SG_ 2564474337 CECU18DAC5E1_DIAG_DATA_EXT3 2;
BA_ "GenSigSendType" SG_ 2564474337 CECU18DAC5E1_DIAG_DATA_EXT2 2;
BA_ "GenSigSendType" SG_ 2564474337 CECU18DAC5E1_DIAG_DATA_EXT1 2;
BA_ "GenSigSendType" SG_ 2564474337 CECU18DAC5E1_DIAG_DATA 2;
BA_ "GenSigSendType" SG_ 2564481299 EPS18DAE113_DIAG_DATA 2;
BA_ "GenSigSendType" SG_ 2564428769 CECU18DA13E1_DIAG_DATA 2;
BA_ "GenSigSendType" SG_ 2564481292 BST18DAE10C_DIAG_DATA_EXT7 2;
BA_ "GenSigSendType" SG_ 2564481292 BST18DAE10C_DIAG_DATA_EXT6 2;
BA_ "GenSigSendType" SG_ 2564481292 BST18DAE10C_DIAG_DATA_EXT5 2;
BA_ "GenSigSendType" SG_ 2564481292 BST18DAE10C_DIAG_DATA_EXT4 2;
BA_ "GenSigSendType" SG_ 2564481292 BST18DAE10C_DIAG_DATA_EXT3 2;
BA_ "GenSigSendType" SG_ 2564481292 BST18DAE10C_DIAG_DATA_EXT2 2;
BA_ "GenSigSendType" SG_ 2564481292 BST18DAE10C_DIAG_DATA_EXT1 2;
BA_ "GenSigSendType" SG_ 2564481292 BST18DAE10C_DIAG_DATA 2;
BA_ "GenSigSendType" SG_ 2564426977 CECU18DA0CE1_DIAG_DATA 2;
BA_ "GenSigSendType" SG_ 1900 BST76C_7_0_DIAG_DATA 2;
BA_ "GenSigSendType" SG_ 1900 BST76C_2_0_DIAG_N_PCI_OR_DATA 2;
BA_ "GenSigSendType" SG_ 1900 BST76C_1_0_DIAG_N_PCI_OR_DATA 2;
BA_ "GenSigSendType" SG_ 1900 BST76C_0_0_DIAG_N_PCI 2;
BA_ "GenSigSendType" SG_ 1892 DCM764_7_0_DIAG_DATA 2;
BA_ "GenSigSendType" SG_ 1892 DCM764_2_0_DIAG_N_PCI_OR_DATA 2;
BA_ "GenSigSendType" SG_ 1892 DCM764_1_0_DIAG_N_PCI_OR_DATA 2;
BA_ "GenSigSendType" SG_ 1892 DCM764_0_0_DIAG_N_PCI 2;
BA_ "GenSigSendType" SG_ 2564481291 VDC18DAE10B_DIAG_DATA_EXT7 2;
BA_ "GenSigSendType" SG_ 2564481291 VDC18DAE10B_DIAG_DATA_EXT6 2;
BA_ "GenSigSendType" SG_ 2564481291 VDC18DAE10B_DIAG_DATA_EXT5 2;
BA_ "GenSigSendType" SG_ 2564481291 VDC18DAE10B_DIAG_DATA_EXT4 2;
BA_ "GenSigSendType" SG_ 2564481291 VDC18DAE10B_DIAG_DATA_EXT3 2;
BA_ "GenSigSendType" SG_ 2564481291 VDC18DAE10B_DIAG_DATA_EXT2 2;
BA_ "GenSigSendType" SG_ 2564481291 VDC18DAE10B_DIAG_DATA_EXT1 2;
BA_ "GenSigSendType" SG_ 2564481291 VDC18DAE10B_DIAG_DATA 2;
BA_ "GenSigSendType" SG_ 2564426721 CECU18DA0BE1_DIAG_DATA 2;
BA_ "GenSigSendType" SG_ 1848 VDC738_7_0_DIAG_DATA 2;
BA_ "GenSigSendType" SG_ 1848 VDC738_2_0_DIAG_N_PCI_OR_DATA 2;
BA_ "GenSigSendType" SG_ 1848 VDC738_1_0_DIAG_N_PCI_OR_DATA 2;
BA_ "GenSigSendType" SG_ 1848 VDC738_0_0_DIAG_N_PCI 2;
BA_ "GenSigSendType" SG_ 1840 DCM730_7_0_DIAG_DATA 2;
BA_ "GenSigSendType" SG_ 1840 DCM730_2_0_DIAG_N_PCI_OR_DATA 2;
BA_ "GenSigSendType" SG_ 1840 DCM730_1_0_DIAG_N_PCI_OR_DATA 2;
BA_ "GenSigSendType" SG_ 1840 DCM730_0_0_DIAG_N_PCI 2;
BA_ "GenSigSendType" SG_ 2564481363 ABG18DAE153_DIAG_DATA 2;
BA_ "GenSigSendType" SG_ 2564445153 CECU18DA53E1_DIAG_DATA 2;
BA_ "GenSigStartValue" SG_ 996 CECU3E4_6_0_CHARGE_LEVEL_ENG_RUN 3;
BA_ "GenSigStartValue" SG_ 996 CECU3E4_6_4_CHARGE_LEVEL_IGN_ON 3;
BA_ "GenSigStartValue" SG_ 1632 CGW660_1_0_SUB_ID 65535;
BA_ "GenSigSendType" SG_ 1753 CECU6D9_2_0_RCC_DOOR_LOCK_REQ 3;
BA_ "GenSigSendType" SG_ 1753 CECU6D9_2_1_RCC_KEY_SEARCH_REQ 3;
BA_ "GenSigSendType" SG_ 1753 CECU6D9_2_2_RCC_BWAM_SETTING 3;
BA_ "GenSigSendType" SG_ 1753 CECU6D9_1_4_RCC_FLG 3;
BA_ "GenSigSendType" SG_ 1753 CECU6D9_0_0_CHECK_SUM 3;
BA_ "GenSigStartValue" SG_ 930 MET3A2_7_0_FUEL_AMOUNT 254;
BA_ "GenSigStartValue" SG_ 1677 MET68D_5_0_TEMP_FOR_PPA 8191;
BA_ "Fhi_SignalComment" SG_ 1677 MET68D_2_0_ODO "000000h～98967Fh：正常

989680h～FFFFFEh：未使用

FFFFFFh：異常

";
BA_ "GenSigStartValue" SG_ 915 MET393_6_0_R_DIFF_TEMP 253;
BA_ "Fhi_SignalComment" SG_ 915 MET393_6_0_R_DIFF_TEMP "IGN-ON初回送信時はFEhを送信する。

";
BA_ "GenSigStartValue" SG_ 915 MET393_4_0_FUEL_LEVEL_RESIST 1022;
BA_ "Fhi_SignalComment" SG_ 915 MET393_3_5_SI_DRIVE_SW "IGN　ON時の初期値は各SIドライブとXモードの組み合わせにより異なる。

";
BA_ "GenSigStartValue" SG_ 915 MET393_2_0_OUTTEMP_FOR_DIAG 8191;
BA_ "Fhi_SignalComment" SG_ 912 MET390_6_0_SEATBELT_DRVR "IGN-OFF中は0送信

";
BA_ "Fhi_SignalComment" SG_ 912 MET390_6_1_SEATBELT_PASS "IGN-OFF中は0送信

";
BA_ "GenSigStartValue" SG_ 912 MET390_4_0_OUTTEMP_FOR_IND 254;
BA_ "Fhi_SignalComment" SG_ 912 MET390_4_0_OUTTEMP_FOR_IND "IGN-OFF中は初期値：FEh送信

";
BA_ "Fhi_SignalComment" SG_ 912 MET390_2_0_VEHICLE_SERIES "GW:ID390-B2b2~b0→ID2BE-B5b2~b0

";
BA_ "Fhi_SignalComment" SG_ 912 MET390_2_3_DESTINATION "GW:ID390-B2b6~b3→ID2BE-B5b6~b3

";
BA_ "GenSigSendType" SG_ 1657 TPM679_3_0_STATE_TPMS 3;
BA_ "Fhi_SignalComment" SG_ 1657 TPM679_3_2_DEFINED_STATE_TPMS "※閾値設定スイッチがタッチパネルの車は、送信値を0固定とする。

";
BA_ "GenSigSendType" SG_ 1657 TPM679_3_2_DEFINED_STATE_TPMS 3;
BA_ "GenSigSendType" SG_ 1657 TPM679_2_0_WARN_TPMS 3;
BA_ "GenSigSendType" SG_ 1657 TPM679_2_3_INTERRUPT 3;
BA_ "GenSigStartValue" SG_ 827 ABG33B_4_0_PASSENGER_BELT_INFO 2;
BA_ "GenSigStartValue" SG_ 827 ABG33B_4_2_PASSENGER_DETECT_INFO 4;
BA_ "GenSigStartValue" SG_ 827 ABG33B_2_0_IND_WARN_PPA 3;
BA_ "GenSigStartValue" SG_ 826 ABG33A_3_0_BELT_WRNING_PASS 2;
BA_ "GenSigStartValue" SG_ 826 ABG33A_3_4_OCCUPATION_PASS 2;
BA_ "GenSigStartValue" SG_ 826 ABG33A_2_0_IND_WARN_ABG 3;
BA_ "GenSigStartValue" SG_ 962 DMS3C2_27_2_EYE_CLOSE_TIME 63;
BA_ "GenSigStartValue" SG_ 962 DMS3C2_26_3_DIST_TIME 127;
BA_ "GenSigStartValue" SG_ 962 DMS3C2_24_4_GAZE_CONF_RIGHT 127;
BA_ "GenSigStartValue" SG_ 962 DMS3C2_23_3_GAZE_PITCH_RIGHT 255;
BA_ "GenSigStartValue" SG_ 962 DMS3C2_22_2_GAZE_YAW_RIGHT 255;
BA_ "GenSigStartValue" SG_ 962 DMS3C2_21_3_GAZE_CONF_LEFT 127;
BA_ "GenSigStartValue" SG_ 962 DMS3C2_20_2_GAZE_PITCH_LEFT 255;
BA_ "GenSigStartValue" SG_ 962 DMS3C2_19_1_GAZE_YAW_LEFT 255;
BA_ "GenSigStartValue" SG_ 962 DMS3C2_17_6_DRIVER_HEAD_POS_Z 1023;
BA_ "GenSigStartValue" SG_ 962 DMS3C2_16_3_DRIVER_HEAD_POS_Y 1023;
BA_ "GenSigStartValue" SG_ 962 DMS3C2_15_0_DRIVER_HEAD_POS_X 2047;
BA_ "GenSigStartValue" SG_ 962 DMS3C2_13_4_VTX_RIGHT_BTM_Y 4095;
BA_ "GenSigStartValue" SG_ 962 DMS3C2_12_0_VTX_RIGHT_BTM_X 4095;
BA_ "GenSigStartValue" SG_ 962 DMS3C2_10_4_VTX_LEFT_UP_Y 4095;
BA_ "GenSigStartValue" SG_ 962 DMS3C2_9_0_VTX_LEFT_UP_X 4095;
BA_ "GenSigStartValue" SG_ 962 DMS3C2_7_4_SLEEPNESS_LEVEL 127;
BA_ "GenSigStartValue" SG_ 962 DMS3C2_6_4_EYE_CLOSE_LEVEL 127;
BA_ "GenSigStartValue" SG_ 962 DMS3C2_5_2_FACE_ANGLE_ROLL 255;
BA_ "GenSigStartValue" SG_ 962 DMS3C2_4_1_FACE_ANGLE_PITCH 255;
BA_ "GenSigStartValue" SG_ 962 DMS3C2_3_0_FACE_ANGLE_YAW 255;
BA_ "GenSigStartValue" SG_ 961 DMS3C1_6_2_PERMIT_AVN_FLAG 1;
BA_ "GenSigStartValue" SG_ 961 DMS3C1_6_7_NOT_DETECTED_STATUS 1;
BA_ "GenSigStartValue" SG_ 961 DMS3C1_4_0_DMS_IND_REQ_FLAG 7;
BA_ "GenSigStartValue" SG_ 961 DMS3C1_4_3_DMS_RECOG_STATUS 1;
BA_ "GenSigSendType" SG_ 957 ACN3BD_3_3_STATE_HT_CIR 3;
BA_ "GenSigSendType" SG_ 957 ACN3BD_3_0_STATE_HT_CIR_SW 3;
BA_ "GenSigSendType" SG_ 957 ACN3BD_1_4_ERR_HTDEV 3;
BA_ "GenSigSendType" SG_ 954 ACN3BA_6_0_ACNDEVICE_FIN 3;
BA_ "GenSigSendType" SG_ 954 ACN3BA_5_3_VOLT_PRT_10WV 3;
BA_ "GenSigSendType" SG_ 954 ACN3BA_5_1_TEMP_PRT_10WV 3;
BA_ "GenSigSendType" SG_ 949 ACN3B5_7_4_BWP_STATE_FS 3;
BA_ "GenSigSendType" SG_ 949 ACN3B5_1_7_STATE_HTWP 3;
VAL_ 1774 CECU6EE_7_0_DESTINATION_INFO 3 "EUROPE_LH" 2 "EUROPE_RH" 1 "DOMESTIC" 0 "US_CANADA" ;
VAL_ 1774 CECU6EE_7_4_VEHICLE_SERIES 7 "NON" 6 "VEHICLE_W" 5 "VEHICLE_V" 4 "VEHICLE_Z" 3 "VEHICLE_S" 2 "VEHICLE_G" 1 "VEHICLE_B" 0 "DEFAULT" ;
VAL_ 1774 CECU6EE_6_0_DESTINATION_CODE 37 "NON" 36 "KR" 35 "KF" 34 "K2" 33 "C6" 32 "U7" 31 "E5" 30 "KG" 29 "E1" 28 "KE" 27 "KP" 26 "EH" 25 "E9" 24 "C4" 23 "KC" 22 "KV" 21 "KY" 20 "KA" 19 "EN" 18 "ER" 17 "EP" 16 "KS" 15 "K4" 14 "E3" 13 "EA" 12 "E7" 11 "ES" 10 "E2" 9 "EE" 8 "EK" 7 "C5" 6 "U5" 5 "EC" 4 "CO" 3 "U4" 2 "JPN" 1 "NON" 0 "DEFAULT" ;
VAL_ 1774 CECU6EE_5_0_EYE_VERSION_INFO 3 "VER4_HEIGHT_DRIVING_ASSIST" 2 "VER4" 1 "NO_EYE" 0 "DEFAULT" ;
VAL_ 1774 CECU6EE_5_4_VEHICLE_TYPE 1 "WGN" 0 "SDN" ;
VAL_ 1774 CECU6EE_5_6_PRODUCTION_BASE 1 "SIA" 0 "DOMESTIC" ;
VAL_ 1774 CECU6EE_4_2_WHEEL_DRIVE_TYPE 1 "4WD" 0 "FF" ;
VAL_ 1774 CECU6EE_4_3_3RD_SHEAT_EQUIPMENT 1 "EQUIPPED" 0 "NO_EQUIPPED" ;
VAL_ 1774 CECU6EE_4_4_FLG_XMODE 3 "X_MODE_2_MODE" 2 "X_MODE_1_MODE" 1 "NO_X_MODE" 0 "DEFAULT" ;
VAL_ 1774 CECU6EE_4_6_ISS_EQUIPMENT 1 "EQUIPPED" 0 "NO_EQUIPPED" ;
VAL_ 1773 CECU6ED_7_0_VEHICLE_TYPE_DETAIL 15 "NON" 14 "NON" 13 "NON" 12 "NON" 11 "NON" 10 "NON" 9 "NON" 8 "NON" 7 "COUPE" 6 "3RD_ROW_SUV" 5 "XUV" 4 "5D" 3 "OUTBACK" 2 "WGN" 1 "SD" 0 "DEFAULT" ;
VAL_ 1773 CECU6ED_5_0_TRANSMISSION_TYPE 1 "MT" 0 "CVT" ;
VAL_ 1773 CECU6ED_5_4_HANDLE 1 "RHD" 0 "LHD" ;
VAL_ 1773 CECU6ED_4_0_VEHICLE_HEIGHT 7 "NON" 6 "LIFT4" 5 "LIFT3" 4 "LIFT2" 3 "Wilderness" 2 "LIFT" 1 "STANDARD" 0 "DEFAULT" ;
VAL_ 1773 CECU6ED_4_4_SEATHEATER_EQUIPMENT 3 "SEAT_HEATER_D_P_REAR" 2 "SEAT_HEATER_D_P" 1 "NOT_SEAT_HEATER" 0 "DEFAULT" ;
VAL_ 1773 CECU6ED_3_0_YEAR_CHANGE 15 "NON" 14 "NON" 13 "NON" 12 "NON" 11 "NON" 10 "9" 9 "8" 8 "7" 7 "6" 6 "5" 5 "4" 4 "3" 3 "2" 2 "1" 1 "0" 0 "DEFAULT" ;
VAL_ 1773 CECU6ED_3_4_HEV_INFO 7 "NON" 6 "NON" 5 "BEV" 4 "SHEV" 3 "MHEV" 2 "PHEV" 1 "CONVE" 0 "DEFAULT" ;
VAL_ 996 CECU3E4_7_0_SSM_COMM_INFO 1 "COMM_ON" 0 "COMM_OFF" ;
VAL_ 996 CECU3E4_6_0_CHARGE_LEVEL_ENG_RUN 9 "level10" 8 "level9" 7 "level8" 6 "level7" 5 "level6" 4 "level5" 3 "level4" 2 "level3" 1 "level2" 0 "level1" ;
VAL_ 996 CECU3E4_6_4_CHARGE_LEVEL_IGN_ON 9 "level10" 8 "level9" 7 "level8" 6 "level7" 5 "level6" 4 "level5" 3 "level4" 2 "level3" 1 "level2" 0 "level1" ;
VAL_ 996 CECU3E4_5_0_GENERATOR_OVER_FLG 3 "EvLoadRestrain2" 2 "EvLoadRestrain1" 1 "Overloaded" 0 "NormalState" ;
VAL_ 996 CECU3E4_5_3_DIAG_COM_REQ 1 "Diag_Com_Request" 0 "No_Request" ;
VAL_ 996 CECU3E4_5_4_HEADS_UP_FLG 1 "ChargeRequest" 0 "Normal" ;
VAL_ 996 CECU3E4_2_7_OCCUPATION_CSTM 1 "D_SEAT" 0 "ALL_SEATS" ;
VAL_ 1280 CGW500_1_4_ActiveWakeUpBit 1 "active wakeup" 0 "passive wakeup" ;
VAL_ 1632 CGW660_1_0_SUB_ID 65535 "NORMAL" ;
VAL_ 1752 DCM6D8_1_4_PRESS_SOS_BUTTON 1 "ON" 0 "OFF" ;
VAL_ 1744 CECU6D0_4_0_OTA_ABORT 1 "OTA中止" 0 "OTA中止でない" ;
VAL_ 1744 CECU6D0_4_1_OTA_SUSPEND 1 "OTA中断" 0 "OTA中断でない" ;
VAL_ 1744 CECU6D0_4_2_OTA_SEQUENCE 33170 "予備" 16534 "予備" 8264 "Campaignなし" 4132 "OTA完了" 1298 "SWID照合中" 598 "電源ON待ち" 296 "電源OFF待ち" 100 "Activate中(Dual)" 50 "Install中(Single)" 22 "アップデート適用開始待ち" 8 "アップデート適用承諾待ち" 4 "Install中(Dual)" 2 "Download中" 1 "Campaign情報取得中" 0 "未実施" ;
VAL_ 1743 DCM6CF_6_6_AACN_FLG 1 "AACN有" 0 "AACN無" ;
VAL_ 1743 DCM6CF_5_0_EMERGENCY_CALL_ON_OFF 1 "Emergency_call_ON" 0 "Emergency_call_OFF" ;
VAL_ 1743 DCM6CF_4_2_STR_HEATER_ON_OFF 1 "Steering_heater_ON" 0 "Steering_heater_OFF" ;
VAL_ 1743 DCM6CF_3_0_RES_CONTRACT_INFO 1 "ON" 0 "OFF" ;
VAL_ 1743 DCM6CF_3_1_REQ_ST_ON 1 "ON" 0 "OFF" ;
VAL_ 1743 DCM6CF_3_3_ON_SIGN 1 "ON" 0 "OFF" ;
VAL_ 1743 DCM6CF_3_5_REQ_PARKLIGHT_HORN 7 "NOT REQUEST" 6 "NOT REQUEST" 5 "NOT REQUEST" 4 "PARK LIGHT ON&HORN OFF" 3 "PARK LIGHT&HORN ANSWER BACK 3 TIME" 2 "PARK LIGHT&HORN ANSWER BACK 2 TIME" 1 "PARK LIGHT&HORN ANSWER BACK 1 TIME" 0 "NOT REQUEST" ;
VAL_ 1743 DCM6CF_2_1_DCM_FAILURE_STATUS 1 "at least one failure is detected" 0 "no failure is detected" ;
VAL_ 1743 DCM6CF_2_2_REQ_WINDOW_STATUS 1 "REQUEST" 0 "NOT_REQUEST" ;
VAL_ 1743 DCM6CF_1_6_DKY_PROV_STS 1 "ON" 0 "OFF" ;
VAL_ 1743 DCM6CF_1_7_PNC_PROV_STS 1 "ON" 0 "OFF" ;
VAL_ 1749 CECU6D5_6_0_CSTM_FMHD 7 "Undefined" 6 "Undefined" 5 "90sec" 4 "60sec" 3 "30sec" 2 "20sec" 1 "10sec" 0 "OFF" ;
VAL_ 1749 CECU6D5_5_0_CSTM_WRH 1 "ON" 0 "OFF" ;
VAL_ 1749 CECU6D5_5_1_CSTM_LMHD 3 "30sec" 2 "20sec" 1 "10sec" 0 "OFF" ;
VAL_ 1749 CECU6D5_5_5_CSTM_HBA 3 "Undefined" 2 "Undefined" 1 "ON" 0 "OFF" ;
VAL_ 1749 CECU6D5_5_7_ADB_ACTIVE 1 "ON" 0 "OFF" ;
VAL_ 1749 CECU6D5_4_0_JUDGE_ILL 1 "YES" 0 "NO" ;
VAL_ 1749 CECU6D5_4_1_HEADLAMP_AUTO_SW 1 "ON" 0 "OFF" ;
VAL_ 1749 CECU6D5_4_2_IND_ACTIVE_HBA 3 "Undefined" 2 "Blink" 1 "ON" 0 "OFF" ;
VAL_ 1749 CECU6D5_4_4_FGT_LGTOFF_WARNING 1 "ON" 0 "OFF" ;
VAL_ 1749 CECU6D5_3_0_CRN_R_REQ 3 "Undefined" 2 "ON" 1 "Faded OFF" 0 "OFF" ;
VAL_ 1749 CECU6D5_3_2_CRN_L_REQ 3 "Undefined" 2 "ON" 1 "Faded OFF" 0 "OFF" ;
VAL_ 1749 CECU6D5_3_4_FMH 1 "ON" 0 "OFF" ;
VAL_ 1749 CECU6D5_3_5_LMH 1 "ON" 0 "OFF" ;
VAL_ 1749 CECU6D5_2_0_LGT_1 1 "ON" 0 "OFF" ;
VAL_ 1749 CECU6D5_2_1_LGT_LO 1 "ON" 0 "OFF" ;
VAL_ 1749 CECU6D5_2_2_LGT_HI 1 "ON" 0 "OFF" ;
VAL_ 1749 CECU6D5_2_4_FFOG_RELAY_REQ 1 "ON" 0 "OFF" ;
VAL_ 1749 CECU6D5_2_5_RFOG_RELAY_REQ 1 "ON" 0 "OFF" ;
VAL_ 1749 CECU6D5_2_6_LGT_DRL 1 "ON" 0 "OFF" ;
VAL_ 1753 CECU6D9_2_2_RCC_BWAM_SETTING 1 "ON" 0 "OFF" ;
VAL_ 1753 CECU6D9_1_4_RCC_FLG 1 "RCC実行中" 0 "RCC停止中" ;
VAL_ 723 CECU2D3_2_5_IGA_STATE 1 "ON" 0 "OFF" ;
VAL_ 723 CECU2D3_2_6_IGB_STATE 1 "ON" 0 "OFF" ;
VAL_ 1747 CECU6D3_3_0_PRE_CONDITIONING 7 "Fail_value" 6 "Reserved" 5 "Reserved" 4 "Departure_Time" 3 "Start_AC" 2 "Start_Temp_Ctrl_Performance" 1 "Start_Temp_Ctrl_Normal" 0 "Initial_value（OFF)" ;
VAL_ 1747 CECU6D3_2_3_BAT_INFO_GET_FLG 1 "ON" 0 "OFF" ;
VAL_ 930 MET3A2_6_0_SEATBELT_RR_RH 1 "ON_BeltOFF" 0 "OFF_BeltON" ;
VAL_ 930 MET3A2_6_1_SEATBELT_RR_CTR 1 "ON_BeltOFF" 0 "OFF_BeltON" ;
VAL_ 930 MET3A2_6_2_SEATBELT_RR_LH 1 "ON_BeltOFF" 0 "OFF_BeltON" ;
VAL_ 930 MET3A2_6_3_SEATBELT_THIRD_RH 1 "ON_BeltOFF" 0 "OFF_BeltON" ;
VAL_ 930 MET3A2_6_4_SEATBELT_THIRD_CTR 1 "ON_BeltOFF" 0 "OFF_BeltON" ;
VAL_ 930 MET3A2_6_5_SEATBELT_THIRD_LH 1 "ON_BeltOFF" 0 "OFF_BeltON" ;
VAL_ 930 MET3A2_5_0_FLG_RR_REMINDER 1 "REAR REMINDER ON" 0 "OFF" ;
VAL_ 930 MET3A2_1_4_FAIL_DISP 3 "Reserve" 2 "Reserve" 1 "MET_FAIL_DISP" 0 "NORMAL" ;
VAL_ 1677 MET68D_7_0_STATUS_WASHER_LAMP 1 "ON" 0 "OFF" ;
VAL_ 1677 MET68D_7_1_OILPRESSURE_SW 1 "SW_GND" 0 "SW_OPEN" ;
VAL_ 1677 MET68D_7_2_FLG_EAM 1 "EAM" 0 "NOT_EAM" ;
VAL_ 1677 MET68D_7_3_CSTM_IND_RED 1 "ON" 0 "OFF" ;
VAL_ 1677 MET68D_7_4_CSTM_IND_YELLOW 1 "ON" 0 "OFF" ;
VAL_ 1677 MET68D_7_5_CSTM_IND_GREEN 1 "ON" 0 "OFF" ;
VAL_ 1677 MET68D_7_6_REQ_CSTM_SRH 1 "required" 0 "NOT required" ;
VAL_ 1677 MET68D_7_7_CSTM_SRH 1 "ON" 0 "OFF" ;
VAL_ 1677 MET68D_6_5_REQ_CHG_CSTM_RAB 1 "required" 0 "NOT required" ;
VAL_ 1677 MET68D_6_6_CSTM_RAB 1 "ON" 0 "OFF" ;
VAL_ 1677 MET68D_6_7_CSTM_SONNER 1 "ON" 0 "OFF" ;
VAL_ 1677 MET68D_1_4_RESET_CSTM_TPMS_RAEB 1 "REQUIRED" 0 "NOT REQUIRED" ;
VAL_ 1677 MET68D_1_5_REQ_CHG_CSTM_TPMS 1 "required" 0 "NOT required" ;
VAL_ 1677 MET68D_1_6_CSTM_TIRE_UNIT 3 "未定義" 2 "bar" 1 "kPa" 0 "psi" ;
VAL_ 915 MET393_7_0_REQ_CHG_CSTM_EYE 1 "required" 0 "NOT required" ;
VAL_ 915 MET393_7_1_REQ_RESET_CSTM_EYE 1 "REQUIRED" 0 "NOT REQUIRED" ;
VAL_ 915 MET393_7_2_CSTM_ALK 1 "ON" 0 "OFF" ;
VAL_ 915 MET393_7_3_CSTM_HBA 1 "SAE_Mode" 0 "Normal" ;
VAL_ 915 MET393_7_4_CSTM_MIS_AT_BACK 3 "ON_FAST" 2 "ON_MIDDLE" 1 "ON_SLOW" 0 "OFF" ;
VAL_ 915 MET393_7_6_CSTM_ACC_CONT 3 "LEV4" 2 "LEV3" 1 "LEV2" 0 "LEV1" ;
VAL_ 915 MET393_5_2_WARN_R_DIFF_TEMP 3 "Turn_ON_Initial_Check" 2 "BLINK" 1 "Turn_ON" 0 "Turn_OFF" ;
VAL_ 915 MET393_5_4_ADAPTIVECC_NOALIVE 1 "NO_ALIVE" 0 "ALIVE" ;
VAL_ 915 MET393_5_5_DUAL_RANGE_LO 1 "SW GND" 0 "SW OPEN" ;
VAL_ 915 MET393_5_6_CSTM_SPD_LIMITER 1 "Control_ON" 0 "Control_OFF" ;
VAL_ 915 MET393_5_7_CSTM_LANE_CONT 1 "LEFT" 0 "RIGHT" ;
VAL_ 915 MET393_3_5_SI_DRIVE_SW 7 "BLANK_NoInput" 6 "I_Input" 5 "ECO-C_Input" 4 "I_Input" 3 "X_MUD_SAND_or_GRAVEL_Input" 2 "S#_Input" 1 "X_SNOW_DIRT_Input" 0 "BLANK_NoInput" ;
VAL_ 915 MET393_1_4_CSTM_IND_BLUE 1 "ON" 0 "OFF" ;
VAL_ 915 MET393_1_5_CSTM_AES_CONT 1 "ON" 0 "OFF" ;
VAL_ 915 MET393_1_6_FLG_PEDESTRIAN_AIRBAG 1 "OEDESTRIAN AIRBAG" 0 "OTHER" ;
VAL_ 912 MET390_7_0_VDC_ON_OFF 3 "BLANK_NoInput" 2 "VDC ON_Input" 1 "VDC OFF_Input" 0 "Neutral" ;
VAL_ 912 MET390_7_2_RR_DOOR_RECORD_L 1 "OPEN" 0 "CLOSE" ;
VAL_ 912 MET390_7_3_RR_DOOR_RECORD_R 1 "OPEN" 0 "CLOSE" ;
VAL_ 912 MET390_7_4_REQ_CHG_CSTM_PSM 1 "required" 0 "NOT required" ;
VAL_ 912 MET390_7_5_REQ_RESET_CSTM_PSM 1 "REQUIRED" 0 "NOT　REQUIRED" ;
VAL_ 912 MET390_7_6_CSTM_MIR_AFOLD_CONT 1 "ON" 0 "OFF" ;
VAL_ 912 MET390_7_7_CSTM_MIR_RTILT_CONT 1 "ON" 0 "OFF" ;
VAL_ 912 MET390_6_0_SEATBELT_DRVR 1 "ON" 0 "OFF" ;
VAL_ 912 MET390_6_1_SEATBELT_PASS 1 "ON" 0 "OFF" ;
VAL_ 912 MET390_6_2_TURN_SIG_LEFT 1 "Turn_L_OutPut" 0 "OFF" ;
VAL_ 912 MET390_6_3_TURN_SIG_RIGHT 1 "Turn_R_OutPut" 0 "OFF" ;
VAL_ 912 MET390_6_4_BRIGHT_SW 1 "ON" 0 "OFF" ;
VAL_ 912 MET390_6_5_FAIL_UART_WA_BOX 1 "FAIL" 0 "NORMAL" ;
VAL_ 912 MET390_6_6_ISS_OFF_SW 1 "While SW is being pushed down." 0 "While SW is not being pushed down." ;
VAL_ 912 MET390_6_7_FLG_DMS 1 "DMS" 0 "NOT_DMS" ;
VAL_ 912 MET390_3_0_UNIT_SPEED_TRIP 1 "MPH、miles" 0 "km/h、km" ;
VAL_ 912 MET390_3_1_FLG_EYESIGHT 1 "EYESIGHT" 0 "OTHER" ;
VAL_ 912 MET390_3_2_FLG_ISS 1 "ISS" 0 "OTHER" ;
VAL_ 912 MET390_3_3_FLG_HEV 1 "HEV" 0 "OTHER" ;
VAL_ 912 MET390_3_4_FLG_IMB 1 "IMB_ACTIVE" 0 "NON_IMB" ;
VAL_ 912 MET390_3_5_TIRE_SIZE 1 "SPECIAL_SIZE" 0 "STANDARD_SIZE" ;
VAL_ 912 MET390_3_6_FLG_XMODE 3 "X_2MODE(GRAVEL)" 2 "X_2MODE" 1 "X_1MODE" 0 "NOT_X" ;
VAL_ 912 MET390_2_0_VEHICLE_SERIES 7 "VEHICLE_Z" 6 "VEHICLE_W" 5 "VEHICLE_V" 4 "VEHICLE_B" 3 "VEHICLE_Y" 2 "VEHICLE_S" 1 "VEHICLE_G" 0 "NON" ;
VAL_ 912 MET390_2_3_DESTINATION 12 "KC" 11 "Korea_C6" 10 "China_EHETES" 9 "Australia_KA" 8 "Singapore_ERENKYKEKVKP" 7 "England_EK" 6 "SaudiArabia_KSKG" 5 "STANDARD_LH_K4E3E5C4" 4 "Europe_LH_ECEAE2EEEPE9E7E1" 3 "CANADA_C5C0" 2 "US_U4U5U6" 1 "DOM" 0 "NON" ;
VAL_ 912 MET390_2_7_PASS_DOOR_RECORD 1 "OPEN" 0 "CLOSE" ;
VAL_ 912 MET390_1_4_WAKE_UP_FRAME 1 "WakeUP_FRAME" 0 "Normal_FRAME" ;
VAL_ 912 MET390_1_5_REQ_COMM_CONT 1 "REQ" 0 "NON_REQ" ;
VAL_ 912 MET390_1_6_DMS_ID_SET 1 "REQUIRED" 0 "NOT REQUIRED" ;
VAL_ 912 MET390_1_7_FAIL_EEPROM 1 "FAIL" 0 "NORMAL" ;
VAL_ 1291 MET50B_1_4_ActiveWakeUpBit 1 "active wakeup" 0 "passive wakeup" ;
VAL_ 28 STA01C_3_4_CODE_ERR 7 "SENSOR_FAIL" 6 "RAM_FAIL" 5 "ROM_FAIL" 4 "COUNTER_OVERFLOW" 3 "IG_POWER_LOW" 2 "EEPROM_FAIL" 1 "NONE" 0 "NORMAL" ;
VAL_ 28 STA01C_3_7_ABS_ANGLE_DETECT 1 "Angles_DETECT" 0 "Angles_NON_DETECT" ;
VAL_ 28 STA01C_2_0_FLG_CALIB 1 "ZERO_DETECT" 0 "ZERO_NON_DETECT" ;
VAL_ 28 STA01C_2_1_FLG_OK 1 "NORMAL" 0 "FAIL" ;
VAL_ 2 STA002_3_0_FLG_MSG_WATCHING 1 "MONITORING" 0 "NONE" ;
VAL_ 2 STA002_2_0_CODE_ERR 7 "SENSOR_FAIL" 6 "RAM_FAIL" 5 "ROM_FAIL" 4 "COUNTER_OVERFLOW" 3 "IG_POWER_LOW" 2 "EEPROM_FAIL" 1 "NONE" 0 "NORMAL" ;
VAL_ 2 STA002_2_4_ABS_ANGLE_DETECT 1 "Angles_DETECT" 0 "Angles_NON_DETECT" ;
VAL_ 2 STA002_2_5_FLG_CALIB 1 "ZERO_DETECT" 0 "ZERO_NON_DETECT" ;
VAL_ 2 STA002_2_6_FLG_OK 1 "NORMAL" 0 "FAIL" ;
VAL_ 1657 TPM679_3_0_STATE_TPMS 3 "MODE_ERROR" 2 "TPMS3" 1 "TPMS2" 0 "TPMS1" ;
VAL_ 1657 TPM679_3_2_DEFINED_STATE_TPMS 3 "UNDER_CONFIRMATION" 2 "THRESHOLD_DECISION" 1 "UNDER_THRESHOLDING" 0 "NOMAL" ;
VAL_ 1657 TPM679_3_4_MODE_SELECT_TPMS 3 "Undefined" 2 "2Mode" 1 "3Mode" 0 "NOMAL" ;
VAL_ 1657 TPM679_2_0_WARN_TPMS 7 "FLASH_ON_1" 6 "FLASH_ON_3" 5 "FLASH_ON_3" 4 "FLASH_ON_2" 3 "FLASH_ON_1" 2 "FLASH_ON_1" 1 "LAMP_ON" 0 "LAMP_OFF" ;
VAL_ 1657 TPM679_2_3_INTERRUPT 2 "SYSTEM_FAIL" 1 "LOW_PRESSURE" 0 "NON_IND" ;
VAL_ 1657 TPM679_2_5_CHECKLUMP_TPMS 1 "LAMP_ON" 0 "LAMP_OFF" ;
VAL_ 827 ABG33B_4_0_PASSENGER_BELT_INFO 3 "MALFUNCTION" 2 "UNSTTLED" 1 "BELTED" 0 "UNBELTED" ;
VAL_ 827 ABG33B_4_2_PASSENGER_DETECT_INFO 7 "RESERVED" 6 "RESERVED" 5 "MALFUNCTION" 4 "UNSETTLED UNSTTLED" 3 "AM50 INCLUDING AM95" 2 "AF05" 1 "CHILD OR CRS (CHILD RESTRAINT SYSTEM)" 0 "NOT OCCUPANT" ;
VAL_ 827 ABG33B_3_0_PPS_STATUS_FAIL_IGN 1 "FAIL" 0 "NORMAL" ;
VAL_ 827 ABG33B_3_1_PPS_STATUS_FAIL_DEV 1 "FAIL" 0 "NORMAL" ;
VAL_ 827 ABG33B_3_2_PPS_STATUS_FAIL_SSR 1 "FAIL" 0 "NORMAL" ;
VAL_ 827 ABG33B_3_3_PPS_STATUS_FAIL_ECU 1 "FAIL" 0 "NORMAL" ;
VAL_ 827 ABG33B_2_0_IND_WARN_PPA 3 "OTHER_FAIL" 2 "RESERVE" 1 "FAIL_Turn_ON" 0 "Turn_OFF" ;
VAL_ 827 ABG33B_2_2_DETECT_CRUSH 7 "RESERVE" 6 "RESERVE" 5 "CRASH DETECTION" 4 "RESERVE" 3 "RESERVE" 2 "RESERVE" 1 "RESERVE" 0 "NORMAL" ;
VAL_ 827 ABG33B_1_4_FLG_PEDESTRIAN_AIRBAG 1 "w PPS" 0 "w/o PPS" ;
VAL_ 826 ABG33A_5_0_P_SIDE_ABG_DEPLOY 1 "ON" 0 "OFF" ;
VAL_ 826 ABG33A_5_1_D_SIDE_ABG_DEPLOY 1 "ON" 0 "OFF" ;
VAL_ 826 ABG33A_5_2_FRONT_FAR_ABG_DEPLOY 1 "ON" 0 "OFF" ;
VAL_ 826 ABG33A_5_3_REAR_FAR_ABG_DEPLOY 1 "ON" 0 "OFF" ;
VAL_ 826 ABG33A_5_4_REAR_RH_ABG_DEPLOY 1 "ON" 0 "OFF" ;
VAL_ 826 ABG33A_5_5_REAR_LH_ABG_DEPLOY 1 "ON" 0 "OFF" ;
VAL_ 826 ABG33A_5_6_P_CURTAIN_ABG_DEPLOY 1 "ON" 0 "OFF" ;
VAL_ 826 ABG33A_5_7_D_CURTAIN_ABG_DEPLOY 1 "ON" 0 "OFF" ;
VAL_ 826 ABG33A_4_0_D_FRONT_ABG_DEPLOY 1 "ON" 0 "OFF" ;
VAL_ 826 ABG33A_4_1_P_FRONT_ABG_DEPLOY 1 "ON" 0 "OFF" ;
VAL_ 826 ABG33A_4_2_P_ABG_DEPLOY 1 "ON" 0 "OFF" ;
VAL_ 826 ABG33A_4_3_D_ABG_DEPLOY 1 "ON" 0 "OFF" ;
VAL_ 826 ABG33A_4_4_P_BELT_PRETENTION 1 "ON" 0 "OFF" ;
VAL_ 826 ABG33A_4_5_D_BELT_PRETENTION 1 "ON" 0 "OFF" ;
VAL_ 826 ABG33A_4_6_D_KNEE_ABG_DEPLOY 1 "ON" 0 "OFF" ;
VAL_ 826 ABG33A_4_7_P_KNEE_ABG_DEPLOY 1 "ON" 0 "OFF" ;
VAL_ 826 ABG33A_3_0_BELT_WRNING_PASS 3 "SW_FAIL" 2 "UNDECIDED" 1 "UNBUCKLED(PASSENGER OCCUPANT)" 0 "BUCKLE OR UNBUCKLED(PASSENGER EMPTY)" ;
VAL_ 826 ABG33A_3_2_BUCKLESW_DRVR 3 "NOT RECEIVED" 2 "INVALID" 1 "BUCKLE SW OFF" 0 "BUCKLE SW ON" ;
VAL_ 826 ABG33A_3_4_OCCUPATION_PASS 3 "SYS_FAIL" 2 "NON" 1 "ACTIVE" 0 "Non_PASSENGER" ;
VAL_ 826 ABG33A_3_6_IND_ACT_ABG_PASS 3 "NON" 2 "ON_IND" 1 "OFF_IND" 0 "ON_IND and OFF_IND" ;
VAL_ 826 ABG33A_2_0_IND_WARN_ABG 3 "OTHER_FAIL" 2 "RESERVE" 1 "FAIL_Turn_ON" 0 "Turn_OFF" ;
VAL_ 826 ABG33A_2_2_DETECT_CRUSH 7 "RESERVE" 6 "RESERVE" 5 "CRUSH_DETECT" 4 "RESERVE" 3 "RESERVE" 2 "RESERVE" 1 "RESERVE" 0 "NORMAL" ;
VAL_ 826 ABG33A_2_5_STATUS_CRUSH_ECALL 7 "RESERVE" 6 "RESERVE" 5 "REAR COLLISION" 4 "ROLLOVER" 3 "RIGHT SIDE COLLISION" 2 "LEFT SIDE COLLISION" 1 "FRONTAL COLLISION" 0 "NORMAL" ;
VAL_ 826 ABG33A_1_4_FLG_ABGIND_CTRL 1 "ACTIVE_PassengerSeat IND contorol" 0 "NON_PassengerSeat IND contorol" ;
VAL_ 826 ABG33A_1_5_REQ_COMM_CONT 1 "REQ" 0 "NON_REQ" ;
VAL_ 826 ABG33A_1_6_COLLISION_COUNTER 3 "RESERVD" 2 "MORE THAN ONCE" 1 "ONECE" 0 "NORMAL" ;
VAL_ 1315 ABG523_1_4_ActiveWakeUpBit 1 "active wakeup" 0 "passive wakeup" ;
VAL_ 962 DMS3C2_26_0_FACIAL_EXPRESSION 3 "NEAGTIVE" 2 "POSITIVE" 1 "NEUTRAL" 0 "UNKNOWN" ;
VAL_ 962 DMS3C2_8_3_FACE_CONF_FLAG 1 "FACE_DETECT_CONF" 0 "FACE_DETECT_DEFAULT" ;
VAL_ 962 DMS3C2_7_3_EYE_CLS_CONF_FLAG 1 "EYE_CLOSURE_CONF" 0 "EYE_CLOSURE_DEFAULT" ;
VAL_ 962 DMS3C2_6_3_FACE_AGL_CONF_FLAG 1 "FACE_ANGLE_CONF" 0 "FACE_ANGLE_DEFAULT" ;
VAL_ 961 DMS3C1_7_4_SHORT_DIST_DETECT 1 "SHORT_DIST_DETECT" 0 "NO_SHORT_DIST_DETECT" ;
VAL_ 961 DMS3C1_7_5_PRESENCE_DETECT 1 "PRESENCE" 0 "NO_PRESENCE" ;
VAL_ 961 DMS3C1_7_6_RADER_EQUIP 1 "RADAR_EQUIP" 0 "NO_RADAR_EQUIP" ;
VAL_ 961 DMS3C1_7_7_LOSING_POSTURE_DETECT 1 "LOSING_POSTURE" 0 "NO_LOSING_POSTURE" ;
VAL_ 961 DMS3C1_6_0_ID_RECOG_CANCEL 1 "ID_RECOG_CANCEL" 0 "DEFAULT" ;
VAL_ 961 DMS3C1_6_1_ID_ENABLE_FLAG 1 "ID_VALID" 0 "ID_INVALID" ;
VAL_ 961 DMS3C1_6_2_PERMIT_AVN_FLAG 1 "PERMIT" 0 "PROHIBIT" ;
VAL_ 961 DMS3C1_6_4_DISTRACTION_STATUS 1 "DISTRACTION" 0 "DEFAULT" ;
VAL_ 961 DMS3C1_6_5_DROWSINESS_STATUS 1 "DROWSINESS" 0 "DEFAULT" ;
VAL_ 961 DMS3C1_6_6_DROWSINESS_LV2_STATUS 1 "DROWSINESS_LEVEL2" 0 "DEFAULT" ;
VAL_ 961 DMS3C1_6_7_NOT_DETECTED_STATUS 1 "NOT_DETECTED" 0 "DETECTED" ;
VAL_ 961 DMS3C1_5_0_ID_LIST 31 "ID_1_2_3_4_5" 1 "ID_1" 0 "DEFAULT" ;
VAL_ 961 DMS3C1_5_5_ID_EDIT_FLAG 6 "REQ_ID_DEL_ALL" 5 "REQ_CUST_DEL_DELECT" 4 "REQ_ID_DEL_DELECT" 3 "REQ_ID_CUST_EDIT" 2 "REQ_ID_REGIST" 0 "DEFAULT" ;
VAL_ 961 DMS3C1_4_0_DMS_IND_REQ_FLAG 7 "UNDEFINED" 5 "FAULT_IND" 4 "HALT_IND" 3 "OFF_IND" 2 "ID_DEF_IND" 1 "ID_UNDEF_IND" 0 "DEFAULT" ;
VAL_ 961 DMS3C1_4_3_DMS_RECOG_STATUS 1 "IDENTIFING_ON" 0 "IDENTIFING_OFF" ;
VAL_ 961 DMS3C1_4_4_DRIVER_STATUS 3 "DRV_GLASSES" 2 "DRV_MASK" 1 "DRV_NORMAL" 0 "DEFAULT" ;
VAL_ 961 DMS3C1_3_0_DRIVER_REGIST_ID 15 "IDENTIFING" 14 "ALL_ID" 5 "ID_5" 4 "ID_4" 3 "ID_3" 2 "ID_2" 1 "ID_1" 0 "DEFAULT" ;
VAL_ 961 DMS3C1_3_4_CUST_EDIT_FLAG 3 "REQ_CUST_FAIL" 2 "REQ_CUST_COMP" 1 "REQ_CUST_PRESENT" 0 "DEFAULT" ;
VAL_ 961 DMS3C1_3_6_ID_RECOG_FLAG 1 "ID_DEFINED" 0 "ID_UNDIFINED" ;
VAL_ 961 DMS3C1_2_0_LEVEL_DROWS 2 "DROWS_LEVEL2" 1 "DROWS_LEVEL1" 0 "NO_DROWSINESS" ;
VAL_ 961 DMS3C1_2_3_DROWS_DETECT_FLAG 1 "DROWS_DETECT" 0 "NO_DROWS_DETECT" ;
VAL_ 961 DMS3C1_2_7_DIST_DETECT_FLAG 1 "DIST_DETECT" 0 "NO_DIST_DETECT" ;
VAL_ 961 DMS3C1_1_4_WAKE_UP_FRAME 1 "WakeUP_FRAME" 0 "Normal_FRAME" ;
VAL_ 961 DMS3C1_1_5_REQ_COMM_CONT 1 "REQUEST" 0 "NO_REQUEST" ;
VAL_ 961 DMS3C1_1_7_EYE_DIST_FLAG 1 "EYE_DIST_DETECT" 0 "NO_DETECT" ;
VAL_ 1290 DMS50A_1_4_ActiveWakeUpBit 1 "active wakeup" 0 "passive wakeup" ;
VAL_ 1651 ACN673_7_2_REQ_STRG_H 3 "NO_DIFINITION" 2 "LOW" 1 "HIGH" 0 "OFF" ;
VAL_ 1651 ACN673_7_1_SEAT_H_L_AUTOIND 1 "ON" 0 "OFF" ;
VAL_ 1651 ACN673_7_0_SEAT_H_R_AUTOIND 1 "ON" 0 "OFF" ;
VAL_ 1651 ACN673_6_0_RR_FAN_SYMBOL 1 "ON" 0 "OFF" ;
VAL_ 1651 ACN673_6_2_SEAT_H_R 7 "VENT HI" 6 "VENT MI" 5 "VENT LO" 4 "UNDEFINED" 3 "HEATER HI" 2 "HEATER MI" 1 "HEATER LO" 0 "OFF" ;
VAL_ 1651 ACN673_6_5_SEAT_H_L 7 "VENT HI" 6 "VENT MI" 5 "VENT LO" 4 "UNDEFINED" 3 "HEATER HI" 2 "HEATER MI" 1 "HEATER LO" 0 "OFF" ;
VAL_ 1651 ACN673_5_0_DR_ONLY 3 "ALL" 2 "FRONT" 1 "DRIVER" 0 "BLANK" ;
VAL_ 1651 ACN673_5_4_AC_SI_DS_SET 3 "Reserve" 2 "Normal" 1 "Mild" 0 "Invalid" ;
VAL_ 1651 ACN673_5_6_STRG_H_AUTOIND 1 "ON" 0 "OFF" ;
VAL_ 1651 ACN673_5_7_AC_SI_DS_FLG 1 "WITH" 0 "WITHOUT" ;
VAL_ 1651 ACN673_4_0_SEAT_HEATER_DR 3 "3段" 2 "2段" 1 "1段" 0 "OFF" ;
VAL_ 1651 ACN673_4_2_SEAT_HEATER_PA 3 "3段" 2 "2段" 1 "1段" 0 "OFF" ;
VAL_ 1651 ACN673_4_4_SEAT_HEATER 1 "有り" 0 "なし" ;
VAL_ 1651 ACN673_4_5_TEMP_SET_TYPE 3 "不使用" 2 "華氏" 1 "欧州摂氏" 0 "欧州摂氏以外" ;
VAL_ 1651 ACN673_4_7_VENTI_SEAT_EX_HI 1 "ON" 0 "OFF" ;
VAL_ 1651 ACN673_1_6_SYNC_RR 1 "ON" 0 "OFF" ;
VAL_ 1651 ACN673_1_7_RR_LOCK 1 "ON" 0 "OFF" ;
VAL_ 1650 ACN672_6_0_DEF 1 "ON" 0 "OFF" ;
VAL_ 1650 ACN672_6_1_FAN_SYMBOL 1 "ON" 0 "OFF" ;
VAL_ 1650 ACN672_6_2_REAR_MODE 3 "FOOT" 2 "B/L" 1 "VENT" 0 "BLANK" ;
VAL_ 1650 ACN672_6_4_UNIT_TEMP 1 "deg F" 0 "deg C" ;
VAL_ 1650 ACN672_6_5_SPEC_AC_UNIT 3 "DUAL" 2 "SINGLE" 1 "MANU" 0 "LESS" ;
VAL_ 1650 ACN672_6_7_REAR_AC 1 "WITH" 0 "WITHOUT" ;
VAL_ 1650 ACN672_5_0_AC_VR_MODE 3 "No_Definition" 2 "VOICE_MODE_ERROR" 1 "VOICE_MODE_ON" 0 "OFF" ;
VAL_ 1650 ACN672_4_0_AC_INTERRUPT_DISPLAY 1 "ON" 0 "OFF" ;
VAL_ 1650 ACN672_4_1_AC_VR_ACTION 1 "INVALID" 0 "NORMAL" ;
VAL_ 1650 ACN672_3_0_MAX_AC 1 "ON" 0 "OFF" ;
VAL_ 1650 ACN672_3_1_INFO_SYNC_OR_SING 1 "ON" 0 "OFF" ;
VAL_ 1650 ACN672_3_2_INFO_FULL_OR_AUTO 3 "NONE" 2 "FULL_AUTO" 1 "AUTO" 0 "BLANK" ;
VAL_ 1650 ACN672_3_4_INFO_AC_ON 1 "ON" 0 "OFF" ;
VAL_ 1650 ACN672_3_5_INFO_RDEF 1 "ON" 0 "OFF" ;
VAL_ 1650 ACN672_3_6_INFO_CIRCULATION 3 "TURN_ON_ALL" 2 "Outside Air" 1 "Recirculation" 0 "TURN_OFF" ;
VAL_ 1650 ACN672_2_0_INFO_MODE_VENT 15 "ALL" 7 "ALL FLOW" 6 "DEF" 5 "FOOT/DEF" 4 "FOOT" 3 "B/L" 2 "VENTⅡ" 1 "VENT" 0 "BLANK" ;
VAL_ 1650 ACN672_2_5_INFO_LEV_BLOWERFAN 7 "HI" 6 "M5" 5 "M4" 4 "M3" 3 "M2" 2 "M1" 1 "LO" 0 "OFF" ;
VAL_ 1650 ACN672_1_4_LVL_BLOWERFAN_RR 7 "HI" 6 "M5" 5 "M4" 4 "M3" 3 "M2" 2 "M1" 1 "LO" 0 "OFF" ;
VAL_ 1650 ACN672_1_7_REAR_AUTO 1 "AUTO" 0 "BLANK" ;
VAL_ 722 ACN2D2_5_0_REQ_ENG_RPM 6 "HOT_LOLO (ME2-H/BF4)" 5 "HOT_Mi (ME2-H/BF4)" 4 "HOT_LO" 3 "COOL_LO" 2 "HOT_HI" 1 "COOL_HI" 0 "NON_REQ" ;
VAL_ 722 ACN2D2_4_0_LVL_PTC 3 "3RD" 2 "2ND" 1 "1ST" 0 "OFF" ;
VAL_ 722 ACN2D2_4_2_MARGIN_OF_AC 7 "7" 6 "6" 5 "5" 4 "4" 3 "3" 2 "2" 1 "1" 0 "0" ;
VAL_ 722 ACN2D2_4_5_LVL_BLOWER_FAN 7 "HI(AS1)/NONE(Other)" 6 "M5(AS1)/HI(Other)" 5 "M4" 4 "M3" 3 "M2/BLW_ON" 2 "M1" 1 "LO" 0 "OFF" ;
VAL_ 722 ACN2D2_3_0_PERMIT_ISS 3 "INHIBIT" 2 "PERMIT" 1 "PERMIT" 0 "PERMIT" ;
VAL_ 722 ACN2D2_3_2_TRQ_PAT_COMP_ESTM 6 "Pattern6" 5 "Pattern5" 4 "Pattern4" 3 "Pattern3" 2 "Pattern2" 1 "Pattern1" 0 "DEFAULT" ;
VAL_ 722 ACN2D2_3_5_IND_ROOM_TEMP 4 "40≦TR" 3 "30≦TR<40" 2 "20≦TR<30" 1 "10≦TR<20" 0 "<10" ;
VAL_ 722 ACN2D2_2_0_FAIL_TRQ_COMP_ESTM 1 "FAIL" 0 "NORMAL" ;
VAL_ 722 ACN2D2_2_1_FAIL_AC 1 "FAIL" 0 "NORMAL" ;
VAL_ 722 ACN2D2_2_2_REQ_INHIBIT_LOCKUP 1 "INHIBIT" 0 "PERMIT" ;
VAL_ 722 ACN2D2_2_3_AC_ON 1 "ON" 0 "OFF" ;
VAL_ 722 ACN2D2_2_4_RDEFOGSW 1 "ON" 0 "OFF" ;
VAL_ 722 ACN2D2_2_5_WARM_UP 1 "WARM_UP" 0 "WARM_UP_OUT" ;
VAL_ 722 ACN2D2_2_6_AC_AUTO_MANUAL 1 "Auto" 0 "Manu" ;
VAL_ 722 ACN2D2_2_7_COMP_TYPE 1 "VAR_COMP" 0 "FIX_COMP" ;
VAL_ 722 ACN2D2_1_7_WARM_POWER_CONT 1 "ON" 0 "OFF" ;
VAL_ 1667 ACN683_3_2_AC_DEFALTSET 1 "DEFALTSET" 0 "NO DEFALTSET" ;
VAL_ 1667 ACN683_3_0_RCC_ACN_RES 3 "NO_DIFINITION" 2 "ERROR" 1 "SUCCESS" 0 "UNDECIDED" ;
VAL_ 1667 ACN683_2_7_JUDGE_FANONLY 1 "OK" 0 "NG" ;
VAL_ 1667 ACN683_2_6_CSTM_LINK_SEAT_R 1 "ON" 0 "OFF" ;
VAL_ 957 ACN3BD_4_0_STATE_HT_ACT 3 "NO_DIFINITION" 2 "INACTIVE" 1 "ACTIVE" 0 "UNDECIDED" ;
VAL_ 957 ACN3BD_3_3_STATE_HT_CIR 4 "HT-ZY_ヒータコア有り_水水HEX有り" 3 "HT-ZX_ヒータコア無し_水水HEX有り" 2 "HT-Y_ヒータコア有り" 1 "HT-X_ヒータコア無し" 0 "移行要求無し" ;
VAL_ 957 ACN3BD_3_0_STATE_HT_CIR_SW 4 "エラー" 3 "切替完" 2 "切替中" 1 "待機" 0 "未確定" ;
VAL_ 957 ACN3BD_1_4_ERR_HTDEV 7 "異常＋確定故障" 6 "異常＋仮故障" 5 "正常+確定故障" 4 "正常+仮故障" 3 "正常+無し" 2 "未確定+確定故障" 1 "未確定＋仮故障" 0 "未確定(現在)+無し(確定)" ;
VAL_ 954 ACN3BA_6_0_ACNDEVICE_FIN 1 "FINISHED" 0 "UNFININISHED" ;
VAL_ 954 ACN3BA_5_3_VOLT_PRT_10WV 3 "正常" 2 "高電圧保護" 1 "低電圧保護" 0 "未確定" ;
VAL_ 954 ACN3BA_5_1_TEMP_PRT_10WV 3 "未使用" 2 "正常" 1 "高温保護" 0 "未確定" ;
VAL_ 954 ACN3BA_3_5_V_ERR_10WV 3 "未使用" 2 "異常" 1 "正常" 0 "未確定" ;
VAL_ 954 ACN3BA_3_3_CR_ERR_10WV 3 "未使用" 2 "異常" 1 "正常" 0 "未確定" ;
VAL_ 954 ACN3BA_3_1_ERR_CL 3 "異常" 2 "仮異常" 1 "正常" 0 "未確定" ;
VAL_ 954 ACN3BA_1_6_INI_10WV 3 "エラー" 2 "イニシャライズ完了" 1 "イニシャライズ中" 0 "不定" ;
VAL_ 954 ACN3BA_1_4_INFO_10WV 3 "未使用" 2 "異常" 1 "正常" 0 "未確定" ;
VAL_ 1659 ACN67B_6_0_STATE_INW 1 "ACTIVE" 0 "INACTIVE" ;
VAL_ 1659 ACN67B_5_2_JUDGE_OIL_SALVAGE 3 "NO_DIFINITION" 2 "NEED" 1 "WANT" 0 "NO NEED" ;
VAL_ 1659 ACN67B_5_0_OIL_SALVAGE_READY 1 "READY" 0 "UNREADY" ;
VAL_ 1659 ACN67B_4_3_STATE_ACLOAD 7 "NO_DIFINITION" 6 "NO_DIFINITION" 5 "NO_DIFINITION" 4 "COOLING" 3 "HEATING" 2 "DEHUMIDIFYING" 1 "DEF" 0 "NON" ;
VAL_ 1659 ACN67B_4_2_REQ_LT_DEF 1 "あり" 0 "なし" ;
VAL_ 1659 ACN67B_4_1_REQ_HT_RAD 1 "放熱要求有り" 0 "放熱要求無し" ;
VAL_ 1659 ACN67B_4_0_STATE_BATHP 1 "吸熱可" 0 "吸熱否" ;
VAL_ 1659 ACN67B_3_4_REQ_ACCYC 4 "NO_DIFINITION" 3 "DEHU. HEATING" 2 "HEATING" 1 "COOLING" 0 "OFF" ;
VAL_ 1659 ACN67B_3_3_JUDGE_AMBHP 1 "POSSIBLE" 0 "IMPOSSIBLE" ;
VAL_ 1659 ACN67B_3_1_RL_LTO 3 "正常" 2 "異常" 1 "仮異常" 0 "未確定" ;
VAL_ 1659 ACN67B_1_7_JUDGE_LTHP 1 "可能" 0 "不可" ;
VAL_ 1659 ACN67B_1_6_HTS_BAT_COMB 1 "不足" 0 "充足" ;
VAL_ 1659 ACN67B_1_5_HTS_AC_ALONE 1 "不足" 0 "充足" ;
VAL_ 1659 ACN67B_1_4_PERMIT_TL 1 "許可" 0 "禁止" ;
VAL_ 949 ACN3B5_7_4_BWP_STATE_FS 12 "NO_DIFINITION" 11 "SLIPPING" 10 "HI_SPEED_STEP-OUT" 9 "MOTOR_LOCK" 8 "SHORT_TO_BATTERY" 7 "EARTH_FAULT" 6 "OVERCURRENT" 5 "HI_TEMPERATURE_SHUTDOWN" 4 "HI_TEMPERATURE" 3 "OVERVOLTAGE" 2 "LO_VOLTAGE" 1 "NORMAL_OPERATION　" 0 "NORMAL_STOP" ;
VAL_ 949 ACN3B5_5_4_RL_DE_CLO 3 "未使用" 2 "正常" 1 "異常(偏差)" 0 "未確定" ;
VAL_ 949 ACN3B5_5_1_RL_WC_CLO 7 "未使用" 6 "未使用" 5 "未使用" 4 "正常" 3 "仮異常" 2 "異常(結線HI)" 1 "異常(結線LO)" 0 "未確定" ;
VAL_ 949 ACN3B5_3_6_STATE_TW_CL 3 "NO_DIFINITION" 2 "SUCTION REFRIGERANT STABILIZING" 1 "AIR TEMP STABILIZING" 0 "INACTIVE" ;
VAL_ 949 ACN3B5_1_7_STATE_HTWP 1 "作動" 0 "非作動" ;
VAL_ 949 ACN3B5_1_4_WC_ERR_BWP 3 "未使用" 2 "正常" 1 "異常(結線)" 0 "未確定" ;
